VERSION ""

NS_ :

BS_:

BU_: APIM_CISM APIM ESPM DSP FCIMB RACM_RCIM HUD_ADV WCM TRM_ITRM ACM GWM _delete IPC GENERIC TSTR

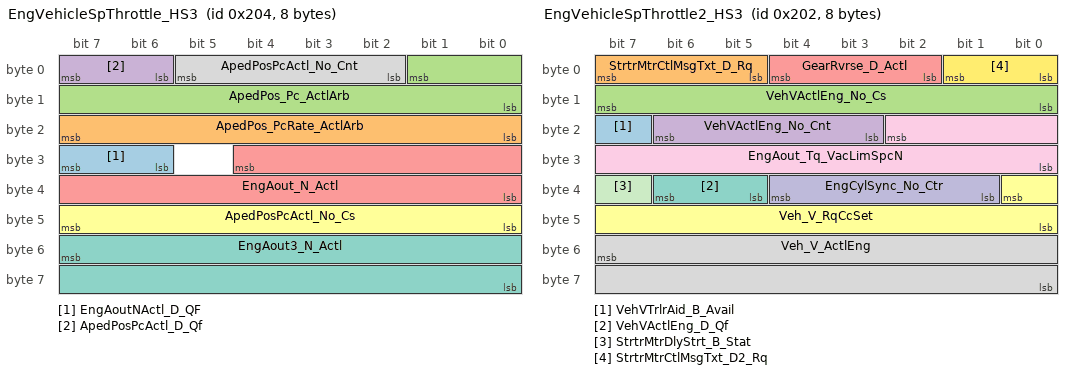
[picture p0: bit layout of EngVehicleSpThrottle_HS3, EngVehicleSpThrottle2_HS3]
BO_ 516 EngVehicleSpThrottle_HS3: 8 GWM
 SG_ EngAoutNActl_D_QF : 31|2@0+ (1,0) [0|3] "SED"  GENERIC
 SG_ ApedPos_PcRate_ActlArb : 23|8@0+ (0.04,-5) [-5|5.12] "%/ms"  APIM_CISM,ACM
 SG_ ApedPos_Pc_ActlArb : 1|10@0+ (0.1,0) [0|102.3] "%"  APIM,APIM_CISM,ACM
 SG_ ApedPosPcActl_D_Qf : 7|2@0+ (1,0) [0|3] "SED"  ACM
 SG_ EngAout_N_Actl : 28|13@0+ (2,0) [0|16382] "rpm"  APIM,APIM_CISM,DSP,ACM,IPC
 SG_ ApedPosPcActl_No_Cs : 47|8@0+ (1,0) [0|255] "unitless"  GENERIC
 SG_ EngAout3_N_Actl : 55|16@0+ (0.25,0) [0|16383.5] "RPM"  GENERIC
 SG_ ApedPosPcActl_No_Cnt : 5|4@0+ (1,0) [0|15] "unitless"  GENERIC

BO_ 514 EngVehicleSpThrottle2_HS3: 8 GWM
 SG_ VehVTrlrAid_B_Avail : 23|1@0+ (1,0) [0|1] "SED"  GENERIC
 SG_ StrtrMtrCtlMsgTxt_D_Rq : 7|3@0+ (1,0) [0|7] "SED"  IPC
 SG_ VehVActlEng_No_Cs : 15|8@0+ (1,0) [0|255] "unitless"  GENERIC
 SG_ VehVActlEng_No_Cnt : 22|4@0+ (1,0) [0|15] "unitless"  GENERIC
 SG_ GearRvrse_D_Actl : 4|3@0+ (1,0) [0|7] "SED"  APIM,HUD_ADV,APIM_CISM,IPC
 SG_ Veh_V_RqCcSet : 32|9@0+ (0.5,0) [0|255.5] "kph"  IPC
 SG_ VehVActlEng_D_Qf : 38|2@0+ (1,0) [0|3] "SED"  APIM,APIM_CISM,WCM,DSP,ACM,IPC
 SG_ Veh_V_ActlEng : 55|16@0+ (0.01,0) [0|655.35] "kph"  APIM,APIM_CISM,WCM,DSP,TRM_ITRM,ACM,IPC
 SG_ EngAout_Tq_VacLimSpcN : 18|11@0+ (1,-500) [-500|1547] "Nm"  GENERIC
 SG_ EngCylSync_No_Ctr : 36|4@0+ (1,0) [0|15] "unitless"  GENERIC
 SG_ StrtrMtrDlyStrt_B_Stat : 39|1@0+ (1,0) [0|1] "SED"  GENERIC
 SG_ StrtrMtrCtlMsgTxt_D2_Rq : 1|2@0+ (1,0) [0|3] "SED"  IPC

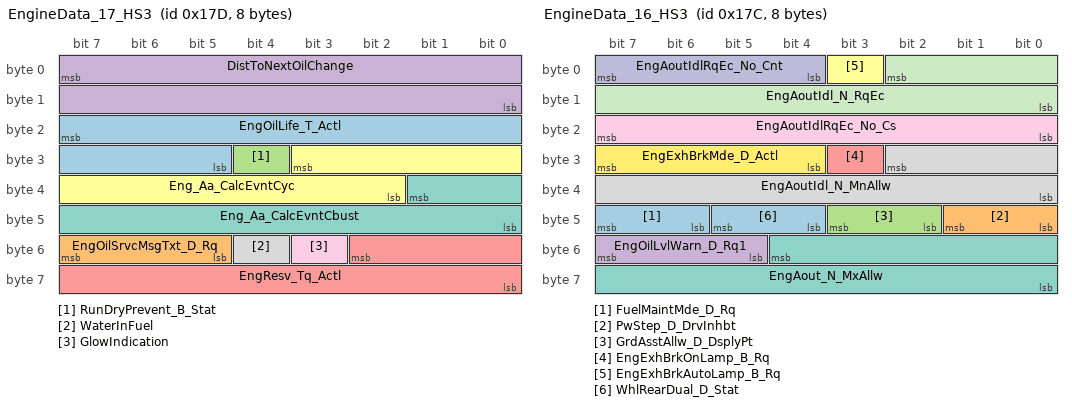
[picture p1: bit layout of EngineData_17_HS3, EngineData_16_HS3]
BO_ 381 EngineData_17_HS3: 8 GWM
 SG_ EngOilLife_T_Actl : 23|11@0+ (1,0) [0|2047] "day"  IPC
 SG_ EngOilSrvcMsgTxt_D_Rq : 55|3@0+ (1,0) [0|7] "SED"  APIM_CISM,IPC
 SG_ RunDryPrevent_B_Stat : 28|1@0+ (1,0) [0|1] "SED"  APIM_CISM,IPC
 SG_ DistToNextOilChange : 7|16@0+ (1,0) [0|65535] "unitless"  IPC
 SG_ EngResv_Tq_Actl : 50|11@0+ (1,-500) [-500|1547] "Nm"  IPC
 SG_ Eng_Aa_CalcEvntCyc : 27|10@0+ (0.05,-25.6) [-25.6|25.55] "rpm/ms"  IPC
 SG_ Eng_Aa_CalcEvntCbust : 33|10@0+ (0.05,-25.6) [-25.6|25.55] "rpm/ms"  IPC
 SG_ WaterInFuel : 52|1@0+ (1,0) [0|1] "SED"  IPC
 SG_ GlowIndication : 51|1@0+ (1,0) [0|1] "SED"  IPC

BO_ 380 EngineData_16_HS3: 8 GWM
 SG_ FuelMaintMde_D_Rq : 47|2@0+ (1,0) [0|3] "SED"  GENERIC
 SG_ PwStep_D_DrvInhbt : 41|2@0+ (1,0) [0|3] "SED" Vector__XXX
 SG_ GrdAsstAllw_D_DsplyPt : 43|2@0+ (1,0) [0|3] "SED"  IPC
 SG_ EngOilLvlWarn_D_Rq1 : 55|3@0+ (1,0) [0|7] "SED"  IPC
 SG_ EngExhBrkOnLamp_B_Rq : 27|1@0+ (1,0) [0|1] "SED"  IPC
 SG_ EngExhBrkAutoLamp_B_Rq : 3|1@0+ (1,0) [0|1] "SED"  IPC
 SG_ EngAout_N_MxAllw : 52|13@0+ (2,0) [0|16382] "rpm"  IPC
 SG_ EngAoutIdl_N_MnAllw : 26|11@0+ (2,0) [0|4094] "rpm"  IPC
 SG_ EngAoutIdlRqEc_No_Cs : 23|8@0+ (1,0) [0|255] "Unitless"  GENERIC
 SG_ EngAoutIdlRqEc_No_Cnt : 7|4@0+ (1,0) [0|15] "Unitless"  GENERIC
 SG_ EngAoutIdl_N_RqEc : 2|11@0+ (2,0) [0|4094] "rpm"  IPC
 SG_ EngExhBrkMde_D_Actl : 31|4@0+ (1,0) [0|15] "SED"  IPC
 SG_ WhlRearDual_D_Stat : 45|2@0+ (1,0) [0|3] "SED"  GENERIC

BO_ 377 EngineData_7_HS3: 8 GWM
 SG_ TrnManShif_D_IndDrv : 7|3@0+ (1,0) [0|7] "unitless"  HUD_ADV,IPC
 SG_ HvacAirFullOut_B_Rq : 23|1@0+ (1,0) [0|1] "SED"  GENERIC
 SG_ EngFuelCutFull_B_Inhbt : 22|1@0+ (1,0) [0|1] "SED"  IPC
 SG_ EngDecelFuelCut_B_Allw : 21|1@0+ (1,0) [0|1] "SED"  IPC
 SG_ EngAout_Tq_Actl : 2|11@0+ (1,-500) [-500|1547] "Nm"  APIM,APIM_CISM,ACM
 SG_ TrnManShifGear_D_IndDrv : 54|3@0+ (1,0) [0|7] "SED"  HUD_ADV,IPC
 SG_ FuelFlw_Vl_Dsply : 49|10@0+ (25,0) [0|25575] "Micro_Liter"  APIM,APIM_CISM,IPC
 SG_ FuelFillInlet_B_Dsply : 32|1@0+ (1,0) [0|1] "SED"  IPC
 SG_ EngSrvcRqd_B_Rq : 19|1@0+ (1,0) [0|1] "SED"  IPC
 SG_ OdoCount : 47|8@0+ (0.2,0) [0|50.8] "Meters"  APIM,APIM_CISM,IPC
 SG_ EngOilLife_Pc_Actl : 39|7@0+ (1,0) [0|100] "percent"  APIM,APIM_CISM,IPC
 SG_ EngTqSlwDly_T_Est : 18|11@0+ (1,0) [0|2047] "ms"  IPC
 SG_ TrnKickDown_B_RqDrv : 20|1@0+ (1,0) [0|1] "SED"  IPC
 SG_ FuelFilterLamp_B_Dsply : 50|1@0+ (1,0) [0|1] "SED"  IPC
 SG_ AirCondRec_B_Rq : 55|1@0+ (1,0) [0|1] "SED"  IPC
 SG_ AirCondClutch_B_Stats : 51|1@0+ (1,0) [0|1] "SED"  WCM,IPC
 SG_ EngAoutTqActl_D_Qf : 4|2@0+ (1,0) [0|3] "SED" Vector__XXX

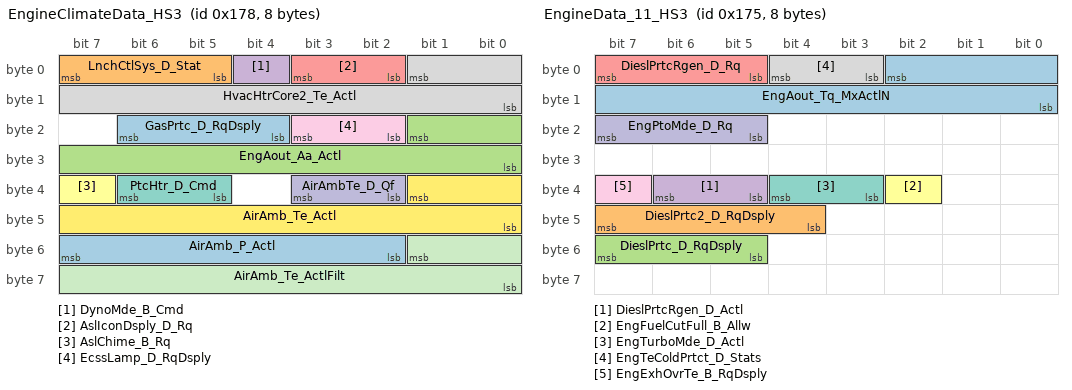
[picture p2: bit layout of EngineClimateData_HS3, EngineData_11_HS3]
BO_ 376 EngineClimateData_HS3: 8 GWM
 SG_ GasPrtc_D_RqDsply : 22|3@0+ (1,0) [0|7] "SED"  IPC
 SG_ LnchCtlSys_D_Stat : 7|3@0+ (1,0) [0|7] "SED"  IPC
 SG_ EngAout_Aa_Actl : 17|10@0+ (0.05,-25.6) [-25.6|25.55] "rpm/ms"  GENERIC
 SG_ DynoMde_B_Cmd : 4|1@0+ (1,0) [0|1] "SED"  GENERIC
 SG_ AslIconDsply_D_Rq : 3|2@0+ (1,0) [0|3] "SED"  APIM,APIM_CISM,IPC
 SG_ AslChime_B_Rq : 39|1@0+ (1,0) [0|1] "SED"  IPC
 SG_ PtcHtr_D_Cmd : 38|2@0+ (1,0) [0|3] "SED"  GENERIC
 SG_ HvacHtrCore2_Te_Actl : 1|10@0+ (0.25,-50) [-50|205.5] "degC"  IPC
 SG_ EcssLamp_D_RqDsply : 19|2@0+ (1,0) [0|3] "SED"  IPC
 SG_ AirAmbTe_D_Qf : 35|2@0+ (1,0) [0|3] "SED"  IPC
 SG_ AirAmb_Te_ActlFilt : 49|10@0+ (0.25,-128) [-128|127.75] "degC"  IPC
 SG_ AirAmb_Te_Actl : 33|10@0+ (0.25,-128) [-128|127.75] "degC"  IPC
 SG_ AirAmb_P_Actl : 55|6@0+ (10,500) [500|1110] "mbar"  APIM,APIM_CISM,IPC

BO_ 373 EngineData_11_HS3: 8 GWM
 SG_ EngAout_Tq_MxActlN : 2|11@0+ (1,-500) [-500|1547] "Nm" Vector__XXX
 SG_ DieslPrtc2_D_RqDsply : 47|4@0+ (1,0) [0|15] "SED"  APIM_CISM,IPC
 SG_ DieslPrtc_D_RqDsply : 55|3@0+ (1,0) [0|7] "SED"  APIM_CISM,IPC
 SG_ DieslPrtcRgen_D_Actl : 38|2@0+ (1,0) [0|3] "SED"  IPC
 SG_ DieslPrtcRgen_D_Rq : 7|3@0+ (1,0) [0|7] "SED"  APIM_CISM,IPC
 SG_ EngFuelCutFull_B_Allw : 34|1@0+ (1,0) [0|1] "SED"  GENERIC
 SG_ EngTurboMde_D_Actl : 36|2@0+ (1,0) [0|3] "SED"  IPC
 SG_ EngTeColdPrtct_D_Stats : 4|2@0+ (1,0) [0|3] "SED"  IPC
 SG_ EngExhOvrTe_B_RqDsply : 39|1@0+ (1,0) [0|1] "SED"  IPC
 SG_ EngPtoMde_D_Rq : 23|3@0+ (1,0) [0|7] "SED"  IPC

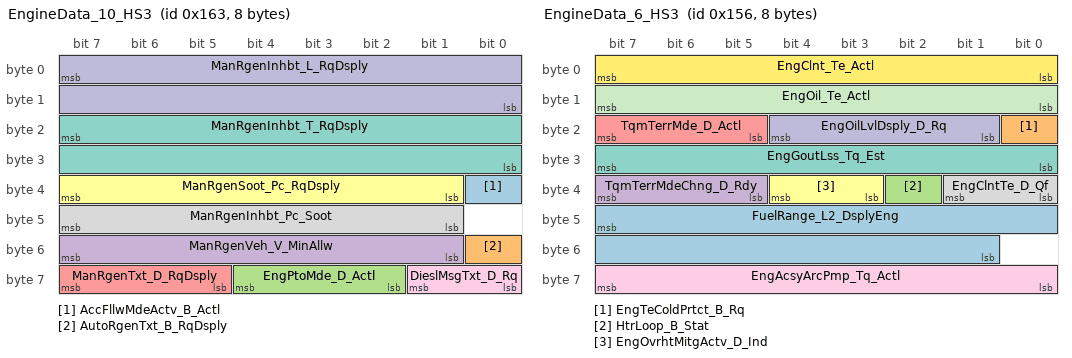
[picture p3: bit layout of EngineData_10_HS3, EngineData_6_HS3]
BO_ 355 EngineData_10_HS3: 8 GWM
 SG_ AccFllwMdeActv_B_Actl : 32|1@0+ (1,0) [0|1] "SED"  GENERIC
 SG_ AutoRgenTxt_B_RqDsply : 48|1@0+ (1,0) [0|1] "SED"  IPC
 SG_ EngPtoMde_D_Actl : 60|3@0+ (1,0) [0|7] "SED"  IPC
 SG_ ManRgenVeh_V_MinAllw : 55|7@0+ (1,0) [0|126] "kilometer/hour"  APIM_CISM,IPC
 SG_ ManRgenTxt_D_RqDsply : 63|3@0+ (1,0) [0|7] "SED"  APIM_CISM,IPC
 SG_ ManRgenSoot_Pc_RqDsply : 39|7@0+ (1,0) [0|126] "%"  APIM_CISM,IPC
 SG_ ManRgenInhbt_T_RqDsply : 23|16@0+ (1,0) [0|65534] "minute"  APIM_CISM,IPC
 SG_ ManRgenInhbt_Pc_Soot : 47|7@0+ (1,0) [0|126] "%"  APIM_CISM,IPC
 SG_ DieslMsgTxt_D_Rq : 57|2@0+ (1,0) [0|3] "SED"  IPC
 SG_ ManRgenInhbt_L_RqDsply : 7|16@0+ (1,0) [0|65534] "kilometer"  APIM_CISM,IPC

BO_ 342 EngineData_6_HS3: 8 GWM
 SG_ FuelRange_L2_DsplyEng : 47|15@0+ (0.1,0) [0|3276.7] "kilometer"  IPC
 SG_ EngTeColdPrtct_B_Rq : 16|1@0+ (1,0) [0|1] "SED"  IPC
 SG_ HtrLoop_B_Stat : 34|1@0+ (1,0) [0|1] "SED"  IPC
 SG_ TqmTerrMdeChng_D_Rdy : 39|3@0+ (1,0) [0|7] "SED"  IPC
 SG_ TqmTerrMde_D_Actl : 23|3@0+ (1,0) [0|7] "SED"  IPC
 SG_ EngOvrhtMitgActv_D_Ind : 36|2@0+ (1,0) [0|3] "SED"  IPC
 SG_ EngGoutLss_Tq_Est : 31|8@0+ (1,0) [0|255] "Nm"  IPC
 SG_ EngClntTe_D_Qf : 33|2@0+ (1,0) [0|3] "SED"  IPC
 SG_ EngAcsyArcPmp_Tq_Actl : 63|8@0+ (0.5,0) [0|126.5] "Nm"  IPC
 SG_ EngOilLvlDsply_D_Rq : 20|4@0+ (1,0) [0|15] "SED"  IPC
 SG_ EngOil_Te_Actl : 15|8@0+ (1,-60) [-60|193] "degC"  APIM,APIM_CISM,IPC
 SG_ EngClnt_Te_Actl : 7|8@0+ (1,-60) [-60|195] "degC"  APIM,APIM_CISM,IPC

BO_ 707 SSPClnt_SSPSrv_WORD_Tx: 8 ACM
 SG_ SSPClnt_SSPSrv_WORD_Tx : 7|64@0+ (1,0) [0|1.84467440737096E+019] "unitless"  APIM

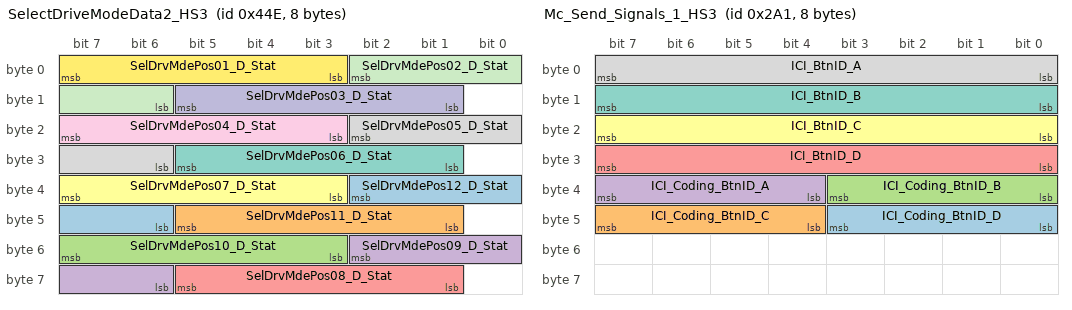
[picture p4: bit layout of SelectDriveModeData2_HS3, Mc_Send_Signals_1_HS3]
BO_ 1102 SelectDriveModeData2_HS3: 8 GWM
 SG_ SelDrvMdePos12_D_Stat : 34|5@0+ (1,0) [0|31] "SED"  APIM,APIM_CISM,IPC
 SG_ SelDrvMdePos11_D_Stat : 45|5@0+ (1,0) [0|31] "SED"  APIM,APIM_CISM,IPC
 SG_ SelDrvMdePos10_D_Stat : 55|5@0+ (1,0) [0|31] "SED"  APIM,APIM_CISM,IPC
 SG_ SelDrvMdePos09_D_Stat : 50|5@0+ (1,0) [0|31] "SED"  APIM,APIM_CISM,IPC
 SG_ SelDrvMdePos08_D_Stat : 61|5@0+ (1,0) [0|31] "SED"  APIM,APIM_CISM,IPC
 SG_ SelDrvMdePos07_D_Stat : 39|5@0+ (1,0) [0|31] "SED"  APIM,APIM_CISM,IPC
 SG_ SelDrvMdePos06_D_Stat : 29|5@0+ (1,0) [0|31] "SED"  APIM,APIM_CISM,IPC
 SG_ SelDrvMdePos05_D_Stat : 18|5@0+ (1,0) [0|31] "SED"  APIM,APIM_CISM,IPC
 SG_ SelDrvMdePos04_D_Stat : 23|5@0+ (1,0) [0|31] "SED"  APIM,APIM_CISM,IPC
 SG_ SelDrvMdePos03_D_Stat : 13|5@0+ (1,0) [0|31] "SED"  APIM,APIM_CISM,IPC
 SG_ SelDrvMdePos02_D_Stat : 2|5@0+ (1,0) [0|31] "SED"  APIM,APIM_CISM,IPC
 SG_ SelDrvMdePos01_D_Stat : 7|5@0+ (1,0) [0|31] "SED"  APIM,APIM_CISM,IPC

BO_ 551 APIM_Request_Signals_1: 8 APIM
 SG_ PrkBrkPerfMnuOn_D_Stat : 1|2@0+ (1,0) [0|3] "SED"  GWM
 SG_ PrkBrkPerfButtn_D_Stat : 3|2@0+ (1,0) [0|3] "SED"  GWM
 SG_ EcoIdl_D_Rq : 7|2@0+ (1,0) [0|3] "SED"  GWM
 SG_ Rba_D_Rq : 31|2@0+ (1,0) [0|3] "SED"  GWM
 SG_ OneTEditActv_B_RqMnu : 40|1@0+ (1,0) [0|1] "SED"  GWM
 SG_ GoTElementEdit_No_RqMnu : 12|4@0+ (1,0) [0|15] "unitless"  GWM
 SG_ ChrgToPcEdit_Pc_RqMnu : 23|7@0+ (1,0) [0|125] "percent"  GWM
 SG_ PrcondEdit_D_RqMnu : 15|3@0+ (1,0) [0|7] "SED"  GWM
 SG_ BattTracLoThres_D_Rq : 43|3@0+ (1,0) [0|7] "SED"  GWM
 SG_ EmPrflNo_D_Rq : 61|3@0+ (1,0) [0|7] "SED"  GWM
 SG_ EmPrflButtnAssoc_D_Rq : 33|2@0+ (1,0) [0|3] "SED"  GWM
 SG_ EmPrflKeyAssoc_D_Rq : 46|3@0+ (1,0) [0|7] "SED"  GWM
 SG_ Em_D_Stat : 63|2@0+ (1,0) [0|3] "SED"  GWM
 SG_ PmCabnLvl_D_Stat : 36|3@0+ (1,0) [0|7] "SED"  RACM_RCIM,GWM
 SG_ PmCabn_D_Stat : 38|2@0+ (1,0) [0|3] "SED"  RACM_RCIM,GWM
 SG_ Cntr_Plg_Mode_Cmd : 39|1@0+ (1,0) [0|1] "SED"  GWM
 SG_ Btt_L_Actl2 : 55|7@0+ (0.1,0) [0|12.5] "meter"  GWM
 SG_ ChrgCrdLckEnbl_B_Stat : 47|1@0+ (1,0) [0|1] "SED"  GWM
 SG_ PwRnngBoardT_D_Rq : 25|2@0+ (1,0) [0|3] "SED"  GWM
 SG_ PwRnngBoardMde_D_Rq : 29|2@0+ (1,0) [0|3] "SED"  GWM
 SG_ PwRnngBoardSwtch_D_Rq : 27|2@0+ (1,0) [0|3] "SED"  GWM
 SG_ ChrgOvrdExitScrn_D_Rq : 58|2@0+ (1,0) [0|3] "SED"  GWM
 SG_ TjaLaneBiasEnbl_D_RqMnu : 5|2@0+ (1,0) [0|3] "SED"  GWM

BO_ 673 Mc_Send_Signals_1_HS3: 8 GWM
 SG_ ICI_Coding_BtnID_D : 43|4@0+ (1,0) [0|15] "SED"  APIM,APIM_CISM,HUD_ADV,IPC
 SG_ ICI_Coding_BtnID_C : 47|4@0+ (1,0) [0|15] "SED"  APIM,APIM_CISM,HUD_ADV,IPC
 SG_ ICI_Coding_BtnID_B : 35|4@0+ (1,0) [0|15] "SED"  APIM,APIM_CISM,HUD_ADV,IPC
 SG_ ICI_Coding_BtnID_A : 39|4@0+ (1,0) [0|15] "SED"  APIM,APIM_CISM,HUD_ADV,IPC
 SG_ ICI_BtnID_D : 31|8@0+ (1,0) [0|255] "unitless"  APIM,APIM_CISM,HUD_ADV,IPC
 SG_ ICI_BtnID_C : 23|8@0+ (1,0) [0|255] "unitless"  APIM,APIM_CISM,HUD_ADV,IPC
 SG_ ICI_BtnID_B : 15|8@0+ (1,0) [0|255] "unitless"  APIM,APIM_CISM,HUD_ADV,IPC
 SG_ ICI_BtnID_A : 7|8@0+ (1,0) [0|255] "unitless"  APIM,APIM_CISM,HUD_ADV,IPC

BO_ 963 BCM_Lamp_Stat_HS3: 8 GWM
 SG_ Illuminated_Entry_Stat : 63|2@0+ (1,0) [0|3] "SED" Vector__XXX
 SG_ Dr_Courtesy_Light_Stat : 49|2@0+ (1,0) [0|3] "SED" Vector__XXX
 SG_ Courtesy_Delay_Status : 51|2@0+ (1,0) [0|3] "SED" Vector__XXX
 SG_ ImpactEvntFdbck_D_Stat : 53|2@0+ (1,0) [0|3] "SED" Vector__XXX
 SG_ WrlssAcsyChrgInhbt_B_Rq : 40|1@0+ (1,0) [0|1] "SED"  WCM
 SG_ PudLampPsngr_D_Rq : 57|2@0+ (1,0) [0|3] "SED" Vector__XXX
 SG_ HeadLampLoOut_B_Stat : 32|1@0+ (1,0) [0|1] "SED"  IPC
 SG_ CrnrLghtRight_Pc_Rq : 47|7@0+ (1,0) [0|100] "percent" Vector__XXX
 SG_ CrnrLghtLeft_Pc_Rq : 39|7@0+ (1,0) [0|100] "percent" Vector__XXX
 SG_ HeadLghtHiFdbck_D_Stat : 55|2@0+ (1,0) [0|3] "SED" Vector__XXX
 SG_ PrkLightChime_B_Rq : 25|1@0+ (1,0) [0|1] "SED"  IPC
 SG_ TrnNotInPrkChime_B_Rq : 24|1@0+ (1,0) [0|1] "SED"  IPC
 SG_ KeyInIgnWarn_B_Cmd : 27|1@0+ (1,0) [0|1] "SED"  IPC
 SG_ HomeSafeLtChime_B_Rq : 28|1@0+ (1,0) [0|1] "SED"  IPC
 SG_ StopLghtOn_B_Stat : 8|1@0+ (1,0) [0|1] "SED"  TRM_ITRM
 SG_ RvrseLghtOn_B_Stat : 9|1@0+ (1,0) [0|1] "SED"  APIM,APIM_CISM,TRM_ITRM
 SG_ PrkLght_D_Stat : 13|2@0+ (1,0) [0|3] "SED"  TRM_ITRM
 SG_ HeadLghtSwtch_D_Stat : 15|2@0+ (1,0) [0|3] "SED"  IPC
 SG_ HeadLampLoFrOn_B_Stat : 2|1@0+ (1,0) [0|1] "SED" Vector__XXX
 SG_ HeadLampLoFlOn_B_Stat : 3|1@0+ (1,0) [0|1] "SED" Vector__XXX
 SG_ HeadLampLoActv_B_Stat : 4|1@0+ (1,0) [0|1] "SED"  APIM,APIM_CISM
 SG_ Headlamp_On_Wrning_Cmd : 29|1@0+ (1,0) [0|1] "SED"  IPC
 SG_ HeadLghtHiOn_B_Stat : 1|1@0+ (1,0) [0|1] "SED"  APIM,APIM_CISM,IPC
 SG_ Park_Brake_Chime_Rqst : 26|1@0+ (1,0) [0|1] "SED"  IPC
 SG_ BrkWarnInd_B_Rq : 20|1@0+ (1,0) [0|1] "SED"  IPC
 SG_ Brk_Fluid_Lvl_Low : 31|2@0+ (1,0) [0|3] "SED"  IPC
 SG_ ReducedGuard_D_Stat : 19|2@0+ (1,0) [0|3] "SED"  IPC
 SG_ PudLampDrv_D_Rq : 59|2@0+ (1,0) [0|3] "SED" Vector__XXX
 SG_ Courtesy_BSave_Stat : 7|2@0+ (1,0) [0|3] "SED"  TRM_ITRM,ACM
 SG_ DayRnngLampOn_B_Stat : 5|1@0+ (1,0) [0|1] "SED"  IPC
 SG_ PerimeterAlarmChimeRq : 0|1@0+ (1,0) [0|1] "SED"  IPC
 SG_ Perimeter_Alarm_Status : 17|2@0+ (1,0) [0|3] "SED"  TRM_ITRM
 SG_ WndwGlbl_D_Cmd : 23|3@0+ (1,0) [0|7] "SED" Vector__XXX
 SG_ DrTgateLck_D_Stat : 61|2@0+ (1,0) [0|3] "SED"  IPC
 SG_ PudLamp_D_Rq : 11|2@0+ (1,0) [0|3] "SED"  APIM,APIM_CISM,HUD_ADV

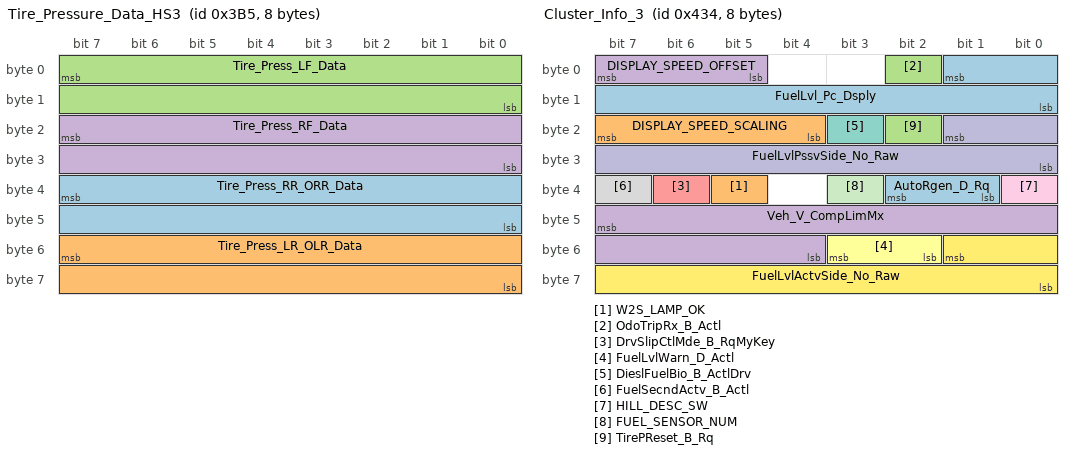
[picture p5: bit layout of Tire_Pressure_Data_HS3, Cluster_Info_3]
BO_ 949 Tire_Pressure_Data_HS3: 8 GWM
 SG_ Tire_Press_RR_ORR_Data : 39|16@0+ (1,0) [0|65533] "kilopascal"  APIM,APIM_CISM,IPC
 SG_ Tire_Press_LR_OLR_Data : 55|16@0+ (1,0) [0|65533] "kilopascal"  APIM,APIM_CISM,IPC
 SG_ Tire_Press_LF_Data : 7|16@0+ (1,0) [0|65533] "kilopascal"  APIM,APIM_CISM,IPC
 SG_ Tire_Press_RF_Data : 23|16@0+ (1,0) [0|65533] "kilopascal"  APIM,APIM_CISM,IPC

BO_ 2015 TesterFunctionalReq_H3: 8 TSTR
 SG_ TesterFunctionalReq : 7|64@0+ (1,0) [0|1.84467E+019] "unitless"  APIM,APIM_CISM,ESPM,RACM_RCIM,TRM_ITRM,DSP,FCIMB,HUD_ADV,WCM,ACM,IPC,GWM

BO_ 1076 Cluster_Info_3: 8 IPC
 SG_ AutoRgen_D_Rq : 34|2@0+ (1,0) [0|3] "SED"  GWM
 SG_ W2S_LAMP_OK : 37|1@0+ (1,0) [0|1] "SED"  GWM
 SG_ OdoTripRx_B_Actl : 2|1@0+ (1,0) [0|1] "SED"  GWM
 SG_ Veh_V_CompLimMx : 47|12@0+ (0.1,0) [0|409.5] "km/h"  GWM
 SG_ DrvSlipCtlMde_B_RqMyKey : 38|1@0+ (1,0) [0|1] "SED"  GWM
 SG_ FuelLvlWarn_D_Actl : 51|2@0+ (1,0) [0|3] "SED"  APIM,APIM_CISM,HUD_ADV,GWM
 SG_ DieslFuelBio_B_ActlDrv : 19|1@0+ (1,0) [0|1] "SED"  GWM
 SG_ FuelSecndActv_B_Actl : 39|1@0+ (1,0) [0|1] "SED"  GWM
 SG_ HILL_DESC_SW : 32|1@0+ (1,0) [0|1] "SED"  GWM
 SG_ FuelLvlPssvSide_No_Raw : 17|10@0+ (1,0) [0|1023] "unitless"  GWM
 SG_ FUEL_SENSOR_NUM : 35|1@0+ (1,0) [0|1] "SED"  GWM
 SG_ FuelLvlActvSide_No_Raw : 49|10@0+ (1,0) [0|1023] "unitless"  GWM
 SG_ FuelLvl_Pc_Dsply : 1|10@0+ (0.108696,-5.217408) [-5.217408|105.9786] "Percent"  APIM,APIM_CISM,GWM
 SG_ DISPLAY_SPEED_SCALING : 23|4@0+ (0.5,100) [100|107.5] "%"  GWM
 SG_ TirePReset_B_Rq : 18|1@0+ (1,0) [0|1] "SED"  GWM
 SG_ DISPLAY_SPEED_OFFSET : 7|3@0+ (0.5,0) [0|3.5] "kph"  GWM

BO_ 974 DCACA_Data4_HS3: 8 GWM
 SG_ PwBedPnlEnblScnd_B_Rq : 48|1@0+ (1,0) [0|1] "SED" Vector__XXX
 SG_ DcacSysScnd_B_Falt : 40|1@0+ (1,0) [0|1] "SED" Vector__XXX
 SG_ DcacOnScnd_B_Rq : 32|1@0+ (1,0) [0|1] "SED" Vector__XXX
 SG_ DcacGfciTestScnd_B_Rq : 24|1@0+ (1,0) [0|1] "SED" Vector__XXX
 SG_ DcacGfciTest_B_Rq : 0|1@0+ (1,0) [0|1] "SED" Vector__XXX
 SG_ EngExhMdeHrStrt_D_Stat : 53|5@0+ (1,0) [0|31] "SED"  APIM,APIM_CISM
 SG_ EngExhMdeHrEnd_D_Stat : 63|5@0+ (1,0) [0|31] "SED"  APIM,APIM_CISM
 SG_ EngExhMdeHrEnbl_D_Stat : 58|2@0+ (1,0) [0|3] "SED"  APIM,APIM_CISM
 SG_ DcacOut_Pw_DsplyMx : 23|10@0+ (10,0) [0|10220] "watts"  APIM,APIM_CISM
 SG_ DcacOut1_Pw_Dsply : 39|7@0+ (100,0) [0|12600] "watts"  APIM,APIM_CISM
 SG_ DcacOut2_Pw_Dsply : 47|7@0+ (100,0) [0|12600] "watts"  APIM,APIM_CISM
 SG_ DcacHw_D_Confg : 11|4@0+ (1,0) [0|15] "SED"  APIM,APIM_CISM
 SG_ DcacFaltMsgTxt_D_Rq : 15|4@0+ (1,0) [0|15] "SED"  APIM,APIM_CISM
 SG_ DcacLoFuelMsgTxt_D_Rq : 29|5@0+ (1,0) [0|31] "SED"  APIM,APIM_CISM
 SG_ DcacEngOnMsgTxt_D_Rq : 55|2@0+ (1,0) [0|3] "SED"  APIM,APIM_CISM
 SG_ DcacElPw_D_Stat : 2|2@0+ (1,0) [0|3] "SED"  APIM,APIM_CISM
 SG_ PwBedPnlEnbl_B_Rq : 3|1@0+ (1,0) [0|1] "SED"  GENERIC
 SG_ DcacOn_B_Rq : 4|1@0+ (1,0) [0|1] "SED"  GENERIC
 SG_ DcacSys_B_Falt : 5|1@0+ (1,0) [0|1] "SED"  GENERIC
 SG_ DcacLedCtl_D_Rq : 7|2@0+ (1,0) [0|3] "SED"  GENERIC

BO_ 810 ECG_Data_HS3: 8 GWM
 SG_ OneTEditActv_B_RqCld : 32|1@0+ (1,0) [0|1] "SED"  APIM,APIM_CISM
 SG_ ExtLghtDsply_B_StatArb : 7|1@0+ (1,0) [0|1] "SED"  APIM,APIM_CISM

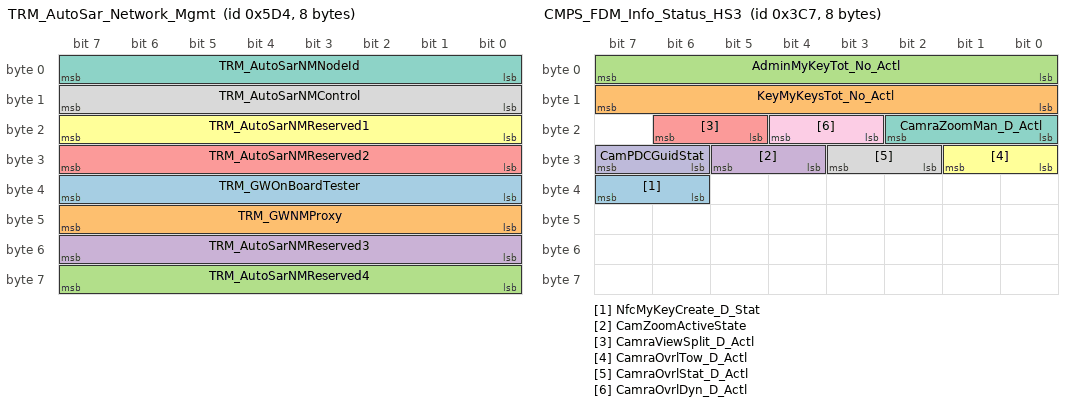
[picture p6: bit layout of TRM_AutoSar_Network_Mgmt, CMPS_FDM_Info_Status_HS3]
BO_ 1492 TRM_AutoSar_Network_Mgmt: 8 TRM_ITRM
 SG_ TRM_GWOnBoardTester : 39|8@0+ (1,0) [0|255] "unitless"  GENERIC
 SG_ TRM_GWNMProxy : 47|8@0+ (1,0) [0|255] "unitless"  GENERIC
 SG_ TRM_AutoSarNMReserved4 : 63|8@0+ (1,0) [0|255] "unitless"  GENERIC
 SG_ TRM_AutoSarNMReserved3 : 55|8@0+ (1,0) [0|255] "unitless"  GENERIC
 SG_ TRM_AutoSarNMReserved2 : 31|8@0+ (1,0) [0|255] "unitless"  GENERIC
 SG_ TRM_AutoSarNMReserved1 : 23|8@0+ (1,0) [0|255] "unitless"  GENERIC
 SG_ TRM_AutoSarNMNodeId : 7|8@0+ (1,0) [0|255] "unitless"  GENERIC
 SG_ TRM_AutoSarNMControl : 15|8@0+ (1,0) [0|255] "unitless"  GENERIC

BO_ 709 DSPAMP_RDISP_WORD_Tx: 8 DSP
 SG_ DSPAMP_RDISP_WORD_Tx : 7|64@0+ (1,0) [0|1.84467440737096E+019] "unitless"  APIM,APIM_CISM

BO_ 552 DSPAMP_Send_Signals: 8 DSP
 SG_ ActvNseMute_D_Stat : 58|2@0+ (1,0) [0|3] "SED"  APIM,APIM_CISM
 SG_ DSP_Treble_St : 55|4@0+ (1,-7) [-7|8] "unitless"  APIM,APIM_CISM
 SG_ DSP_VoiceFBVolume_Up : 35|1@0+ (1,0) [0|1] "SED"  APIM,APIM_CISM,IPC,HUD_ADV
 SG_ DSP_VoiceFBVolume_St : 63|5@0+ (1,0) [0|30] "unitless"  APIM,APIM_CISM,IPC,HUD_ADV,WCM
 SG_ DSP_TAVolume_Up : 34|1@0+ (1,0) [0|1] "SED"  APIM,APIM_CISM,IPC,HUD_ADV
 SG_ DSP_TAVolume_St : 44|5@0+ (1,0) [0|30] "unitless"  APIM,APIM_CISM,IPC,HUD_ADV,WCM
 SG_ DSP_Shaker_St : 1|1@0+ (1,0) [0|1] "SED"  APIM,APIM_CISM
 SG_ DSP_Reg_St : 27|2@0+ (1,0) [0|3] "SED"  APIM,APIM_CISM
 SG_ DSP_PhoneVolume_Up : 25|1@0+ (1,0) [0|1] "SED"  APIM,APIM_CISM,IPC,HUD_ADV
 SG_ DSP_PhoneVolume_St : 33|5@0+ (1,0) [0|30] "unitless"  APIM,APIM_CISM,IPC,HUD_ADV,WCM
 SG_ DSP_NavCmdVolume_Up : 7|1@0+ (1,0) [0|1] "SED"  APIM,APIM_CISM,IPC,HUD_ADV
 SG_ DSP_NavCmdVolume_St : 24|5@0+ (1,0) [0|30] "SED"  APIM,APIM_CISM,IPC,HUD_ADV,WCM
 SG_ DSP_Midrange_St : 51|4@0+ (1,-7) [-7|8] "unitless"  APIM,APIM_CISM
 SG_ DSP_Fader_St : 20|4@0+ (1,-7) [-7|8] "unitless"  APIM,APIM_CISM
 SG_ DSP_DSPProgram_St : 15|3@0+ (1,0) [0|7] "SED"  APIM,APIM_CISM
 SG_ DSP_DSP_St : 16|5@0+ (1,0) [0|31] "SED"  APIM,APIM_CISM
 SG_ DSP_Bass_St : 12|4@0+ (1,-7) [-7|8] "unitless"  APIM,APIM_CISM
 SG_ DSP_Balance_St : 8|4@0+ (1,-7) [-7|8] "unitless"  APIM,APIM_CISM
 SG_ DSP_AVC_St : 6|3@0+ (1,0) [0|7] "SED"  APIM,APIM_CISM
 SG_ Audio_Demo_Status : 0|1@0+ (1,0) [0|1] "SED"  APIM,APIM_CISM

BO_ 967 CMPS_FDM_Info_Status_HS3: 8 GWM
 SG_ NfcMyKeyCreate_D_Stat : 39|2@0+ (1,0) [0|3] "SED"  APIM
 SG_ KeyMyKeysTot_No_Actl : 15|8@0+ (1,0) [0|255] "unitless"  APIM
 SG_ AdminMyKeyTot_No_Actl : 7|8@0+ (1,0) [0|255] "unitless"  APIM
 SG_ CamZoomActiveState : 29|2@0+ (1,0) [0|3] "SED"  APIM,APIM_CISM
 SG_ CamraViewSplit_D_Actl : 22|2@0+ (1,0) [0|3] "SED"  APIM,APIM_CISM
 SG_ CamraOvrlTow_D_Actl : 25|2@0+ (1,0) [0|3] "SED"  APIM,APIM_CISM
 SG_ CamraZoomMan_D_Actl : 18|3@0+ (1,0) [0|7] "SED"  APIM,APIM_CISM
 SG_ CamraOvrlStat_D_Actl : 27|2@0+ (1,0) [0|3] "SED"  APIM,APIM_CISM
 SG_ CamraOvrlDyn_D_Actl : 20|2@0+ (1,0) [0|3] "SED"  APIM,APIM_CISM
 SG_ CamPDCGuidStat : 31|2@0+ (1,0) [0|3] "SED"  APIM,APIM_CISM

BO_ 1105 Image_Processing_Data_HS3: 8 GWM
 SG_ ClrExitAsstActv_B_Rq : 24|1@0+ (1,0) [0|1] "SED"  APIM,APIM_CISM
 SG_ ClrExitAsstMsgTxt2_D_Rq : 55|4@0+ (1,0) [0|15] "SED"  APIM,APIM_CISM
 SG_ TrlrRvrseEnbl_D2_Stat : 18|3@0+ (1,0) [0|7] "SED"  APIM,APIM_CISM,TRM_ITRM,IPC
 SG_ TrlrAidSwtchLamp_B_Rq : 32|1@0+ (1,0) [0|1] "SED"  TRM_ITRM
 SG_ TrlrAidEnbl_D_RqAdas : 5|3@0+ (1,0) [0|7] "SED"  GENERIC
 SG_ TrlrHitchMsgTxt_D_Rq : 47|6@0+ (1,0) [0|63] "SED"  APIM,APIM_CISM
 SG_ TrlrHitchIcon_D_Rq : 36|4@0+ (1,0) [0|15] "SED"  APIM,APIM_CISM
 SG_ CamraFrntOffRd_B_Stat : 25|1@0+ (1,0) [0|1] "SED"  APIM,APIM_CISM
 SG_ TrlrHitchChime_D_Rq : 39|3@0+ (1,0) [0|7] "SED"  IPC
 SG_ TrlrRvrseMsgTxt_D2_Rq : 31|6@0+ (1,0) [0|63] "SED"  APIM,APIM_CISM,TRM_ITRM,IPC
 SG_ RbaMsg_D_Rq : 22|2@0+ (1,0) [0|3] "SED"  IPC
 SG_ BrkDecel_B_RqRba : 8|1@0+ (1,0) [0|1] "SED" Vector__XXX
 SG_ BrkEnbl_B_RqRba : 23|1@0+ (1,0) [0|1] "SED" Vector__XXX
 SG_ Rba_D_Stat : 14|2@0+ (1,0) [0|3] "SED"  APIM,APIM_CISM,IPC
 SG_ RbaAlrt_D_Dsply : 12|2@0+ (1,0) [0|3] "SED"  APIM,APIM_CISM,IPC
 SG_ RbaMnu_D_Rq : 10|2@0+ (1,0) [0|3] "SED"  APIM,APIM_CISM
 SG_ CamraFrntStat_D_Stat : 7|2@0+ (1,0) [0|3] "SED"  APIM,APIM_CISM,FCIMB,ACM,IPC
 SG_ TrlrHitchLamp_D_Rq2 : 15|1@0+ (1,0) [0|1] "SED" Vector__XXX

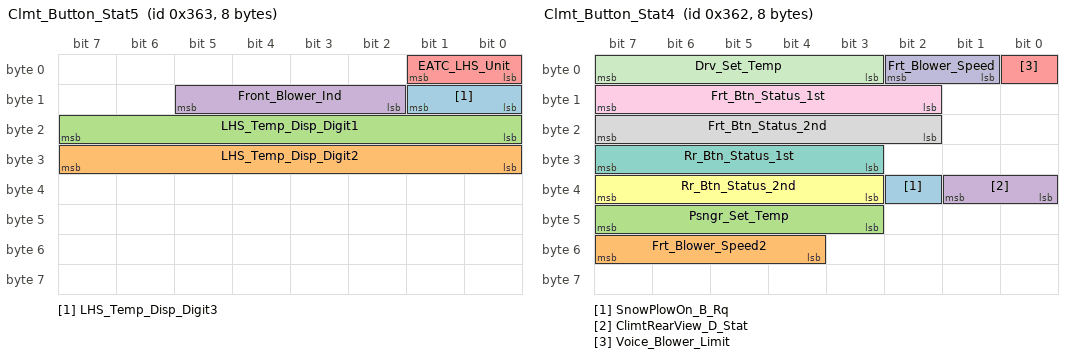
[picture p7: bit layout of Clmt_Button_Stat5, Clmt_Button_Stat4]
BO_ 867 Clmt_Button_Stat5: 8 IPC
 SG_ LHS_Temp_Disp_Digit3 : 9|2@0+ (1,0) [0|3] "SED"  HUD_ADV,GWM
 SG_ LHS_Temp_Disp_Digit2 : 31|8@0+ (1,0) [0|255] "ASCII"  HUD_ADV,GWM
 SG_ LHS_Temp_Disp_Digit1 : 23|8@0+ (1,0) [0|255] "ASCII"  HUD_ADV,GWM
 SG_ Front_Blower_Ind : 13|4@0+ (1,0) [0|15] "SED"  GWM
 SG_ EATC_LHS_Unit : 1|2@0+ (1,0) [0|3] "SED"  HUD_ADV,GWM

BO_ 866 Clmt_Button_Stat4: 8 APIM
 SG_ SnowPlowOn_B_Rq : 34|1@0+ (1,0) [0|1] "SED"  GWM
 SG_ Frt_Blower_Speed2 : 55|4@0+ (1,0) [0|15] "SED"  RACM_RCIM,GWM
 SG_ Psngr_Set_Temp : 47|5@0+ (1,0) [0|31] "SED"  RACM_RCIM,GWM
 SG_ ClimtRearView_D_Stat : 33|2@0+ (1,0) [0|3] "SED"  GWM,RACM_RCIM
 SG_ Voice_Blower_Limit : 0|1@0+ (1,0) [0|1] "SED"  GWM
 SG_ Rr_Btn_Status_2nd : 39|5@0+ (1,0) [0|31] "SED"  RACM_RCIM,GWM
 SG_ Rr_Btn_Status_1st : 31|5@0+ (1,0) [0|31] "SED"  RACM_RCIM,GWM
 SG_ Frt_Btn_Status_2nd : 23|6@0+ (1,0) [0|63] "SED"  ACM,RACM_RCIM,GWM
 SG_ Frt_Btn_Status_1st : 15|6@0+ (1,0) [0|63] "SED"  ACM,RACM_RCIM,GWM
 SG_ Frt_Blower_Speed : 2|2@0+ (1,0) [0|3] "SED"  RACM_RCIM,GWM
 SG_ Drv_Set_Temp : 7|5@0+ (1,0) [0|31] "SED"  RACM_RCIM,GWM

BO_ 861 Clmt_Button_Stat3_HS3: 8 GWM
 SG_ Rr_Temp_Detents : 63|6@0+ (1,0) [0|63] "SED"  APIM,APIM_CISM,RACM_RCIM
 SG_ Rr_Power_Btn_Stt : 57|2@0+ (1,0) [0|3] "SED"  APIM,APIM_CISM,RACM_RCIM
 SG_ Rr_RH_Cond_Seat_Stat : 18|3@0+ (1,0) [0|7] "SED"  APIM,APIM_CISM,RACM_RCIM
 SG_ Rr_Pnl_Flr_Btn_Stt : 33|2@0+ (1,0) [0|3] "SED"  APIM,APIM_CISM,RACM_RCIM
 SG_ Rr_LH_Cond_Seat_Stat : 21|3@0+ (1,0) [0|7] "SED"  APIM,APIM_CISM,RACM_RCIM
 SG_ CC_Rr_Stat_User_Adj : 7|4@0+ (1,0) [0|15] "SED"  APIM,APIM_CISM,RACM_RCIM
 SG_ Rr_Set_Temp_Units : 41|2@0+ (1,0) [0|3] "SED"  APIM,APIM_CISM,RACM_RCIM
 SG_ Rr_RHS_Set_Temp_Dig3 : 43|2@0+ (1,0) [0|3] "SED"  APIM,APIM_CISM,RACM_RCIM
 SG_ Rr_RHS_Set_Temp_Dig2 : 51|4@0+ (1,0) [0|15] "SED"  APIM,APIM_CISM,RACM_RCIM
 SG_ Rr_RHS_Set_Temp_Dig1 : 55|4@0+ (1,0) [0|15] "SED"  APIM,APIM_CISM,RACM_RCIM
 SG_ Rr_RH_Htd_Seat_Btn_Stt : 45|2@0+ (1,0) [0|3] "SED"  APIM,APIM_CISM,RACM_RCIM
 SG_ Rr_RH_Cld_Seat_Btn_Stt : 47|2@0+ (1,0) [0|3] "SED"  APIM,APIM_CISM,RACM_RCIM
 SG_ Rr_Panel_Btn_Stt : 35|2@0+ (1,0) [0|3] "SED"  APIM,APIM_CISM,RACM_RCIM
 SG_ Rr_On_Indicator : 2|1@0+ (1,0) [0|1] "SED"  APIM,APIM_CISM,RACM_RCIM
 SG_ Rr_LHS_Set_Temp_Dig3 : 37|2@0+ (1,0) [0|3] "SED"  APIM,APIM_CISM,RACM_RCIM
 SG_ Rr_LHS_Set_Temp_Dig2 : 25|4@0+ (1,0) [0|15] "SED"  APIM,APIM_CISM,RACM_RCIM
 SG_ Rr_LHS_Set_Temp_Dig1 : 29|4@0+ (1,0) [0|15] "SED"  APIM,APIM_CISM,RACM_RCIM
 SG_ Rr_LH_Htd_Seat_Btn_Stt : 31|2@0+ (1,0) [0|3] "SED"  APIM,APIM_CISM,RACM_RCIM
 SG_ Rr_LH_Cld_Seat_Btn_Stt : 23|2@0+ (1,0) [0|3] "SED"  APIM,APIM_CISM,RACM_RCIM
 SG_ Rr_Floor_Btn_Stt : 9|2@0+ (1,0) [0|3] "SED"  APIM,APIM_CISM,RACM_RCIM
 SG_ Rr_Control_Btn_Stt : 11|2@0+ (1,0) [0|3] "SED"  APIM,APIM_CISM,RACM_RCIM
 SG_ Rr_Blower_Indicate : 15|4@0+ (1,0) [0|15] "SED"  APIM,APIM_CISM,RACM_RCIM
 SG_ Rr_AUTO_Btn_Stt : 1|2@0+ (1,0) [0|3] "SED"  APIM,APIM_CISM,RACM_RCIM

BO_ 865 Clmt_Button_Stat2_HS3: 8 GWM
 SG_ Dsp_RotAddrBtnEv_St : 63|4@0+ (1,0) [0|15] "SED"  APIM,APIM_CISM
 SG_ SelDrvMdeButtn_B_Stat : 55|1@0+ (1,0) [0|1] "SED" Vector__XXX
 SG_ SteEffortButtn_B_Stat : 54|1@0+ (1,0) [0|1] "SED"  IPC
 SG_ SelDrvMdeSwtch_D_Stat2 : 51|2@0+ (1,0) [0|3] "SED" Vector__XXX
 SG_ EngExhMdeQuiet_B_RqDrv : 52|1@0+ (1,0) [0|1] "SED"  IPC
 SG_ LnchCtlSys_B_RqDrv : 53|1@0+ (1,0) [0|1] "SED"  IPC
 SG_ CC_Fr_Stat_User_Adj : 6|3@0+ (1,0) [0|7] "SED"  HUD_ADV,GENERIC
 SG_ RHS_Auto_Seat_Btn_Stt : 57|2@0+ (1,0) [0|3] "SED"  APIM,APIM_CISM,FCIMB
 SG_ Front_Blower_Indicate : 13|4@0+ (1,0) [0|15] "SED"  APIM,APIM_CISM,HUD_ADV,IPC
 SG_ CC_Diagnostics_Active : 7|1@0+ (1,0) [0|1] "SED"  IPC
 SG_ RHS_Temp_Display_Digit3 : 3|2@0+ (1,0) [0|3] "SED"  APIM,APIM_CISM,IPC
 SG_ RHS_Temp_Display_Digit2 : 47|8@0+ (1,0) [0|255] "ASCII"  APIM,APIM_CISM,IPC
 SG_ RHS_Temp_Display_Digit1 : 39|8@0+ (1,0) [0|255] "ASCII"  APIM,APIM_CISM,IPC
 SG_ LHS_Temp_Display_Digit3 : 9|2@0+ (1,0) [0|3] "SED"  APIM,APIM_CISM,IPC
 SG_ LHS_Temp_Display_Digit2 : 31|8@0+ (1,0) [0|255] "ASCII"  APIM,APIM_CISM,IPC
 SG_ LHS_Temp_Display_Digit1 : 23|8@0+ (1,0) [0|255] "ASCII"  APIM,APIM_CISM,IPC
 SG_ EATC_RHS_Units : 15|2@0+ (1,0) [0|3] "SED"  APIM,APIM_CISM,IPC
 SG_ EATC_LHS_Units : 1|2@0+ (1,0) [0|3] "SED"  APIM,APIM_CISM,IPC
 SG_ LHS_Auto_Seat_Btn_Stt : 59|2@0+ (1,0) [0|3] "SED"  APIM,APIM_CISM,FCIMB

BO_ 1046 BrakeSysFeatures_2_HS3: 8 GWM
 SG_ PrkBrkDynmc_D_Allw : 39|2@0+ (1,0) [0|3] "SED"  IPC
 SG_ BrkPrkBrkDynmc_B_Actl : 24|1@0+ (1,0) [0|1] "SED"  IPC
 SG_ TRLR_SWAY_EVNT_IN_PROG : 25|1@0+ (1,0) [0|1] "SED"  APIM,APIM_CISM,IPC
 SG_ TRLR_SWAY_CONFIG_STAT : 26|1@0+ (1,0) [0|1] "SED"  APIM,APIM_CISM,IPC
 SG_ ReserveTracCtlPtActv : 28|1@0+ (1,0) [0|1] "SED" Vector__XXX
 SG_ HsaMde_D_Mem : 33|2@0+ (1,0) [0|3] "SED"  APIM,APIM_CISM,IPC
 SG_ BrkBstrVac_B_Rq : 27|1@0+ (1,0) [0|1] "Discrete" Vector__XXX
 SG_ BpedDiffLckTq_No_Cs : 23|8@0+ (1,0) [0|255] "unitless"  GENERIC
 SG_ DrvSlipCtlMde_D_Ind : 44|2@0+ (1,0) [0|3] "SED"  IPC
 SG_ DrvSlipCtlLamp_D_Rq : 42|2@0+ (1,0) [0|3] "SED"  APIM_CISM,IPC
 SG_ TCMode : 15|1@0+ (1,0) [0|1] "SED"  APIM,APIM_CISM,IPC
 SG_ HILL_DESC_MC : 47|3@0+ (1,0) [0|7] "SED"  APIM,APIM_CISM,IPC
 SG_ DrvAntiLckLamp_D_Rq : 55|2@0+ (1,0) [0|3] "SED"  APIM_CISM,IPC
 SG_ ChimeBrk_B_Rq : 14|1@0+ (1,0) [0|1] "SED"  IPC
 SG_ BrkLamp_B_Rq : 13|1@0+ (1,0) [0|1] "SED"  IPC
 SG_ Abs_B_Falt : 5|1@0+ (1,0) [0|1] "SED"  TRM_ITRM,IPC
 SG_ StabCtlBrk_B_Avail : 4|1@0+ (1,0) [0|1] "SED"  IPC
 SG_ DrvHdcWarnInfo_D_Rq : 35|2@0+ (1,0) [0|3] "SED"  IPC
 SG_ DrvHdcMsg_D_Rq : 10|3@0+ (1,0) [0|7] "SED"  IPC
 SG_ DrvHdcLampInfo_D_Rq : 12|2@0+ (1,0) [0|3] "SED"  APIM,APIM_CISM,IPC
 SG_ RearDiffElckrOpen_B_Rq : 40|1@0+ (1,0) [0|1] "SED"  GENERIC
 SG_ BpedMove_No_Cnt : 3|4@0+ (1,0) [0|15] "unitless"  GENERIC
 SG_ BpedMove_D_Actl : 7|2@0+ (1,0) [0|3] "SED" Vector__XXX
 SG_ RearDiffLck_Tq2_RqMx : 51|12@0+ (4,0) [0|16376] "Nm"  GENERIC
 SG_ HdcMde_D_Actl : 31|3@0+ (1,0) [0|7] "SED" Vector__XXX

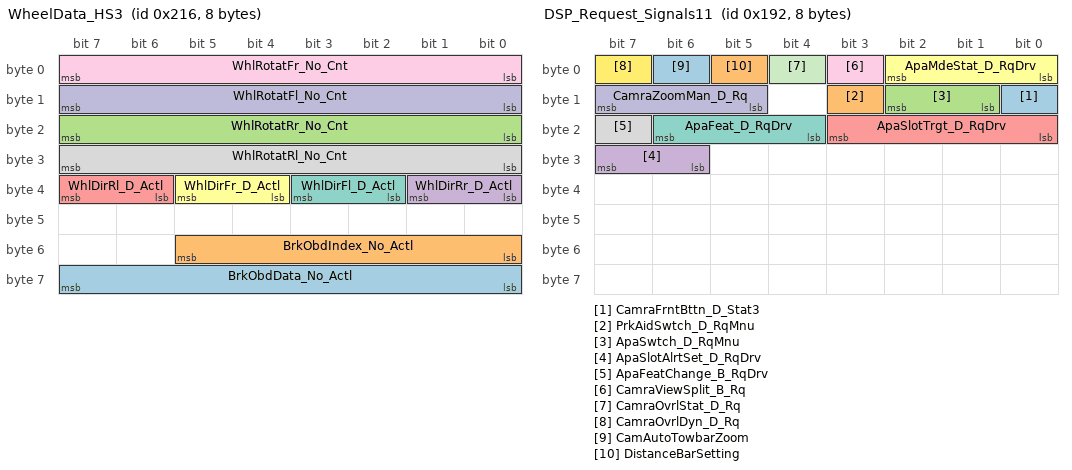
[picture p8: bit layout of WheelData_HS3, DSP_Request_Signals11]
BO_ 534 WheelData_HS3: 8 GWM
 SG_ BrkObdData_No_Actl : 63|8@0+ (1,0) [0|255] "unitless"  GENERIC
 SG_ BrkObdIndex_No_Actl : 53|6@0+ (1,0) [0|63] "unitless"  GENERIC
 SG_ WhlRotatRr_No_Cnt : 23|8@0+ (1,0) [0|255] "unitless"  APIM,APIM_CISM
 SG_ WhlDirRr_D_Actl : 33|2@0+ (1,0) [0|3] "SED"  APIM,APIM_CISM
 SG_ WhlDirRl_D_Actl : 39|2@0+ (1,0) [0|3] "SED"  APIM,APIM_CISM
 SG_ WhlDirFr_D_Actl : 37|2@0+ (1,0) [0|3] "SED"  APIM,APIM_CISM
 SG_ WhlDirFl_D_Actl : 35|2@0+ (1,0) [0|3] "SED"  APIM,APIM_CISM
 SG_ WhlRotatRl_No_Cnt : 31|8@0+ (1,0) [0|255] "unitless"  APIM,APIM_CISM
 SG_ WhlRotatFr_No_Cnt : 7|8@0+ (1,0) [0|255] "unitless"  APIM,APIM_CISM
 SG_ WhlRotatFl_No_Cnt : 15|8@0+ (1,0) [0|255] "unitless"  APIM,APIM_CISM

BO_ 402 DSP_Request_Signals11: 8 APIM
 SG_ CamraFrntBttn_D_Stat3 : 8|1@0+ (1,0) [0|1] "SED"  GWM
 SG_ PrkAidSwtch_D_RqMnu : 11|1@0+ (1,0) [0|1] "SED"  GWM
 SG_ ApaSwtch_D_RqMnu : 10|2@0+ (1,0) [0|3] "SED"  GWM
 SG_ ApaSlotAlrtSet_D_RqDrv : 31|2@0+ (1,0) [0|3] "SED"  GWM
 SG_ ApaSlotTrgt_D_RqDrv : 19|4@0+ (1,0) [0|15] "SED"  GWM
 SG_ ApaMdeStat_D_RqDrv : 2|3@0+ (1,0) [0|7] "SED"  GWM
 SG_ ApaFeat_D_RqDrv : 22|3@0+ (1,0) [0|7] "SED"  GWM
 SG_ ApaFeatChange_B_RqDrv : 23|1@0+ (1,0) [0|1] "SED"  GWM
 SG_ CamraViewSplit_B_Rq : 3|1@0+ (1,0) [0|1] "SED"  GWM
 SG_ CamraZoomMan_D_Rq : 15|3@0+ (1,0) [0|7] "SED"  GWM
 SG_ CamraOvrlStat_D_Rq : 4|1@0+ (1,0) [0|1] "SED"  IPC,GWM
 SG_ CamraOvrlDyn_D_Rq : 7|1@0+ (1,0) [0|1] "SED"  IPC,GWM
 SG_ CamAutoTowbarZoom : 6|1@0+ (1,0) [0|1] "SED"  IPC,GWM
 SG_ DistanceBarSetting : 5|1@0+ (1,0) [0|1] "SED"  GWM

BO_ 946 BodyInfo_3_HS3: 8 GWM
 SG_ ValetMode_D_Mem : 16|1@0+ (1,0) [0|1] "SED"  GENERIC
 SG_ DimmingLvlEvnt_No_Actl : 18|2@0+ (1,0) [0|3] "unitless"  IPC
 SG_ DrStatDrvErrCnt_B_Stat : 19|1@0+ (1,0) [0|1] "SED" Vector__XXX
 SG_ Backlit_LED_Status : 23|4@0+ (1,0) [0|15] "SED"  APIM,APIM_CISM,TRM_ITRM
 SG_ TurnLghtRightOn_B_Stat : 35|1@0+ (1,0) [0|1] "SED"  APIM_CISM,HUD_ADV,ACM,IPC
 SG_ TurnLghtLeftOn_B_Stat : 54|1@0+ (1,0) [0|1] "SED"  APIM_CISM,HUD_ADV,DSP,ACM,IPC
 SG_ FogLghtRearOn_B_Stat : 1|1@0+ (1,0) [0|1] "SED"  APIM_CISM,TRM_ITRM,IPC
 SG_ TurnLghtRight_D_Rq : 63|2@0+ (1,0) [0|3] "SED"  APIM_CISM,TRM_ITRM,DSP
 SG_ IgnKeyType_D_Actl : 39|4@0+ (1,0) [0|15] "SED"  APIM,APIM_CISM,DSP,ACM,IPC
 SG_ Parklamp_Status : 3|2@0+ (1,0) [0|3] "SED"  APIM,APIM_CISM,TRM_ITRM,RACM_RCIM,ACM,IPC
 SG_ Litval : 47|8@0+ (1,0) [0|253] "SED"  APIM,APIM_CISM,ACM,IPC
 SG_ Key_In_Ignition_Stat : 11|1@0+ (1,0) [0|1] "SED"  APIM,APIM_CISM,DSP,ACM,IPC
 SG_ Ignition_Status : 7|4@0+ (1,0) [0|15] "SED"  APIM,APIM_CISM,ESPM,HUD_ADV,DSP,TRM_ITRM,RACM_RCIM,ACM,WCM,IPC
 SG_ Dimming_Lvl : 31|8@0+ (1,0) [0|253] "SED"  APIM,APIM_CISM,HUD_ADV,TRM_ITRM,RACM_RCIM,ACM,IPC
 SG_ Day_Night_Status : 15|2@0+ (1,0) [0|3] "SED"  APIM,APIM_CISM,HUD_ADV,TRM_ITRM,RACM_RCIM,ACM,IPC
 SG_ Remote_Start_Status : 13|2@0+ (1,0) [0|3] "SED"  APIM,APIM_CISM,IPC
 SG_ DrStatTgate_B_Actl : 0|1@0+ (1,0) [0|1] "SED"  APIM,APIM_CISM,TRM_ITRM,ACM,IPC
 SG_ DrStatRr_B_Actl : 49|1@0+ (1,0) [0|1] "SED"  APIM,APIM_CISM,TRM_ITRM,HUD_ADV,ACM,IPC
 SG_ DrStatRl_B_Actl : 48|1@0+ (1,0) [0|1] "SED"  APIM,APIM_CISM,TRM_ITRM,HUD_ADV,ACM,IPC
 SG_ DrStatPsngr_B_Actl : 60|1@0+ (1,0) [0|1] "SED"  APIM,APIM_CISM,TRM_ITRM,HUD_ADV,ACM,IPC
 SG_ FogLghtFrontOn_B_Stat : 56|1@0+ (1,0) [0|1] "SED"  APIM,APIM_CISM,IPC
 SG_ DrStatInnrTgate_B_Actl : 58|1@0+ (1,0) [0|1] "SED"  APIM,APIM_CISM,TRM_ITRM,HUD_ADV,IPC,ACM
 SG_ DrStatHood_B_Actl : 59|1@0+ (1,0) [0|1] "SED"  APIM,APIM_CISM,IPC,ACM
 SG_ DrStatDrv_B_Actl : 61|1@0+ (1,0) [0|1] "SED"  APIM,APIM_CISM,TRM_ITRM,HUD_ADV,ACM,IPC
 SG_ PrkBrkActv_B_Actl : 55|1@0+ (1,0) [0|1] "SED"  APIM,APIM_CISM,IPC
 SG_ LifeCycMde_D_Actl : 53|4@0+ (1,0) [0|15] "SED"  APIM,APIM_CISM,WCM,TRM_ITRM,HUD_ADV,DSP,ACM,IPC
 SG_ Delay_Accy : 57|1@0+ (1,0) [0|1] "SED"  APIM,APIM_CISM,HUD_ADV,DSP,ACM,WCM,IPC
 SG_ TurnLghtLeft_D_Rq : 9|2@0+ (1,0) [0|3] "SED"  APIM_CISM,TRM_ITRM
 SG_ CrashEvnt_D_Stat : 34|2@0+ (1,0) [0|3] "SED" Vector__XXX
 SG_ FuelPmpInhbt_B_Stat : 32|1@0+ (1,0) [0|1] "SED" Vector__XXX
 SG_ BodySrvcRqd_B_Rq : 10|1@0+ (1,0) [0|1] "SED"  IPC

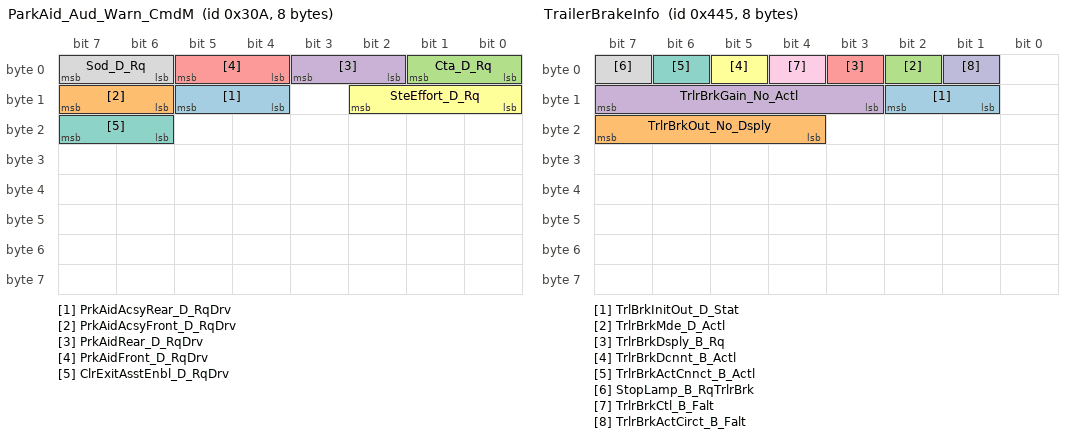
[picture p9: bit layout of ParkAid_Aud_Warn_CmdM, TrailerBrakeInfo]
BO_ 778 ParkAid_Aud_Warn_CmdM: 8 IPC
 SG_ PrkAidAcsyRear_D_RqDrv : 13|2@0+ (1,0) [0|3] "SED"  GWM
 SG_ PrkAidAcsyFront_D_RqDrv : 15|2@0+ (1,0) [0|3] "SED"  GWM
 SG_ Cta_D_Rq : 1|2@0+ (1,0) [0|3] "SED"  GWM
 SG_ PrkAidRear_D_RqDrv : 3|2@0+ (1,0) [0|3] "SED"  GWM
 SG_ PrkAidFront_D_RqDrv : 5|2@0+ (1,0) [0|3] "SED"  GWM
 SG_ SteEffort_D_Rq : 10|3@0+ (1,0) [0|7] "SED"  GWM
 SG_ ClrExitAsstEnbl_D_RqDrv : 23|2@0+ (1,0) [0|3] "SED"  GWM
 SG_ Sod_D_Rq : 7|2@0+ (1,0) [0|3] "SED"  GWM

BO_ 1093 TrailerBrakeInfo: 8 TRM_ITRM
 SG_ TrlBrkInitOut_D_Stat : 10|2@0+ (1,0) [0|3] "SED"  IPC,GWM
 SG_ TrlrBrkOut_No_Dsply : 23|4@0+ (1,0) [0|15] "unitless"  IPC,GWM
 SG_ TrlrBrkMde_D_Actl : 2|1@0+ (1,0) [0|1] "SED"  IPC,GWM
 SG_ TrlrBrkGain_No_Actl : 15|5@0+ (0.5,0) [0|15.5] "unitless"  APIM,APIM_CISM,IPC,GWM
 SG_ TrlrBrkDsply_B_Rq : 3|1@0+ (1,0) [0|1] "SED"  IPC,GWM
 SG_ TrlrBrkDcnnt_B_Actl : 5|1@0+ (1,0) [0|1] "SED"  IPC,GWM
 SG_ TrlrBrkActCnnct_B_Actl : 6|1@0+ (1,0) [0|1] "SED"  APIM,APIM_CISM,IPC,GWM
 SG_ StopLamp_B_RqTrlrBrk : 7|1@0+ (1,0) [0|1] "SED"  GWM
 SG_ TrlrBrkCtl_B_Falt : 4|1@0+ (1,0) [0|1] "SED"  IPC,GWM
 SG_ TrlrBrkActCirct_B_Falt : 1|1@0+ (1,0) [0|1] "SED"  IPC,GWM

BO_ 1879 TesterPhysicalReqTBM: 8 TSTR
 SG_ TesterPhysicalReqTBM : 7|64@0+ (1,0) [0|1.84467E+019] "unitless"  TRM_ITRM

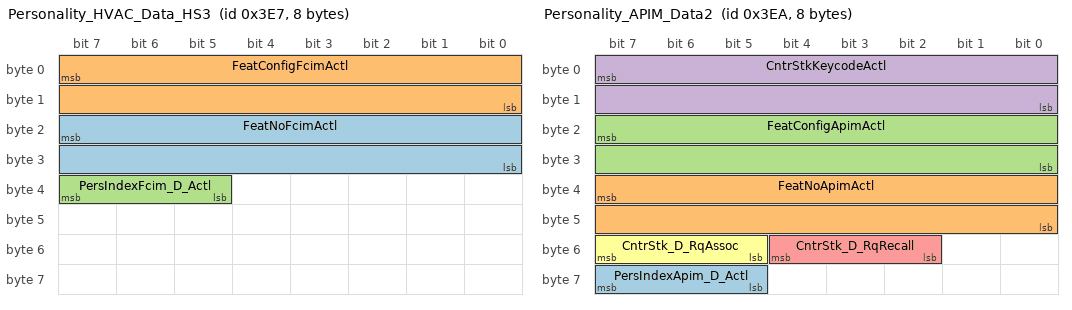
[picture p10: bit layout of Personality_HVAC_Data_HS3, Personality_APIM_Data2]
BO_ 999 Personality_HVAC_Data_HS3: 8 GWM
 SG_ FeatNoFcimActl : 23|16@0+ (1,0) [0|65535] "Number"  APIM,APIM_CISM,IPC
 SG_ FeatConfigFcimActl : 7|16@0+ (1,0) [0|65535] "Undefined"  APIM,APIM_CISM,IPC
 SG_ PersIndexFcim_D_Actl : 39|3@0+ (1,0) [0|7] "SED"  APIM,APIM_CISM,IPC

BO_ 1002 Personality_APIM_Data2: 8 APIM
 SG_ PersIndexApim_D_Actl : 63|3@0+ (1,0) [0|7] "SED"  IPC,GWM
 SG_ FeatNoApimActl : 39|16@0+ (1,0) [0|65535] "Number"  GWM,IPC
 SG_ FeatConfigApimActl : 23|16@0+ (1,0) [0|65535] "Number"  GWM,IPC
 SG_ CntrStkKeycodeActl : 7|16@0+ (1,0) [0|65535] "Undefined"  GWM
 SG_ CntrStk_D_RqRecall : 52|3@0+ (1,0) [0|7] "SED"  GWM
 SG_ CntrStk_D_RqAssoc : 55|3@0+ (1,0) [0|7] "SED"  GWM

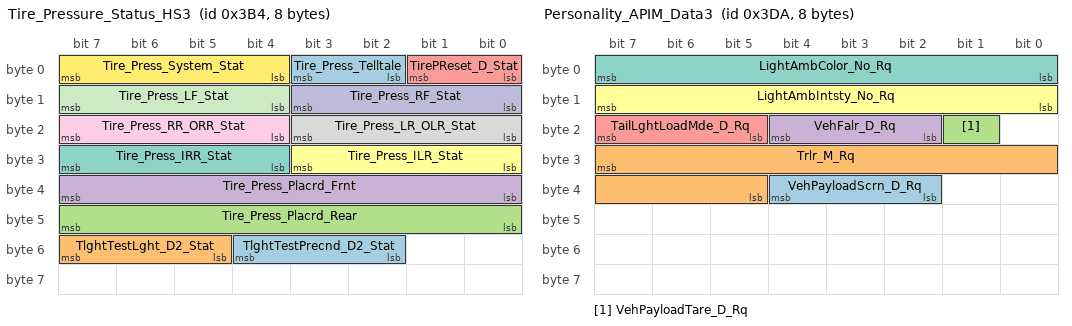
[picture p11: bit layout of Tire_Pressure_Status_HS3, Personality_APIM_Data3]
BO_ 948 Tire_Pressure_Status_HS3: 8 GWM
 SG_ TlghtTestPrecnd_D2_Stat : 52|3@0+ (1,0) [0|7] "SED"  APIM,APIM_CISM
 SG_ TlghtTestLght_D2_Stat : 55|3@0+ (1,0) [0|7] "SED"  APIM,APIM_CISM
 SG_ Tire_Press_Placrd_Rear : 47|8@0+ (1,0) [0|255] "pounds/inch^2"  APIM,APIM_CISM,IPC
 SG_ Tire_Press_Placrd_Frnt : 39|8@0+ (1,0) [0|255] "pounds/inch^2"  APIM,APIM_CISM,IPC
 SG_ TirePReset_D_Stat : 1|2@0+ (1,0) [0|3] "Discrete"  APIM,APIM_CISM,IPC
 SG_ Tire_Press_ILR_Stat : 27|4@0+ (1,0) [0|15] "SED"  APIM,APIM_CISM,IPC
 SG_ Tire_Press_IRR_Stat : 31|4@0+ (1,0) [0|15] "SED"  APIM,APIM_CISM,IPC
 SG_ Tire_Press_LR_OLR_Stat : 19|4@0+ (1,0) [0|15] "SED"  APIM,APIM_CISM,IPC
 SG_ Tire_Press_RR_ORR_Stat : 23|4@0+ (1,0) [0|15] "SED"  APIM,APIM_CISM,IPC
 SG_ Tire_Press_RF_Stat : 11|4@0+ (1,0) [0|15] "SED"  APIM,APIM_CISM,IPC
 SG_ Tire_Press_LF_Stat : 15|4@0+ (1,0) [0|15] "SED"  APIM,APIM_CISM,IPC
 SG_ Tire_Press_System_Stat : 7|4@0+ (1,0) [0|15] "SED"  APIM,APIM_CISM,IPC
 SG_ Tire_Press_Telltale : 3|2@0+ (1,0) [0|3] "SED"  APIM,APIM_CISM,IPC

BO_ 986 Personality_APIM_Data3: 8 APIM
 SG_ VehPayloadScrn_D_Rq : 36|3@0+ (1,0) [0|7] "SED"  GWM
 SG_ Trlr_M_Rq : 31|11@0+ (10,0) [0|20450] "kilogram"  GWM
 SG_ VehPayloadTare_D_Rq : 17|1@0+ (1,0) [0|1] "SED"  GWM
 SG_ VehFalr_D_Rq : 20|3@0+ (1,0) [0|7] "SED"  GWM
 SG_ TailLghtLoadMde_D_Rq : 23|3@0+ (1,0) [0|7] "SED"  GWM
 SG_ LightAmbIntsty_No_Rq : 15|8@0+ (1,0) [0|255] "unitless"  GWM
 SG_ LightAmbColor_No_Rq : 7|8@0+ (1,0) [0|255] "Discrete"  GWM

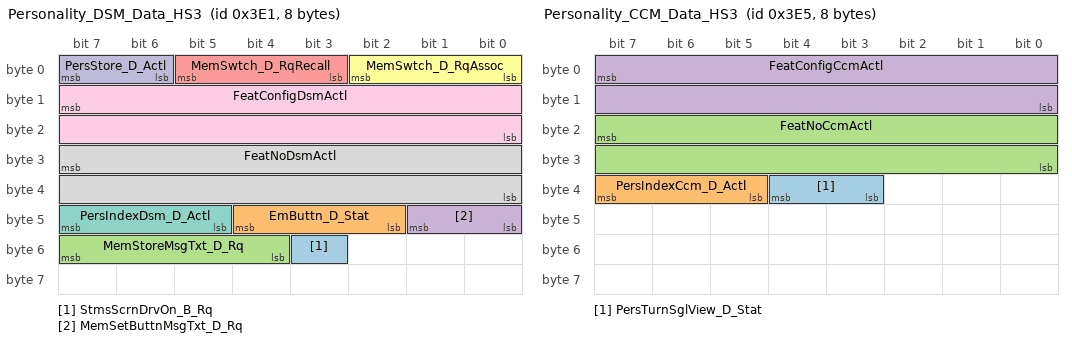
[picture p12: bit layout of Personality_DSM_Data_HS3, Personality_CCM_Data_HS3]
BO_ 993 Personality_DSM_Data_HS3: 8 GWM
 SG_ StmsScrnDrvOn_B_Rq : 51|1@0+ (1,0) [0|1] "SED"  APIM,APIM_CISM
 SG_ EmButtn_D_Stat : 44|3@0+ (1,0) [0|7] "SED"  APIM,APIM_CISM
 SG_ MemStoreMsgTxt_D_Rq : 55|4@0+ (1,0) [0|15] "SED"  IPC
 SG_ MemSetButtnMsgTxt_D_Rq : 41|2@0+ (1,0) [0|3] "SED"  IPC
 SG_ MemSwtch_D_RqRecall : 5|3@0+ (1,0) [0|7] "SED" Vector__XXX
 SG_ MemSwtch_D_RqAssoc : 2|3@0+ (1,0) [0|7] "SED" Vector__XXX
 SG_ PersIndexDsm_D_Actl : 47|3@0+ (1,0) [0|7] "SED"  APIM,APIM_CISM,IPC
 SG_ FeatNoDsmActl : 31|16@0+ (1,0) [0|65535] "Number"  APIM,APIM_CISM,IPC
 SG_ FeatConfigDsmActl : 15|16@0+ (1,0) [0|65535] "Undefined"  APIM,APIM_CISM,IPC
 SG_ PersStore_D_Actl : 7|2@0+ (1,0) [0|3] "SED"  APIM,APIM_CISM

BO_ 710 BEZEL_RDISP_WORD_Tx_HS3: 8 GWM
 SG_ BEZEL_RDISP_WORD_Tx : 7|64@0+ (1,0) [0|1.84467440737096E+019] "unitless"  APIM,APIM_CISM

BO_ 1814 TesterPhysicalReqGWM_H3: 8 TSTR
 SG_ TesterPhysicalReqGWM_H3 : 7|64@0+ (1,0) [0|1.84467E+019] "unitless"  GWM

BO_ 997 Personality_CCM_Data_HS3: 8 GWM
 SG_ PersTurnSglView_D_Stat : 36|2@0+ (1,0) [0|3] "SED"  APIM,APIM_CISM
 SG_ PersIndexCcm_D_Actl : 39|3@0+ (1,0) [0|7] "SED"  APIM,APIM_CISM,HUD_ADV,IPC
 SG_ FeatNoCcmActl : 23|16@0+ (1,0) [0|65535] "Number"  APIM,APIM_CISM,HUD_ADV,IPC
 SG_ FeatConfigCcmActl : 7|16@0+ (1,0) [0|65535] "Undefined"  APIM,APIM_CISM,HUD_ADV,IPC

BO_ 487 ACU_Request_Signals: 8 ACM
 SG_ Aioc_SetExtSrcOutpMd_Rq : 31|4@0+ (1,0) [0|15] "SED"  GENERIC

BO_ 464 ACU_Request_Signals_2: 8 ACM
 SG_ SdarsSampleRate_D_Rq : 31|2@0+ (1,0) [0|3] "SED"  APIM
 SG_ SDARS_DirectChannel_Rq : 9|10@0+ (1,0) [0|1023] "unitless"  APIM

BO_ 864 Clmt_Button_Stat1_HS3: 8 GWM
 SG_ MdeMnu_Buttn_Stat : 58|1@0+ (1,0) [0|1] "SED"  APIM,APIM_CISM
 SG_ Front_AUTO_Blwr_Lvl : 60|2@0+ (1,0) [0|3] "SED"  APIM,APIM_CISM
 SG_ RearMnu_Buttn_Stat : 48|1@0+ (1,0) [0|1] "SED"  APIM,APIM_CISM
 SG_ FrontMnu_Buttn_Stat : 49|1@0+ (1,0) [0|1] "SED"  APIM,APIM_CISM
 SG_ DrvrFcsdMde_Btn_Stt : 57|2@0+ (1,0) [0|3] "SED"  APIM,APIM_CISM
 SG_ RHS_Cond_Seat_Status : 63|3@0+ (1,0) [0|7] "SED"  APIM,APIM_CISM,IPC
 SG_ LHS_Cond_Seat_Status : 10|3@0+ (1,0) [0|7] "SED"  APIM,APIM_CISM,HUD_ADV,IPC
 SG_ Htd_Strg_Whl_Status : 27|2@0+ (1,0) [0|3] "SED"  APIM,APIM_CISM,HUD_ADV,IPC
 SG_ Htd_Strg_Whl_Btn_Stt : 29|2@0+ (1,0) [0|3] "SED"  APIM,APIM_CISM,IPC
 SG_ Defrost_Btn_Stt : 3|2@0+ (1,0) [0|3] "SED"  APIM,APIM_CISM,IPC
 SG_ CC_Fr_Btn_User_Adj : 15|5@0+ (1,0) [0|31] "SED"  APIM,APIM_CISM,HUD_ADV
 SG_ RHS_Htd_Seat_Btn_Stt : 53|2@0+ (1,0) [0|3] "SED"  IPC
 SG_ RHS_Cld_Seat_Btn_Stt : 55|2@0+ (1,0) [0|3] "SED"  APIM,APIM_CISM,IPC
 SG_ Outside_Btn_Stt : 47|2@0+ (1,0) [0|3] "SED"  IPC
 SG_ LHS_Htd_Seat_Btn_Stt : 39|2@0+ (1,0) [0|3] "SED"  APIM,APIM_CISM,IPC
 SG_ LHS_Cld_Seat_Btn_Stt : 25|2@0+ (1,0) [0|3] "SED"  APIM,APIM_CISM,IPC
 SG_ Htd_Frt_Wsh_Btn_Stt : 31|2@0+ (1,0) [0|3] "SED"  APIM,APIM_CISM,HUD_ADV,IPC
 SG_ Auto_Recirc_Btn_Stt : 5|2@0+ (1,0) [0|3] "SED"  IPC
 SG_ Recirc_Btn_Stt : 41|2@0+ (1,0) [0|3] "SED"  APIM,APIM_CISM,HUD_ADV,IPC
 SG_ Rear_Defrost_Btn_Stt : 43|2@0+ (1,0) [0|3] "SED"  APIM,APIM_CISM,HUD_ADV,IPC
 SG_ My_Temp_Btn_Stt : 33|2@0+ (1,0) [0|3] "SED"  APIM,APIM_CISM,HUD_ADV,IPC
 SG_ Max_Defrost_Btn_Stt : 35|2@0+ (1,0) [0|3] "SED"  APIM,APIM_CISM,HUD_ADV,IPC
 SG_ Max_AC_Btn_Stt : 37|2@0+ (1,0) [0|3] "SED"  APIM,APIM_CISM,HUD_ADV,IPC
 SG_ Front_AUTO_Label : 19|2@0+ (1,0) [0|3] "SED"  APIM,APIM_CISM,HUD_ADV,IPC
 SG_ Windscreen_Btn_Stt : 51|2@0+ (1,0) [0|3] "SED"  APIM,APIM_CISM,IPC
 SG_ Panel_Btn_Stt : 45|2@0+ (1,0) [0|3] "SED"  APIM,APIM_CISM,HUD_ADV,IPC
 SG_ Front_Power_Btn_Stt : 17|2@0+ (1,0) [0|3] "SED"  APIM,APIM_CISM,HUD_ADV,IPC
 SG_ Front_AUTO_Btn_Stt : 21|2@0+ (1,0) [0|3] "SED"  APIM,APIM_CISM,HUD_ADV,IPC
 SG_ Floor_Btn_Stt : 23|2@0+ (1,0) [0|3] "SED"  APIM,APIM_CISM,HUD_ADV,IPC
 SG_ Dual_Button_Stt : 1|2@0+ (1,0) [0|3] "SED"  APIM,APIM_CISM,HUD_ADV,IPC
 SG_ AC_Btn_Stt : 7|2@0+ (1,0) [0|3] "SED"  APIM,APIM_CISM,HUD_ADV,IPC

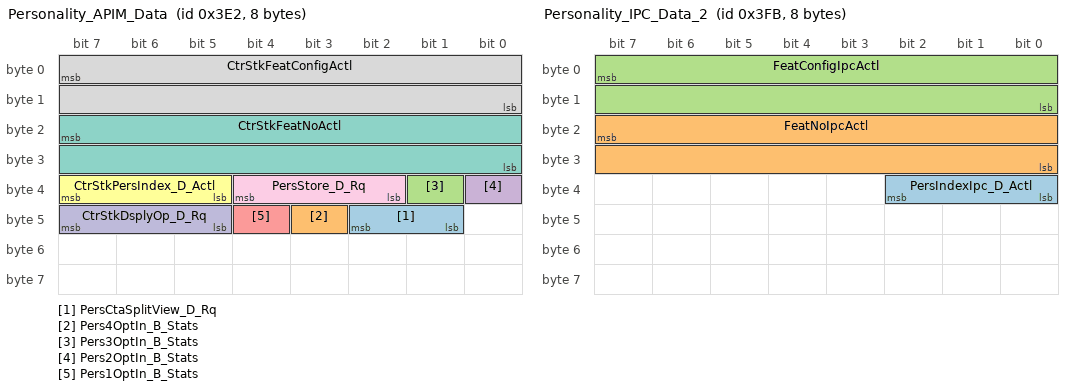
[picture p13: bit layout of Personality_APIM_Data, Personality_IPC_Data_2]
BO_ 994 Personality_APIM_Data: 8 APIM
 SG_ PersCtaSplitView_D_Rq : 42|2@0+ (1,0) [0|3] "SED"  GWM
 SG_ Pers4OptIn_B_Stats : 43|1@0+ (1,0) [0|1] "SED"  GWM
 SG_ Pers3OptIn_B_Stats : 33|1@0+ (1,0) [0|1] "SED"  GWM
 SG_ Pers2OptIn_B_Stats : 32|1@0+ (1,0) [0|1] "SED"  GWM
 SG_ Pers1OptIn_B_Stats : 44|1@0+ (1,0) [0|1] "SED"  GWM
 SG_ CtrStkPersIndex_D_Actl : 39|3@0+ (1,0) [0|7] "SED"  DSP,IPC,ACM,GWM
 SG_ CtrStkFeatNoActl : 23|16@0+ (1,0) [0|65535] "Undefined"  IPC,GWM
 SG_ CtrStkFeatConfigActl : 7|16@0+ (1,0) [0|65535] "Undefined"  IPC,GWM
 SG_ PersStore_D_Rq : 36|3@0+ (1,0) [0|7] "SED"  GWM
 SG_ CtrStkDsplyOp_D_Rq : 47|3@0+ (1,0) [0|7] "SED"  DSP,IPC,ACM,GWM

BO_ 1822 TesterPhysicalResGWM_HS3: 8 GWM
 SG_ TesterPhysicalResGWM_H3 : 7|64@0+ (1,0) [0|1.84467E+019] "unitless"  TSTR

BO_ 394 ACCDATA_3_HS3: 8 GWM
 SG_ AccStopStat_D_Dsply : 41|2@0+ (1,0) [0|3] "SED"  HUD_ADV,IPC
 SG_ AccTrgDist2_D_Dsply : 27|4@0+ (1,0) [0|15] "SED"  HUD_ADV,IPC
 SG_ AccStopRes_B_Dsply : 54|1@0+ (1,0) [0|1] "SED"  HUD_ADV,IPC
 SG_ TjaWarn_D_Rq : 50|3@0+ (1,0) [0|7] "SED"  HUD_ADV,IPC
 SG_ Tja_D_Stat : 44|3@0+ (1,0) [0|7] "SED"  HUD_ADV,IPC
 SG_ IaccLamp_D_Rq : 46|2@0+ (1,0) [0|3] "SED"  APIM,APIM_CISM,HUD_ADV,IPC
 SG_ AccMsgTxt_D2_Rq : 31|4@0+ (1,0) [0|15] "SED"  HUD_ADV,IPC
 SG_ TjaMsgTxt_D_Dsply : 53|3@0+ (1,0) [0|7] "SED"  HUD_ADV,IPC
 SG_ HaDsply_No_Cnt : 4|4@0+ (1,0) [0|15] "unitless"  IPC
 SG_ FcwDeny_B_Dsply : 10|1@0+ (1,0) [0|1] "SED"  IPC
 SG_ FcwMemStat_B_Actl : 13|1@0+ (1,0) [0|1] "SED"  IPC
 SG_ AccTGap_B_Dsply : 35|1@0+ (1,0) [0|1] "SED"  HUD_ADV,IPC
 SG_ CadsAlignIncplt_B_Actl : 11|1@0+ (1,0) [0|1] "SED"  IPC
 SG_ AccFllwMde_B_Dsply : 17|1@0+ (1,0) [0|1] "SED"  HUD_ADV,IPC
 SG_ CadsRadrBlck_B_Actl : 22|1@0+ (1,0) [0|1] "SED"  IPC
 SG_ CmbbPostEvnt_B_Dsply : 15|1@0+ (1,0) [0|1] "SED"  IPC
 SG_ AccStopMde_B_Dsply : 0|1@0+ (1,0) [0|1] "SED"  HUD_ADV,IPC
 SG_ FcwMemSens_D_Actl : 20|2@0+ (1,0) [0|3] "SED"  IPC
 SG_ FcwMsgTxt_D_Rq : 7|3@0+ (1,0) [0|7] "SED"  IPC
 SG_ AccTGap_D_Dsply : 34|3@0+ (1,0) [0|7] "SED"  HUD_ADV,IPC
 SG_ AccMemEnbl_B_RqDrv : 36|1@0+ (1,0) [0|1] "SED"  IPC
 SG_ HaDsply_No_Cs : 63|8@0+ (1,0) [0|255] "unitless"  IPC
 SG_ AccWarn_D_Dsply : 39|2@0+ (1,0) [0|3] "SED"  HUD_ADV,IPC
 SG_ FcwVisblWarn_B_Rq : 47|1@0+ (1,0) [0|1] "SED"  HUD_ADV,IPC
 SG_ FcwAudioWarn_B_Rq : 8|1@0+ (1,0) [0|1] "SED"  IPC

BO_ 1068 EnginePwrData_HS3: 8 GWM
 SG_ TrlrAidMsgTxt_D_Rq : 30|5@0+ (1,0) [0|31] "SED"  IPC

BO_ 1019 Personality_IPC_Data_2: 8 IPC
 SG_ PersIndexIpc_D_Actl : 34|3@0+ (1,0) [0|7] "SED"  APIM,APIM_CISM,GWM
 SG_ FeatNoIpcActl : 23|16@0+ (1,0) [0|65535] "Number"  APIM,APIM_CISM,GWM
 SG_ FeatConfigIpcActl : 7|16@0+ (1,0) [0|65535] "unitless"  APIM,APIM_CISM,GWM

BO_ 909 Body_Info_6_HS3: 8 GWM
 SG_ IgnPsswrdDsply_B_Rq : 57|1@0+ (1,0) [0|1] "SED"  APIM,APIM_CISM,IPC
 SG_ ElPwPoint_D_Rq : 59|2@0+ (1,0) [0|3] "SED"  GENERIC
 SG_ PoliceIdlMde_D_Stat : 55|4@0+ (1,0) [0|15] "SED"  IPC
 SG_ DrLatchMsgTxt_D_Rq : 43|3@0+ (1,0) [0|7] "SED"  IPC
 SG_ WiprFront_D_Stat2 : 63|4@0+ (1,0) [0|15] "SED"  APIM,APIM_CISM
 SG_ HazrdLght_B_Stat : 56|1@0+ (1,0) [0|1] "SED"  APIM,APIM_CISM
 SG_ TurnLghtSwtch_D_Stat2 : 49|2@0+ (1,0) [0|3] "SED"  IPC
 SG_ HeadLghtHiPrmsn_D_Stat : 51|2@0+ (1,0) [0|3] "SED"  GENERIC
 SG_ SecurityMsgTxt_D_Rq : 47|2@0+ (1,0) [0|3] "SED" Vector__XXX
 SG_ SteWhlLckMsgTxt_D_Rq : 25|2@0+ (1,0) [0|3] "SED"  IPC
 SG_ immoMsgTxt_D_Rq : 39|4@0+ (1,0) [0|15] "SED"  IPC
 SG_ PrsnlDevcChrgEnbl_B_Rq : 40|1@0+ (1,0) [0|1] "SED"  APIM,APIM_CISM,WCM
 SG_ PrmtrAlrmEvnt_D_Stat : 35|4@0+ (1,0) [0|15] "SED" Vector__XXX
 SG_ TracKeyMde_D_Stat : 45|2@0+ (1,0) [0|3] "SED"  IPC
 SG_ Keycode_Status : 15|20@0+ (1,0) [0|1048575] "unitless"  IPC
 SG_ PEBackupSlot_Stats : 27|2@0+ (1,0) [0|3] "SED"  IPC
 SG_ KeyMykeyTot_No_Cnt : 3|4@0+ (1,0) [0|15] "Counts"  ACM,IPC
 SG_ KeyAdmnTot_No_Cnt : 7|4@0+ (1,0) [0|15] "Counts"  IPC

BO_ 1824 TesterPhysicalReqIPC: 8 TSTR
 SG_ TesterPhysicalReqIPC : 7|64@0+ (1,0) [0|1.84467E+019] "unitless"  IPC

BO_TX_BU_ 551 : APIM_CISM,APIM;
BO_TX_BU_ 866 : APIM_CISM,APIM;
BO_TX_BU_ 402 : APIM_CISM,APIM;
BO_TX_BU_ 1002 : APIM_CISM,APIM;
BO_TX_BU_ 986 : APIM_CISM,APIM;
BO_TX_BU_ 487 : APIM_CISM,ACM;
BO_TX_BU_ 994 : APIM_CISM,APIM;
CM_ SG_ 516 ApedPos_Pc_ActlArb "ABSGenSigTimeoutTime=1000";
CM_ SG_ 516 ApedPosPcActl_No_Cs "Signal not transmitted on gas and diesel variants.";
CM_ SG_ 516 EngAout3_N_Actl "Signal not transmitted on gas and diesel variants.";
CM_ SG_ 516 ApedPosPcActl_No_Cnt "Signal not transmitted on gas and diesel variants.";
CM_ SG_ 514 GearRvrse_D_Actl "Do not implement GearRvrse_D_Actl  until eTracker 8804151 is approved, 11/24/09";
CM_ SG_ 514 EngAout_Tq_VacLimSpcN "Signal not transmitted on gas and diesel variances.";
CM_ SG_ 514 EngCylSync_No_Ctr "Signal not transmitted on gas and diesel variances.";
CM_ SG_ 377 EngFuelCutFull_B_Inhbt "Signal not transmitted on diesel variants.";
CM_ SG_ 377 FuelFlw_Vl_Dsply "Signal not transmitted on diesel variants.";
CM_ SG_ 377 FuelFillInlet_B_Dsply "Signal not transmitted on diesel variants.";
CM_ SG_ 377 OdoCount "Signal not transmitted on diesel variants.";
CM_ SG_ 377 EngOilLife_Pc_Actl "Signal not transmitted on diesel variants.";
CM_ SG_ 377 TrnKickDown_B_RqDrv "Signal not transmitted on diesel variants.";
CM_ SG_ 377 AirCondRec_B_Rq "Signal not transmitted on diesel variants.";
CM_ SG_ 377 AirCondClutch_B_Stats "Signal not transmitted on diesel variants.";
CM_ SG_ 376 EngAout_Aa_Actl "Signal not transmitted on HEV variants.";
CM_ SG_ 373 EngAout_Tq_MxActlN "Signal not transmitted on diesel variances.";
CM_ SG_ 373 EngFuelCutFull_B_Allw "Signal not transmitted on diesel variances.";
CM_ SG_ 342 EngOvrhtMitgActv_D_Ind "Signal not transmitted on diesel.";
CM_ SG_ 342 EngGoutLss_Tq_Est "Signal not transmitted on gas and diesel variants.";
CM_ SG_ 707 SSPClnt_SSPSrv_WORD_Tx "Tx by HS3 APIM";
CM_ BO_ 673 "Do not use this Frame for other Cluster Interaction";
CM_ SG_ 673 ICI_Coding_BtnID_D "Object InputControlInterface ICI ButtonCoding_D
(Parameter2)";
CM_ SG_ 673 ICI_Coding_BtnID_C "Object InputControlInterface ICI ButtonCoding_C
(Parameter2)";
CM_ SG_ 673 ICI_Coding_BtnID_B "Object InputControlInterface ICI ButtonCoding_B
(Parameter2)";
CM_ SG_ 673 ICI_Coding_BtnID_A "Object InputControlInterface ICI ButtonCoding_A
(Parameter2)";
CM_ SG_ 673 ICI_BtnID_D "Object InputControlInterface ICI ButtonID_D
(Parameter1)
for detailed Information refer to ICI Reference document";
CM_ SG_ 673 ICI_BtnID_C "Object InputControlInterface ICI ButtonID_C
(Parameter1)
for detailed Information refer to ICI Reference document";
CM_ SG_ 673 ICI_BtnID_B "Object InputControlInterface ICI ButtonID_B
(Parameter1)
for detailed Information refer to ICI Reference document";
CM_ SG_ 673 ICI_BtnID_A "Object InputControlInterface ICI ButtonID_A
(Parameter1)
for detailed Information refer to ICI Reference document";
CM_ BO_ 949 "For 2010MY and beyond, use for SCT (non-CGEA) and CGEA modules";
CM_ BO_ 2015 "OBDII Request ($7DF) messages are for FNOS 1.0.1 only.
Diagnostic Functional Addressing ($7DF) and Dual Rate Periodic messages are for FNOS I3 only.";
CM_ SG_ 709 DSPAMP_RDISP_WORD_Tx "Object:BezelDiagnostics.DSP_Bezel_Diag_Data";
CM_ SG_ 552 DSP_Treble_St "Object Audio.Treble.St

Level -7..0..7";
CM_ SG_ 552 DSP_VoiceFBVolume_Up "Object AudioControl.DSP_VR_Vol_updated";
CM_ SG_ 552 DSP_VoiceFBVolume_St "Object.VolumeControl.DSP_VR_Vol_Level.St 
0x0 No Volume
0x1 Vol_Step1
0x2 Vol_Step2
0x3 Vol_Step3
Cont.
0x1E Vol_Step30";
CM_ SG_ 552 DSP_TAVolume_Up "Object Audio.DSP_TA_Vol_Updated
Indicate user value recalls if the value is set to lower/upper border ";
CM_ SG_ 552 DSP_TAVolume_St "Object.VolumeControl.DSP_TA_Vol_Level.St

0x0 No Volume
0x1 Vol_Step1
0x2 Vol_Step2
0x3 Vol_Step3
Cont.
0x1E Vol_Step30";
CM_ SG_ 552 DSP_Shaker_St "Method DSP_Shaker.St";
CM_ SG_ 552 DSP_Reg_St "Object Tuner.REG";
CM_ SG_ 552 DSP_PhoneVolume_Up "Object.VolumeControl.DSP_Phone_Vol_Updated
";
CM_ SG_ 552 DSP_PhoneVolume_St "Object.VolumeControl.DSP_Phone_Vol_Level.St

0x0 No Volume
0x1 Vol_Step1
0x2 Vol_Step2
0x3 Vol_Step3
Cont.
0x1E Vol_Step30";
CM_ SG_ 552 DSP_NavCmdVolume_Up "Object Audio.NavCmdVolume_UP. DSP_Prompt_Vol_Updated
";
CM_ SG_ 552 DSP_NavCmdVolume_St "Object Audio.NavCmdVolume. DSP_Prompt_Vol_Level.St

0x0 No Volume
0x1 Vol_Step1
0x2 Vol_Step2
0x3 Vol_Step3
Cont.
0x1E Vol_Step30";
CM_ SG_ 552 DSP_Midrange_St "MidRange.St

Level -7..0..7";
CM_ SG_ 552 DSP_Fader_St "Object Audio.Fader

Fade.St

Level -7..0..7";
CM_ SG_ 552 DSP_DSPProgram_St "Object Audio.DSPProgram
";
CM_ SG_ 552 DSP_DSP_St "Object Audio.DSP

";
CM_ SG_ 552 DSP_Bass_St "Object Audio.Bass.St

Level -7..0..7";
CM_ SG_ 552 DSP_Balance_St "Object Audio.Balance.St

Level -7..0..7";
CM_ SG_ 552 DSP_AVC_St "Object Audio.AVC
Off, Level 1 .. Level 7

Object.AudioSettings.DSP_Speed_Comp_Vol.St 
";
CM_ SG_ 552 Audio_Demo_Status "Object.AudioSettings.Audio_Demo_Status";
CM_ BO_ 967 "2008' programs, Tx by IC;  updated on 5/6/05";
CM_ SG_ 867 LHS_Temp_Disp_Digit3 "Added for MY 08";
CM_ SG_ 867 LHS_Temp_Disp_Digit2 "Added for MY 08";
CM_ SG_ 867 LHS_Temp_Disp_Digit1 "Added for MY 08";
CM_ SG_ 867 EATC_LHS_Unit "Added for MY 08";
CM_ BO_ 866 "APIM Tx";
CM_ SG_ 865 RHS_Temp_Display_Digit3 "Added for MY 08";
CM_ SG_ 865 RHS_Temp_Display_Digit2 "Added for MY 08";
CM_ SG_ 865 RHS_Temp_Display_Digit1 "Added for MY 08";
CM_ SG_ 865 LHS_Temp_Display_Digit3 "Added for MY 08";
CM_ SG_ 865 LHS_Temp_Display_Digit2 "Added for MY 08";
CM_ SG_ 865 LHS_Temp_Display_Digit1 "Added for MY 08";
CM_ SG_ 865 EATC_RHS_Units "Added for MY 08";
CM_ SG_ 865 EATC_LHS_Units "Added for MY 08";
CM_ SG_ 1046 TCMode "Signal data set to 0x0 for ABS only vehicle option content";
CM_ SG_ 1046 DrvAntiLckLamp_D_Rq "update value table v8.34, not align w/GSDB, need etracker.  ABS & IPC implemented as updated.";
CM_ SG_ 1046 BpedMove_D_Actl "CCMGenSigTimeoutTime=1000";
CM_ SG_ 534 BrkObdData_No_Actl "Signal not transmitted on gas, diesel and HEV.  Only supported on PHEV.";
CM_ SG_ 534 BrkObdIndex_No_Actl "Signal not transmitted on gas, diesel and HEV.  Only supported on PHEV.";
CM_ SG_ 534 WhlRotatRr_No_Cnt "DCR 1833 to update Tx from GWM to EP100ms. Wheel Count signals are used by complex algorithm to determine Tire Pressure by Location & can't change from 20msec. (jweinfur)";
CM_ SG_ 534 WhlRotatRl_No_Cnt "DCR 1833 to update Tx from GWM to EP100ms. Wheel Count signals are used by complex algorithm to determine Tire Pressure by Location & can't change from 20msec. (jweinfur)";
CM_ SG_ 534 WhlRotatFr_No_Cnt "DCR 1833 to update Tx from GWM to EP100ms. Wheel Count signals are used by complex algorithm to determine Tire Pressure by Location & can't change from 20msec. (jweinfur)";
CM_ SG_ 534 WhlRotatFl_No_Cnt "DCR 1833 to update Tx from GWM to EP100ms. Wheel Count signals are used by complex algorithm to determine Tire Pressure by Location & can't change from 20msec. (jweinfur)";
CM_ BO_ 402 "FCDIM,APIM Tx";
CM_ SG_ 946 Dimming_Lvl "Refer to Vehicle Interior Illum Dimming Ctrl Sys Eng Spec, Table 2

";
CM_ SG_ 946 PrkBrkActv_B_Actl "Signal not transmitted on vehicles with electric park brake. ";
CM_ SG_ 1093 StopLamp_B_RqTrlrBrk "Signal not transmitted on all variants.";
CM_ BO_ 948 "$3B4 used by CGEA SPDJB";
CM_ BO_ 986 "APIM Tx";
CM_ BO_ 710 "TP message(Transport Protocol), Rx's HS3 APIM & MFD, transmitted immediately";
CM_ SG_ 487 Aioc_SetExtSrcOutpMd_Rq "Object Audio Management Audio Switch.SetBVCOutputMode";
CM_ SG_ 394 HaDsply_No_Cnt "Signal not transmitted on gas variants.";
CM_ SG_ 394 HaDsply_No_Cs "Signal not transmitted on gas variants.";
BA_DEF_ BO_  "FrameRouting" STRING ;
BA_DEF_ BO_  "NetworkInitialization" ENUM  "No","Yes";
BA_DEF_ BO_  "GenMsgStartDelayTime" INT 0 10000;
BA_DEF_ BO_  "GenMsgNrOfRepetition" INT 0 100;
BA_DEF_ BO_  "GenMsgDelayTime" INT 0 1000;
BA_DEF_ BO_  "GenMsgCycleTime" INT 0 100000;
BA_DEF_ BO_  "GenMsgSendType" ENUM  "FixedPeriodic","Event","EnabledPeriodic","NotUsed","NotUsed","EventPeriodic","NotUsed","NotUsed","NoMsgSendType";
BA_DEF_ SG_  "U_V710_MY2023_Tx" ENUM  "No","Yes";
BA_DEF_ SG_  "U_P708_MY2023_Tx" ENUM  "No","Yes";
BA_DEF_ SG_  "U_V713AV_MY2022_Tx" ENUM  "No","Yes";
BA_DEF_ SG_  "U_V713N_MY2022_Tx" ENUM  "No","Yes";
BA_DEF_ SG_  "ECGUsedTxSignal" ENUM  "No","Yes";
BA_DEF_ SG_  "U_V710_MY2023_Rx" ENUM  "No","Yes";
BA_DEF_ SG_  "U_P708_MY2023_Rx" ENUM  "No","Yes";
BA_DEF_ SG_  "U_V713AV_MY2022_Rx" ENUM  "No","Yes";
BA_DEF_ SG_  "U_V713N_MY2022_Rx" ENUM  "No","Yes";
BA_DEF_ SG_  "ECGUsedRxSignal" ENUM  "No","Yes";
BA_DEF_ SG_  "UsedOnPgmDBC" ENUM  "No","Yes";
BA_DEF_ SG_  "ContentDependant" ENUM  "No","Yes";
BA_DEF_ SG_  "GenSigStartValue" HEX 0 268435455;
BA_DEF_ SG_  "MetaData" ENUM  "No","Yes";
BA_DEF_ SG_  "WakeupSignal" ENUM  "No","Yes";
BA_DEF_ SG_  "GenSigInactiveValue" INT 0 100000;
BA_DEF_ SG_  "GenSigSendType" ENUM  "Cyclic","OnWrite","vector_leerstring","OnChange","vector_leerstring","IfActive","vector_leerstring","NoSigSendType";
BA_DEF_ BO_  "TpTxIndex" INT 0 536870911;
BA_DEF_ BO_  "OvtpPushApplication" ENUM  "FALSE","TRUE";
BA_DEF_ BO_  "SCP_FreshnessValueLength" INT 0 512;
BA_DEF_ BO_  "SCP_DataId" INT 0 17663;
BA_DEF_ BO_  "SCP_FreshnessValueTxLength" INT 0 512;
BA_DEF_ BO_  "SCP_AuthInfoTxLength" INT 0 512;
BA_DEF_ BO_  "SC_Message" ENUM  "No","Yes";
BA_DEF_ BO_  "GenMsgRoutingTimeoutTime" INT 0 5000;
BA_DEF_ BO_  "MessageGateway" ENUM  "No","Yes";
BA_DEF_ BO_  "NmAsrMessage" ENUM  "No","Yes";
BA_DEF_ BO_  "DiagState" ENUM  "No","Yes";
BA_DEF_ BO_  "DiagRequest" ENUM  "No","Yes";
BA_DEF_ BO_  "DiagResponse" ENUM  "No","Yes";
BA_DEF_ BO_  "GenMsgILSupport" ENUM  "No","Yes";
BA_DEF_DEF_  "FrameRouting" "";
BA_DEF_DEF_  "NetworkInitialization" "Yes";
BA_DEF_DEF_  "GenMsgStartDelayTime" 0;
BA_DEF_DEF_  "GenMsgNrOfRepetition" 1;
BA_DEF_DEF_  "GenMsgDelayTime" 20;
BA_DEF_DEF_  "GenMsgCycleTime" 0;
BA_DEF_DEF_  "GenMsgSendType" "NoMsgSendType";
BA_DEF_DEF_  "U_V710_MY2023_Tx" "No";
BA_DEF_DEF_  "U_P708_MY2023_Tx" "No";
BA_DEF_DEF_  "U_V713AV_MY2022_Tx" "No";
BA_DEF_DEF_  "U_V713N_MY2022_Tx" "No";
BA_DEF_DEF_  "ECGUsedTxSignal" "No";
BA_DEF_DEF_  "U_V710_MY2023_Rx" "No";
BA_DEF_DEF_  "U_P708_MY2023_Rx" "No";
BA_DEF_DEF_  "U_V713AV_MY2022_Rx" "No";
BA_DEF_DEF_  "U_V713N_MY2022_Rx" "No";
BA_DEF_DEF_  "ECGUsedRxSignal" "No";
BA_DEF_DEF_  "UsedOnPgmDBC" "Yes";
BA_DEF_DEF_  "ContentDependant" "No";
BA_DEF_DEF_  "GenSigStartValue" 0;
BA_DEF_DEF_  "MetaData" "No";
BA_DEF_DEF_  "WakeupSignal" "No";
BA_DEF_DEF_  "GenSigInactiveValue" 0;
BA_DEF_DEF_  "GenSigSendType" "NoSigSendType";
BA_DEF_DEF_  "TpTxIndex" 0;
BA_DEF_DEF_  "OvtpPushApplication" "FALSE";
BA_DEF_DEF_  "SCP_FreshnessValueLength" 64;
BA_DEF_DEF_  "SCP_DataId" 0;
BA_DEF_DEF_  "SCP_FreshnessValueTxLength" 11;
BA_DEF_DEF_  "SCP_AuthInfoTxLength" 53;
BA_DEF_DEF_  "SC_Message" "No";
BA_DEF_DEF_  "GenMsgRoutingTimeoutTime" 0;
BA_DEF_DEF_  "MessageGateway" "No";
BA_DEF_DEF_  "NmAsrMessage" "No";
BA_DEF_DEF_  "DiagState" "No";
BA_DEF_DEF_  "DiagRequest" "No";
BA_DEF_DEF_  "DiagResponse" "No";
BA_DEF_DEF_  "GenMsgILSupport" "Yes";
BA_ "FrameRouting" BO_ 516 "FD1_CAN,0x204;";
BA_ "GenMsgDelayTime" BO_ 516 0;
BA_ "FrameRouting" BO_ 514 "FD1_CAN,0x202;";
BA_ "GenMsgDelayTime" BO_ 514 10;
BA_ "FrameRouting" BO_ 381 "FD1_CAN,0x17D;";
BA_ "FrameRouting" BO_ 380 "FD1_CAN,0x17C;";
BA_ "FrameRouting" BO_ 377 "FD1_CAN,0x179;";
BA_ "FrameRouting" BO_ 376 "FD1_CAN,0x178;";
BA_ "FrameRouting" BO_ 373 "FD1_CAN,0x175;";
BA_ "GenMsgDelayTime" BO_ 373 10;
BA_ "FrameRouting" BO_ 355 "FD1_CAN,0x163;";
BA_ "FrameRouting" BO_ 342 "FD1_CAN,0x156;";
BA_ "TpTxIndex" BO_ 707 23;
BA_ "FrameRouting" BO_ 1102 "FD1_CAN,0x44E;";
BA_ "GenMsgCycleTime" BO_ 551 1000;
BA_ "GenMsgSendType" BO_ 551 5;
BA_ "FrameRouting" BO_ 673 "FD3_CAN,0x2A1;HS2_CAN,0x2A1";
BA_ "FrameRouting" BO_ 963 "FD1_CAN,0x3C3;";
BA_ "FrameRouting" BO_ 949 "FD1_CAN,0x3B5;";
BA_ "NetworkInitialization" BO_ 2015 0;
BA_ "GenMsgDelayTime" BO_ 2015 0;
BA_ "GenMsgSendType" BO_ 2015 1;
BA_ "DiagState" BO_ 2015 1;
BA_ "GenMsgILSupport" BO_ 2015 0;
BA_ "GenMsgCycleTime" BO_ 1076 100;
BA_ "GenMsgSendType" BO_ 1076 5;
BA_ "FrameRouting" BO_ 974 "FD1_CAN,0x36E;";
BA_ "GenMsgCycleTime" BO_ 810 1000;
BA_ "GenMsgSendType" BO_ 810 5;
BA_ "NetworkInitialization" BO_ 1492 0;
BA_ "GenMsgCycleTime" BO_ 1492 1000;
BA_ "GenMsgSendType" BO_ 1492 0;
BA_ "NmAsrMessage" BO_ 1492 1;
BA_ "GenMsgILSupport" BO_ 1492 0;
BA_ "TpTxIndex" BO_ 709 25;
BA_ "GenMsgCycleTime" BO_ 552 1000;
BA_ "GenMsgSendType" BO_ 552 5;
BA_ "FrameRouting" BO_ 967 "FD1_CAN,0x3C7;";
BA_ "FrameRouting" BO_ 1105 "FD1_CAN,0x451;FD3_CAN,0x451";
BA_ "NetworkInitialization" BO_ 867 0;
BA_ "GenMsgSendType" BO_ 867 1;
BA_ "GenMsgCycleTime" BO_ 866 1000;
BA_ "GenMsgSendType" BO_ 866 5;
BA_ "FrameRouting" BO_ 861 "MS1_CAN,0x357;";
BA_ "FrameRouting" BO_ 865 "MS1_CAN,0x356;";
BA_ "FrameRouting" BO_ 1046 "FD1_CAN,0x416;";
BA_ "FrameRouting" BO_ 534 "FD1_CAN,0x216;";
BA_ "GenMsgCycleTime" BO_ 402 1000;
BA_ "GenMsgSendType" BO_ 402 5;
BA_ "FrameRouting" BO_ 946 "FD1_CAN,0x3B3;";
BA_ "GenMsgCycleTime" BO_ 778 200;
BA_ "GenMsgSendType" BO_ 778 5;
BA_ "GenMsgCycleTime" BO_ 1093 100;
BA_ "GenMsgSendType" BO_ 1093 0;
BA_ "NetworkInitialization" BO_ 1879 0;
BA_ "GenMsgDelayTime" BO_ 1879 0;
BA_ "GenMsgSendType" BO_ 1879 1;
BA_ "DiagRequest" BO_ 1879 1;
BA_ "GenMsgILSupport" BO_ 1879 0;
BA_ "FrameRouting" BO_ 999 "MS1_CAN,0x3E7;";
BA_ "GenMsgCycleTime" BO_ 1002 1000;
BA_ "GenMsgSendType" BO_ 1002 5;
BA_ "FrameRouting" BO_ 948 "FD1_CAN,0x3B4;";
BA_ "GenMsgCycleTime" BO_ 986 1000;
BA_ "GenMsgSendType" BO_ 986 5;
BA_ "FrameRouting" BO_ 993 "MS1_CAN,0x3E1;";
BA_ "FrameRouting" BO_ 710 "MS1_CAN,0x2C6;";
BA_ "TpTxIndex" BO_ 710 26;
BA_ "NetworkInitialization" BO_ 1814 0;
BA_ "GenMsgDelayTime" BO_ 1814 0;
BA_ "GenMsgSendType" BO_ 1814 1;
BA_ "DiagRequest" BO_ 1814 1;
BA_ "GenMsgILSupport" BO_ 1814 0;
BA_ "FrameRouting" BO_ 997 "FD1_CAN,0x3E5;FD3_CAN,0x3E5";
BA_ "GenMsgSendType" BO_ 487 1;
BA_ "GenMsgSendType" BO_ 464 1;
BA_ "FrameRouting" BO_ 864 "MS1_CAN,0x355;";
BA_ "GenMsgCycleTime" BO_ 994 1000;
BA_ "GenMsgSendType" BO_ 994 5;
BA_ "NetworkInitialization" BO_ 1822 0;
BA_ "GenMsgDelayTime" BO_ 1822 0;
BA_ "GenMsgSendType" BO_ 1822 1;
BA_ "DiagResponse" BO_ 1822 1;
BA_ "GenMsgILSupport" BO_ 1822 0;
BA_ "FrameRouting" BO_ 394 "FD1_CAN,0x18A;FD3_CAN,0x18A";
BA_ "GenMsgDelayTime" BO_ 1068 10;
BA_ "GenMsgCycleTime" BO_ 1068 250;
BA_ "GenMsgSendType" BO_ 1068 5;
BA_ "GenMsgCycleTime" BO_ 1019 1000;
BA_ "GenMsgSendType" BO_ 1019 5;
BA_ "FrameRouting" BO_ 909 "FD1_CAN,0x38D;";
BA_ "NetworkInitialization" BO_ 1824 0;
BA_ "GenMsgDelayTime" BO_ 1824 0;
BA_ "GenMsgSendType" BO_ 1824 1;
BA_ "DiagRequest" BO_ 1824 1;
BA_ "GenMsgILSupport" BO_ 1824 0;
BA_ "GenSigStartValue" SG_ 516 EngAoutNActl_D_QF 1;
BA_ "MetaData" SG_ 516 EngAoutNActl_D_QF 1;
BA_ "U_V710_MY2023_Rx" SG_ 516 ApedPos_PcRate_ActlArb 1;
BA_ "U_P708_MY2023_Rx" SG_ 516 ApedPos_PcRate_ActlArb 1;
BA_ "U_V710_MY2023_Rx" SG_ 516 ApedPos_Pc_ActlArb 1;
BA_ "U_P708_MY2023_Rx" SG_ 516 ApedPos_Pc_ActlArb 1;
BA_ "U_V713AV_MY2022_Rx" SG_ 516 ApedPos_Pc_ActlArb 1;
BA_ "U_V713N_MY2022_Rx" SG_ 516 ApedPos_Pc_ActlArb 1;
BA_ "U_V710_MY2023_Rx" SG_ 516 ApedPosPcActl_D_Qf 1;
BA_ "U_P708_MY2023_Rx" SG_ 516 ApedPosPcActl_D_Qf 1;
BA_ "U_V713AV_MY2022_Rx" SG_ 516 ApedPosPcActl_D_Qf 1;
BA_ "U_V713N_MY2022_Rx" SG_ 516 ApedPosPcActl_D_Qf 1;
BA_ "GenSigStartValue" SG_ 516 ApedPosPcActl_D_Qf 1;
BA_ "MetaData" SG_ 516 ApedPosPcActl_D_Qf 1;
BA_ "U_V710_MY2023_Rx" SG_ 516 EngAout_N_Actl 1;
BA_ "U_P708_MY2023_Rx" SG_ 516 EngAout_N_Actl 1;
BA_ "U_V713AV_MY2022_Rx" SG_ 516 EngAout_N_Actl 1;
BA_ "U_V713N_MY2022_Rx" SG_ 516 EngAout_N_Actl 1;
BA_ "MetaData" SG_ 516 ApedPosPcActl_No_Cs 1;
BA_ "MetaData" SG_ 516 ApedPosPcActl_No_Cnt 1;
BA_ "U_V710_MY2023_Rx" SG_ 514 StrtrMtrCtlMsgTxt_D_Rq 1;
BA_ "U_P708_MY2023_Rx" SG_ 514 StrtrMtrCtlMsgTxt_D_Rq 1;
BA_ "U_V713AV_MY2022_Rx" SG_ 514 StrtrMtrCtlMsgTxt_D_Rq 1;
BA_ "U_V713N_MY2022_Rx" SG_ 514 StrtrMtrCtlMsgTxt_D_Rq 1;
BA_ "MetaData" SG_ 514 VehVActlEng_No_Cs 1;
BA_ "MetaData" SG_ 514 VehVActlEng_No_Cnt 1;
BA_ "U_V710_MY2023_Rx" SG_ 514 GearRvrse_D_Actl 1;
BA_ "U_P708_MY2023_Rx" SG_ 514 GearRvrse_D_Actl 1;
BA_ "U_V713AV_MY2022_Rx" SG_ 514 GearRvrse_D_Actl 1;
BA_ "U_V713N_MY2022_Rx" SG_ 514 GearRvrse_D_Actl 1;
BA_ "GenSigStartValue" SG_ 514 GearRvrse_D_Actl 7;
BA_ "U_P708_MY2023_Rx" SG_ 514 Veh_V_RqCcSet 1;
BA_ "U_V713AV_MY2022_Rx" SG_ 514 Veh_V_RqCcSet 1;
BA_ "U_V713N_MY2022_Rx" SG_ 514 Veh_V_RqCcSet 1;
BA_ "U_V710_MY2023_Rx" SG_ 514 VehVActlEng_D_Qf 1;
BA_ "U_P708_MY2023_Rx" SG_ 514 VehVActlEng_D_Qf 1;
BA_ "U_V713AV_MY2022_Rx" SG_ 514 VehVActlEng_D_Qf 1;
BA_ "U_V713N_MY2022_Rx" SG_ 514 VehVActlEng_D_Qf 1;
BA_ "MetaData" SG_ 514 VehVActlEng_D_Qf 1;
BA_ "U_V710_MY2023_Rx" SG_ 514 Veh_V_ActlEng 1;
BA_ "U_P708_MY2023_Rx" SG_ 514 Veh_V_ActlEng 1;
BA_ "U_V713AV_MY2022_Rx" SG_ 514 Veh_V_ActlEng 1;
BA_ "U_V713N_MY2022_Rx" SG_ 514 Veh_V_ActlEng 1;
BA_ "U_V710_MY2023_Rx" SG_ 514 StrtrMtrCtlMsgTxt_D2_Rq 1;
BA_ "U_P708_MY2023_Rx" SG_ 514 StrtrMtrCtlMsgTxt_D2_Rq 1;
BA_ "U_V713AV_MY2022_Rx" SG_ 514 StrtrMtrCtlMsgTxt_D2_Rq 1;
BA_ "U_V713N_MY2022_Rx" SG_ 514 StrtrMtrCtlMsgTxt_D2_Rq 1;
BA_ "U_V710_MY2023_Rx" SG_ 381 EngOilLife_T_Actl 1;
BA_ "U_P708_MY2023_Rx" SG_ 381 EngOilLife_T_Actl 1;
BA_ "U_V713AV_MY2022_Rx" SG_ 381 EngOilLife_T_Actl 1;
BA_ "U_V713N_MY2022_Rx" SG_ 381 EngOilLife_T_Actl 1;
BA_ "U_V710_MY2023_Rx" SG_ 381 EngOilSrvcMsgTxt_D_Rq 1;
BA_ "U_P708_MY2023_Rx" SG_ 381 EngOilSrvcMsgTxt_D_Rq 1;
BA_ "U_V713AV_MY2022_Rx" SG_ 381 EngOilSrvcMsgTxt_D_Rq 1;
BA_ "U_V713N_MY2022_Rx" SG_ 381 EngOilSrvcMsgTxt_D_Rq 1;
BA_ "U_V710_MY2023_Rx" SG_ 381 RunDryPrevent_B_Stat 1;
BA_ "U_P708_MY2023_Rx" SG_ 381 RunDryPrevent_B_Stat 1;
BA_ "U_V713AV_MY2022_Rx" SG_ 381 RunDryPrevent_B_Stat 1;
BA_ "U_V713N_MY2022_Rx" SG_ 381 RunDryPrevent_B_Stat 1;
BA_ "U_V710_MY2023_Rx" SG_ 381 DistToNextOilChange 1;
BA_ "U_P708_MY2023_Rx" SG_ 381 DistToNextOilChange 1;
BA_ "U_V713AV_MY2022_Rx" SG_ 381 DistToNextOilChange 1;
BA_ "U_V713N_MY2022_Rx" SG_ 381 DistToNextOilChange 1;
BA_ "U_V713AV_MY2022_Rx" SG_ 381 EngResv_Tq_Actl 1;
BA_ "U_V713N_MY2022_Rx" SG_ 381 EngResv_Tq_Actl 1;
BA_ "U_V713AV_MY2022_Rx" SG_ 381 Eng_Aa_CalcEvntCyc 1;
BA_ "U_V713N_MY2022_Rx" SG_ 381 Eng_Aa_CalcEvntCyc 1;
BA_ "U_V713AV_MY2022_Rx" SG_ 381 Eng_Aa_CalcEvntCbust 1;
BA_ "U_V713N_MY2022_Rx" SG_ 381 Eng_Aa_CalcEvntCbust 1;
BA_ "U_V710_MY2023_Rx" SG_ 381 WaterInFuel 1;
BA_ "U_P708_MY2023_Rx" SG_ 381 WaterInFuel 1;
BA_ "U_V713AV_MY2022_Rx" SG_ 381 WaterInFuel 1;
BA_ "U_V713N_MY2022_Rx" SG_ 381 WaterInFuel 1;
BA_ "U_V710_MY2023_Rx" SG_ 381 GlowIndication 1;
BA_ "U_P708_MY2023_Rx" SG_ 381 GlowIndication 1;
BA_ "U_V713AV_MY2022_Rx" SG_ 381 GlowIndication 1;
BA_ "U_V713N_MY2022_Rx" SG_ 381 GlowIndication 1;
BA_ "U_V710_MY2023_Rx" SG_ 380 GrdAsstAllw_D_DsplyPt 1;
BA_ "U_V713AV_MY2022_Rx" SG_ 380 GrdAsstAllw_D_DsplyPt 1;
BA_ "U_V713N_MY2022_Rx" SG_ 380 GrdAsstAllw_D_DsplyPt 1;
BA_ "GenSigStartValue" SG_ 380 GrdAsstAllw_D_DsplyPt 1;
BA_ "U_V710_MY2023_Rx" SG_ 380 EngOilLvlWarn_D_Rq1 1;
BA_ "U_P708_MY2023_Rx" SG_ 380 EngOilLvlWarn_D_Rq1 1;
BA_ "U_V713AV_MY2022_Rx" SG_ 380 EngOilLvlWarn_D_Rq1 1;
BA_ "U_V713N_MY2022_Rx" SG_ 380 EngOilLvlWarn_D_Rq1 1;
BA_ "WakeupSignal" SG_ 380 EngOilLvlWarn_D_Rq1 1;
BA_ "U_P708_MY2023_Rx" SG_ 380 EngExhBrkOnLamp_B_Rq 1;
BA_ "U_V713AV_MY2022_Rx" SG_ 380 EngExhBrkOnLamp_B_Rq 1;
BA_ "U_V713N_MY2022_Rx" SG_ 380 EngExhBrkOnLamp_B_Rq 1;
BA_ "U_P708_MY2023_Rx" SG_ 380 EngExhBrkAutoLamp_B_Rq 1;
BA_ "U_V713AV_MY2022_Rx" SG_ 380 EngExhBrkAutoLamp_B_Rq 1;
BA_ "U_V713N_MY2022_Rx" SG_ 380 EngExhBrkAutoLamp_B_Rq 1;
BA_ "U_V713AV_MY2022_Rx" SG_ 380 EngAout_N_MxAllw 1;
BA_ "U_V713N_MY2022_Rx" SG_ 380 EngAout_N_MxAllw 1;
BA_ "U_V713AV_MY2022_Rx" SG_ 380 EngAoutIdl_N_MnAllw 1;
BA_ "U_V713N_MY2022_Rx" SG_ 380 EngAoutIdl_N_MnAllw 1;
BA_ "MetaData" SG_ 380 EngAoutIdlRqEc_No_Cs 1;
BA_ "MetaData" SG_ 380 EngAoutIdlRqEc_No_Cnt 1;
BA_ "U_V713AV_MY2022_Rx" SG_ 380 EngAoutIdl_N_RqEc 1;
BA_ "U_V713N_MY2022_Rx" SG_ 380 EngAoutIdl_N_RqEc 1;
BA_ "U_V713AV_MY2022_Rx" SG_ 380 EngExhBrkMde_D_Actl 1;
BA_ "U_V713N_MY2022_Rx" SG_ 380 EngExhBrkMde_D_Actl 1;
BA_ "U_P708_MY2023_Rx" SG_ 377 TrnManShif_D_IndDrv 1;
BA_ "U_V710_MY2023_Rx" SG_ 377 TrnManShif_D_IndDrv 1;
BA_ "U_V713AV_MY2022_Rx" SG_ 377 TrnManShif_D_IndDrv 1;
BA_ "U_V713N_MY2022_Rx" SG_ 377 TrnManShif_D_IndDrv 1;
BA_ "U_V713AV_MY2022_Rx" SG_ 377 EngFuelCutFull_B_Inhbt 1;
BA_ "U_V713N_MY2022_Rx" SG_ 377 EngFuelCutFull_B_Inhbt 1;
BA_ "U_V713AV_MY2022_Rx" SG_ 377 EngDecelFuelCut_B_Allw 1;
BA_ "U_V713N_MY2022_Rx" SG_ 377 EngDecelFuelCut_B_Allw 1;
BA_ "U_V710_MY2023_Rx" SG_ 377 EngAout_Tq_Actl 1;
BA_ "U_P708_MY2023_Rx" SG_ 377 EngAout_Tq_Actl 1;
BA_ "U_V713AV_MY2022_Rx" SG_ 377 EngAout_Tq_Actl 1;
BA_ "U_V713N_MY2022_Rx" SG_ 377 EngAout_Tq_Actl 1;
BA_ "U_P708_MY2023_Rx" SG_ 377 TrnManShifGear_D_IndDrv 1;
BA_ "U_V710_MY2023_Rx" SG_ 377 TrnManShifGear_D_IndDrv 1;
BA_ "U_V713AV_MY2022_Rx" SG_ 377 TrnManShifGear_D_IndDrv 1;
BA_ "U_V713N_MY2022_Rx" SG_ 377 TrnManShifGear_D_IndDrv 1;
BA_ "U_V710_MY2023_Rx" SG_ 377 FuelFlw_Vl_Dsply 1;
BA_ "U_P708_MY2023_Rx" SG_ 377 FuelFlw_Vl_Dsply 1;
BA_ "U_V713AV_MY2022_Rx" SG_ 377 FuelFlw_Vl_Dsply 1;
BA_ "U_V713N_MY2022_Rx" SG_ 377 FuelFlw_Vl_Dsply 1;
BA_ "U_V710_MY2023_Rx" SG_ 377 FuelFillInlet_B_Dsply 1;
BA_ "U_P708_MY2023_Rx" SG_ 377 FuelFillInlet_B_Dsply 1;
BA_ "U_V713AV_MY2022_Rx" SG_ 377 FuelFillInlet_B_Dsply 1;
BA_ "U_V713N_MY2022_Rx" SG_ 377 FuelFillInlet_B_Dsply 1;
BA_ "U_V710_MY2023_Rx" SG_ 377 EngSrvcRqd_B_Rq 1;
BA_ "U_P708_MY2023_Rx" SG_ 377 EngSrvcRqd_B_Rq 1;
BA_ "U_V713AV_MY2022_Rx" SG_ 377 EngSrvcRqd_B_Rq 1;
BA_ "U_V713N_MY2022_Rx" SG_ 377 EngSrvcRqd_B_Rq 1;
BA_ "U_V710_MY2023_Rx" SG_ 377 OdoCount 1;
BA_ "U_P708_MY2023_Rx" SG_ 377 OdoCount 1;
BA_ "U_V713AV_MY2022_Rx" SG_ 377 OdoCount 1;
BA_ "U_V713N_MY2022_Rx" SG_ 377 OdoCount 1;
BA_ "U_V710_MY2023_Rx" SG_ 377 EngOilLife_Pc_Actl 1;
BA_ "U_P708_MY2023_Rx" SG_ 377 EngOilLife_Pc_Actl 1;
BA_ "U_V713AV_MY2022_Rx" SG_ 377 EngOilLife_Pc_Actl 1;
BA_ "U_V713N_MY2022_Rx" SG_ 377 EngOilLife_Pc_Actl 1;
BA_ "U_V713AV_MY2022_Rx" SG_ 377 EngTqSlwDly_T_Est 1;
BA_ "U_V713N_MY2022_Rx" SG_ 377 EngTqSlwDly_T_Est 1;
BA_ "U_V713AV_MY2022_Rx" SG_ 377 TrnKickDown_B_RqDrv 1;
BA_ "U_V713N_MY2022_Rx" SG_ 377 TrnKickDown_B_RqDrv 1;
BA_ "U_V710_MY2023_Rx" SG_ 377 FuelFilterLamp_B_Dsply 1;
BA_ "U_P708_MY2023_Rx" SG_ 377 FuelFilterLamp_B_Dsply 1;
BA_ "U_V713AV_MY2022_Rx" SG_ 377 FuelFilterLamp_B_Dsply 1;
BA_ "U_V713N_MY2022_Rx" SG_ 377 FuelFilterLamp_B_Dsply 1;
BA_ "U_V713AV_MY2022_Rx" SG_ 377 AirCondRec_B_Rq 1;
BA_ "U_V713N_MY2022_Rx" SG_ 377 AirCondRec_B_Rq 1;
BA_ "U_V710_MY2023_Rx" SG_ 377 AirCondClutch_B_Stats 1;
BA_ "U_P708_MY2023_Rx" SG_ 377 AirCondClutch_B_Stats 1;
BA_ "U_V713AV_MY2022_Rx" SG_ 377 AirCondClutch_B_Stats 1;
BA_ "U_V713N_MY2022_Rx" SG_ 377 AirCondClutch_B_Stats 1;
BA_ "MetaData" SG_ 377 EngAoutTqActl_D_Qf 1;
BA_ "U_V710_MY2023_Rx" SG_ 376 GasPrtc_D_RqDsply 1;
BA_ "U_P708_MY2023_Rx" SG_ 376 GasPrtc_D_RqDsply 1;
BA_ "U_V713AV_MY2022_Rx" SG_ 376 GasPrtc_D_RqDsply 1;
BA_ "U_V713N_MY2022_Rx" SG_ 376 GasPrtc_D_RqDsply 1;
BA_ "U_V713AV_MY2022_Rx" SG_ 376 LnchCtlSys_D_Stat 1;
BA_ "U_V713N_MY2022_Rx" SG_ 376 LnchCtlSys_D_Stat 1;
BA_ "U_V710_MY2023_Rx" SG_ 376 AslIconDsply_D_Rq 1;
BA_ "U_P708_MY2023_Rx" SG_ 376 AslIconDsply_D_Rq 1;
BA_ "U_V713AV_MY2022_Rx" SG_ 376 AslIconDsply_D_Rq 1;
BA_ "U_V713N_MY2022_Rx" SG_ 376 AslIconDsply_D_Rq 1;
BA_ "U_V710_MY2023_Rx" SG_ 376 AslChime_B_Rq 1;
BA_ "U_P708_MY2023_Rx" SG_ 376 AslChime_B_Rq 1;
BA_ "U_V713AV_MY2022_Rx" SG_ 376 AslChime_B_Rq 1;
BA_ "U_V713N_MY2022_Rx" SG_ 376 AslChime_B_Rq 1;
BA_ "U_V710_MY2023_Rx" SG_ 376 HvacHtrCore2_Te_Actl 1;
BA_ "U_P708_MY2023_Rx" SG_ 376 HvacHtrCore2_Te_Actl 1;
BA_ "U_V713AV_MY2022_Rx" SG_ 376 HvacHtrCore2_Te_Actl 1;
BA_ "U_V713N_MY2022_Rx" SG_ 376 HvacHtrCore2_Te_Actl 1;
BA_ "U_P708_MY2023_Rx" SG_ 376 EcssLamp_D_RqDsply 1;
BA_ "U_V713AV_MY2022_Rx" SG_ 376 EcssLamp_D_RqDsply 1;
BA_ "U_V713N_MY2022_Rx" SG_ 376 EcssLamp_D_RqDsply 1;
BA_ "U_V713AV_MY2022_Rx" SG_ 376 AirAmbTe_D_Qf 1;
BA_ "U_V713N_MY2022_Rx" SG_ 376 AirAmbTe_D_Qf 1;
BA_ "GenSigStartValue" SG_ 376 AirAmbTe_D_Qf 1;
BA_ "MetaData" SG_ 376 AirAmbTe_D_Qf 1;
BA_ "U_V713AV_MY2022_Rx" SG_ 376 AirAmb_Te_ActlFilt 1;
BA_ "U_V713N_MY2022_Rx" SG_ 376 AirAmb_Te_ActlFilt 1;
BA_ "U_V713AV_MY2022_Rx" SG_ 376 AirAmb_Te_Actl 1;
BA_ "U_V713N_MY2022_Rx" SG_ 376 AirAmb_Te_Actl 1;
BA_ "U_V713AV_MY2022_Rx" SG_ 376 AirAmb_P_Actl 1;
BA_ "U_V713N_MY2022_Rx" SG_ 376 AirAmb_P_Actl 1;
BA_ "U_V710_MY2023_Rx" SG_ 373 DieslPrtc2_D_RqDsply 1;
BA_ "U_P708_MY2023_Rx" SG_ 373 DieslPrtc2_D_RqDsply 1;
BA_ "U_V713AV_MY2022_Rx" SG_ 373 EngTurboMde_D_Actl 1;
BA_ "U_V713N_MY2022_Rx" SG_ 373 EngTurboMde_D_Actl 1;
BA_ "U_V710_MY2023_Rx" SG_ 373 EngTeColdPrtct_D_Stats 1;
BA_ "U_P708_MY2023_Rx" SG_ 373 EngTeColdPrtct_D_Stats 1;
BA_ "U_V713AV_MY2022_Rx" SG_ 373 EngTeColdPrtct_D_Stats 1;
BA_ "U_V713N_MY2022_Rx" SG_ 373 EngTeColdPrtct_D_Stats 1;
BA_ "U_V710_MY2023_Rx" SG_ 373 EngExhOvrTe_B_RqDsply 1;
BA_ "U_P708_MY2023_Rx" SG_ 373 EngExhOvrTe_B_RqDsply 1;
BA_ "U_V713AV_MY2022_Rx" SG_ 373 EngExhOvrTe_B_RqDsply 1;
BA_ "U_V713N_MY2022_Rx" SG_ 373 EngExhOvrTe_B_RqDsply 1;
BA_ "U_V713AV_MY2022_Rx" SG_ 373 EngPtoMde_D_Rq 1;
BA_ "U_V713N_MY2022_Rx" SG_ 373 EngPtoMde_D_Rq 1;
BA_ "U_V710_MY2023_Rx" SG_ 355 AutoRgenTxt_B_RqDsply 1;
BA_ "U_P708_MY2023_Rx" SG_ 355 AutoRgenTxt_B_RqDsply 1;
BA_ "U_P708_MY2023_Rx" SG_ 355 ManRgenVeh_V_MinAllw 1;
BA_ "U_V710_MY2023_Rx" SG_ 355 ManRgenTxt_D_RqDsply 1;
BA_ "U_P708_MY2023_Rx" SG_ 355 ManRgenTxt_D_RqDsply 1;
BA_ "U_V710_MY2023_Rx" SG_ 355 ManRgenSoot_Pc_RqDsply 1;
BA_ "U_P708_MY2023_Rx" SG_ 355 ManRgenSoot_Pc_RqDsply 1;
BA_ "U_P708_MY2023_Rx" SG_ 355 ManRgenInhbt_T_RqDsply 1;
BA_ "U_P708_MY2023_Rx" SG_ 355 ManRgenInhbt_Pc_Soot 1;
BA_ "U_V710_MY2023_Rx" SG_ 355 DieslMsgTxt_D_Rq 1;
BA_ "U_P708_MY2023_Rx" SG_ 355 DieslMsgTxt_D_Rq 1;
BA_ "U_P708_MY2023_Rx" SG_ 355 ManRgenInhbt_L_RqDsply 1;
BA_ "U_V710_MY2023_Rx" SG_ 342 FuelRange_L2_DsplyEng 1;
BA_ "U_P708_MY2023_Rx" SG_ 342 FuelRange_L2_DsplyEng 1;
BA_ "U_P708_MY2023_Rx" SG_ 342 EngTeColdPrtct_B_Rq 1;
BA_ "U_V713AV_MY2022_Rx" SG_ 342 HtrLoop_B_Stat 1;
BA_ "U_V713N_MY2022_Rx" SG_ 342 HtrLoop_B_Stat 1;
BA_ "U_V713AV_MY2022_Rx" SG_ 342 TqmTerrMdeChng_D_Rdy 1;
BA_ "U_V713N_MY2022_Rx" SG_ 342 TqmTerrMdeChng_D_Rdy 1;
BA_ "U_V713AV_MY2022_Rx" SG_ 342 TqmTerrMde_D_Actl 1;
BA_ "U_V713N_MY2022_Rx" SG_ 342 TqmTerrMde_D_Actl 1;
BA_ "U_V710_MY2023_Rx" SG_ 342 EngOvrhtMitgActv_D_Ind 1;
BA_ "U_P708_MY2023_Rx" SG_ 342 EngOvrhtMitgActv_D_Ind 1;
BA_ "U_V713AV_MY2022_Rx" SG_ 342 EngOvrhtMitgActv_D_Ind 1;
BA_ "U_V713N_MY2022_Rx" SG_ 342 EngOvrhtMitgActv_D_Ind 1;
BA_ "U_V713AV_MY2022_Rx" SG_ 342 EngGoutLss_Tq_Est 1;
BA_ "U_V713N_MY2022_Rx" SG_ 342 EngGoutLss_Tq_Est 1;
BA_ "U_V710_MY2023_Rx" SG_ 342 EngClntTe_D_Qf 1;
BA_ "U_P708_MY2023_Rx" SG_ 342 EngClntTe_D_Qf 1;
BA_ "U_V713AV_MY2022_Rx" SG_ 342 EngClntTe_D_Qf 1;
BA_ "U_V713N_MY2022_Rx" SG_ 342 EngClntTe_D_Qf 1;
BA_ "MetaData" SG_ 342 EngClntTe_D_Qf 1;
BA_ "U_V713AV_MY2022_Rx" SG_ 342 EngAcsyArcPmp_Tq_Actl 1;
BA_ "U_V713N_MY2022_Rx" SG_ 342 EngAcsyArcPmp_Tq_Actl 1;
BA_ "U_V713AV_MY2022_Rx" SG_ 342 EngOilLvlDsply_D_Rq 1;
BA_ "U_V713N_MY2022_Rx" SG_ 342 EngOilLvlDsply_D_Rq 1;
BA_ "U_P708_MY2023_Rx" SG_ 342 EngOil_Te_Actl 1;
BA_ "U_V713AV_MY2022_Rx" SG_ 342 EngOil_Te_Actl 1;
BA_ "U_V713N_MY2022_Rx" SG_ 342 EngOil_Te_Actl 1;
BA_ "U_V710_MY2023_Rx" SG_ 342 EngClnt_Te_Actl 1;
BA_ "U_P708_MY2023_Rx" SG_ 342 EngClnt_Te_Actl 1;
BA_ "U_V713AV_MY2022_Rx" SG_ 342 EngClnt_Te_Actl 1;
BA_ "U_V713N_MY2022_Rx" SG_ 342 EngClnt_Te_Actl 1;
BA_ "U_V710_MY2023_Tx" SG_ 707 SSPClnt_SSPSrv_WORD_Tx 1;
BA_ "U_P708_MY2023_Tx" SG_ 707 SSPClnt_SSPSrv_WORD_Tx 1;
BA_ "U_V713AV_MY2022_Tx" SG_ 707 SSPClnt_SSPSrv_WORD_Tx 1;
BA_ "U_V713N_MY2022_Tx" SG_ 707 SSPClnt_SSPSrv_WORD_Tx 1;
BA_ "U_P708_MY2023_Rx" SG_ 1102 SelDrvMdePos12_D_Stat 1;
BA_ "U_V713AV_MY2022_Rx" SG_ 1102 SelDrvMdePos12_D_Stat 1;
BA_ "U_V713N_MY2022_Rx" SG_ 1102 SelDrvMdePos12_D_Stat 1;
BA_ "GenSigStartValue" SG_ 1102 SelDrvMdePos12_D_Stat 31;
BA_ "U_P708_MY2023_Rx" SG_ 1102 SelDrvMdePos11_D_Stat 1;
BA_ "U_V713AV_MY2022_Rx" SG_ 1102 SelDrvMdePos11_D_Stat 1;
BA_ "U_V713N_MY2022_Rx" SG_ 1102 SelDrvMdePos11_D_Stat 1;
BA_ "GenSigStartValue" SG_ 1102 SelDrvMdePos11_D_Stat 31;
BA_ "U_P708_MY2023_Rx" SG_ 1102 SelDrvMdePos10_D_Stat 1;
BA_ "U_V713AV_MY2022_Rx" SG_ 1102 SelDrvMdePos10_D_Stat 1;
BA_ "U_V713N_MY2022_Rx" SG_ 1102 SelDrvMdePos10_D_Stat 1;
BA_ "GenSigStartValue" SG_ 1102 SelDrvMdePos10_D_Stat 31;
BA_ "U_P708_MY2023_Rx" SG_ 1102 SelDrvMdePos09_D_Stat 1;
BA_ "U_V713AV_MY2022_Rx" SG_ 1102 SelDrvMdePos09_D_Stat 1;
BA_ "U_V713N_MY2022_Rx" SG_ 1102 SelDrvMdePos09_D_Stat 1;
BA_ "GenSigStartValue" SG_ 1102 SelDrvMdePos09_D_Stat 31;
BA_ "U_P708_MY2023_Rx" SG_ 1102 SelDrvMdePos08_D_Stat 1;
BA_ "U_V713AV_MY2022_Rx" SG_ 1102 SelDrvMdePos08_D_Stat 1;
BA_ "U_V713N_MY2022_Rx" SG_ 1102 SelDrvMdePos08_D_Stat 1;
BA_ "GenSigStartValue" SG_ 1102 SelDrvMdePos08_D_Stat 31;
BA_ "U_P708_MY2023_Rx" SG_ 1102 SelDrvMdePos07_D_Stat 1;
BA_ "U_V713AV_MY2022_Rx" SG_ 1102 SelDrvMdePos07_D_Stat 1;
BA_ "U_V713N_MY2022_Rx" SG_ 1102 SelDrvMdePos07_D_Stat 1;
BA_ "GenSigStartValue" SG_ 1102 SelDrvMdePos07_D_Stat 31;
BA_ "U_P708_MY2023_Rx" SG_ 1102 SelDrvMdePos06_D_Stat 1;
BA_ "U_V713AV_MY2022_Rx" SG_ 1102 SelDrvMdePos06_D_Stat 1;
BA_ "U_V713N_MY2022_Rx" SG_ 1102 SelDrvMdePos06_D_Stat 1;
BA_ "GenSigStartValue" SG_ 1102 SelDrvMdePos06_D_Stat 31;
BA_ "U_P708_MY2023_Rx" SG_ 1102 SelDrvMdePos05_D_Stat 1;
BA_ "U_V713AV_MY2022_Rx" SG_ 1102 SelDrvMdePos05_D_Stat 1;
BA_ "U_V713N_MY2022_Rx" SG_ 1102 SelDrvMdePos05_D_Stat 1;
BA_ "GenSigStartValue" SG_ 1102 SelDrvMdePos05_D_Stat 31;
BA_ "U_P708_MY2023_Rx" SG_ 1102 SelDrvMdePos04_D_Stat 1;
BA_ "U_V713AV_MY2022_Rx" SG_ 1102 SelDrvMdePos04_D_Stat 1;
BA_ "U_V713N_MY2022_Rx" SG_ 1102 SelDrvMdePos04_D_Stat 1;
BA_ "GenSigStartValue" SG_ 1102 SelDrvMdePos04_D_Stat 31;
BA_ "U_P708_MY2023_Rx" SG_ 1102 SelDrvMdePos03_D_Stat 1;
BA_ "U_V713AV_MY2022_Rx" SG_ 1102 SelDrvMdePos03_D_Stat 1;
BA_ "U_V713N_MY2022_Rx" SG_ 1102 SelDrvMdePos03_D_Stat 1;
BA_ "GenSigStartValue" SG_ 1102 SelDrvMdePos03_D_Stat 31;
BA_ "U_P708_MY2023_Rx" SG_ 1102 SelDrvMdePos02_D_Stat 1;
BA_ "U_V713AV_MY2022_Rx" SG_ 1102 SelDrvMdePos02_D_Stat 1;
BA_ "U_V713N_MY2022_Rx" SG_ 1102 SelDrvMdePos02_D_Stat 1;
BA_ "GenSigStartValue" SG_ 1102 SelDrvMdePos02_D_Stat 31;
BA_ "U_P708_MY2023_Rx" SG_ 1102 SelDrvMdePos01_D_Stat 1;
BA_ "U_V713AV_MY2022_Rx" SG_ 1102 SelDrvMdePos01_D_Stat 1;
BA_ "U_V713N_MY2022_Rx" SG_ 1102 SelDrvMdePos01_D_Stat 1;
BA_ "GenSigStartValue" SG_ 1102 SelDrvMdePos01_D_Stat 31;
BA_ "GenSigSendType" SG_ 551 PrkBrkPerfMnuOn_D_Stat 3;
BA_ "GenSigSendType" SG_ 551 PrkBrkPerfButtn_D_Stat 3;
BA_ "GenSigSendType" SG_ 551 EcoIdl_D_Rq 3;
BA_ "GenSigSendType" SG_ 551 Rba_D_Rq 3;
BA_ "U_V710_MY2023_Rx" SG_ 551 OneTEditActv_B_RqMnu 1;
BA_ "U_P708_MY2023_Rx" SG_ 551 OneTEditActv_B_RqMnu 1;
BA_ "U_V713AV_MY2022_Rx" SG_ 551 OneTEditActv_B_RqMnu 1;
BA_ "U_V713N_MY2022_Rx" SG_ 551 OneTEditActv_B_RqMnu 1;
BA_ "ECGUsedRxSignal" SG_ 551 OneTEditActv_B_RqMnu 1;
BA_ "GenSigSendType" SG_ 551 OneTEditActv_B_RqMnu 3;
BA_ "U_V710_MY2023_Rx" SG_ 551 GoTElementEdit_No_RqMnu 1;
BA_ "U_P708_MY2023_Rx" SG_ 551 GoTElementEdit_No_RqMnu 1;
BA_ "U_V713AV_MY2022_Rx" SG_ 551 GoTElementEdit_No_RqMnu 1;
BA_ "U_V713N_MY2022_Rx" SG_ 551 GoTElementEdit_No_RqMnu 1;
BA_ "ECGUsedRxSignal" SG_ 551 GoTElementEdit_No_RqMnu 1;
BA_ "GenSigSendType" SG_ 551 GoTElementEdit_No_RqMnu 3;
BA_ "GenSigSendType" SG_ 551 ChrgToPcEdit_Pc_RqMnu 3;
BA_ "GenSigStartValue" SG_ 551 ChrgToPcEdit_Pc_RqMnu 126;
BA_ "GenSigSendType" SG_ 551 PrcondEdit_D_RqMnu 3;
BA_ "GenSigSendType" SG_ 551 BattTracLoThres_D_Rq 3;
BA_ "GenSigSendType" SG_ 551 EmPrflNo_D_Rq 3;
BA_ "GenSigSendType" SG_ 551 EmPrflButtnAssoc_D_Rq 3;
BA_ "GenSigSendType" SG_ 551 EmPrflKeyAssoc_D_Rq 3;
BA_ "GenSigSendType" SG_ 551 Em_D_Stat 3;
BA_ "WakeupSignal" SG_ 551 Em_D_Stat 1;
BA_ "GenSigSendType" SG_ 551 PmCabnLvl_D_Stat 3;
BA_ "GenSigSendType" SG_ 551 PmCabn_D_Stat 3;
BA_ "GenSigSendType" SG_ 551 Cntr_Plg_Mode_Cmd 3;
BA_ "WakeupSignal" SG_ 551 Cntr_Plg_Mode_Cmd 1;
BA_ "GenSigStartValue" SG_ 551 Btt_L_Actl2 126;
BA_ "GenSigSendType" SG_ 551 ChrgCrdLckEnbl_B_Stat 3;
BA_ "GenSigSendType" SG_ 551 PwRnngBoardT_D_Rq 3;
BA_ "GenSigSendType" SG_ 551 PwRnngBoardMde_D_Rq 3;
BA_ "GenSigSendType" SG_ 551 PwRnngBoardSwtch_D_Rq 3;
BA_ "GenSigSendType" SG_ 551 ChrgOvrdExitScrn_D_Rq 3;
BA_ "GenSigSendType" SG_ 551 TjaLaneBiasEnbl_D_RqMnu 3;
BA_ "U_V710_MY2023_Rx" SG_ 673 ICI_Coding_BtnID_D 1;
BA_ "U_P708_MY2023_Rx" SG_ 673 ICI_Coding_BtnID_D 1;
BA_ "U_V713AV_MY2022_Rx" SG_ 673 ICI_Coding_BtnID_D 1;
BA_ "U_V713N_MY2022_Rx" SG_ 673 ICI_Coding_BtnID_D 1;
BA_ "U_V710_MY2023_Rx" SG_ 673 ICI_Coding_BtnID_C 1;
BA_ "U_P708_MY2023_Rx" SG_ 673 ICI_Coding_BtnID_C 1;
BA_ "U_V713AV_MY2022_Rx" SG_ 673 ICI_Coding_BtnID_C 1;
BA_ "U_V713N_MY2022_Rx" SG_ 673 ICI_Coding_BtnID_C 1;
BA_ "U_V710_MY2023_Rx" SG_ 673 ICI_Coding_BtnID_B 1;
BA_ "U_P708_MY2023_Rx" SG_ 673 ICI_Coding_BtnID_B 1;
BA_ "U_V713AV_MY2022_Rx" SG_ 673 ICI_Coding_BtnID_B 1;
BA_ "U_V713N_MY2022_Rx" SG_ 673 ICI_Coding_BtnID_B 1;
BA_ "U_V710_MY2023_Rx" SG_ 673 ICI_Coding_BtnID_A 1;
BA_ "U_P708_MY2023_Rx" SG_ 673 ICI_Coding_BtnID_A 1;
BA_ "U_V713AV_MY2022_Rx" SG_ 673 ICI_Coding_BtnID_A 1;
BA_ "U_V713N_MY2022_Rx" SG_ 673 ICI_Coding_BtnID_A 1;
BA_ "U_V710_MY2023_Rx" SG_ 673 ICI_BtnID_D 1;
BA_ "U_P708_MY2023_Rx" SG_ 673 ICI_BtnID_D 1;
BA_ "U_V713AV_MY2022_Rx" SG_ 673 ICI_BtnID_D 1;
BA_ "U_V713N_MY2022_Rx" SG_ 673 ICI_BtnID_D 1;
BA_ "GenSigStartValue" SG_ 673 ICI_BtnID_D 255;
BA_ "U_V710_MY2023_Rx" SG_ 673 ICI_BtnID_C 1;
BA_ "U_P708_MY2023_Rx" SG_ 673 ICI_BtnID_C 1;
BA_ "U_V713AV_MY2022_Rx" SG_ 673 ICI_BtnID_C 1;
BA_ "U_V713N_MY2022_Rx" SG_ 673 ICI_BtnID_C 1;
BA_ "GenSigStartValue" SG_ 673 ICI_BtnID_C 255;
BA_ "U_V710_MY2023_Rx" SG_ 673 ICI_BtnID_B 1;
BA_ "U_P708_MY2023_Rx" SG_ 673 ICI_BtnID_B 1;
BA_ "U_V713AV_MY2022_Rx" SG_ 673 ICI_BtnID_B 1;
BA_ "U_V713N_MY2022_Rx" SG_ 673 ICI_BtnID_B 1;
BA_ "GenSigStartValue" SG_ 673 ICI_BtnID_B 255;
BA_ "U_V710_MY2023_Rx" SG_ 673 ICI_BtnID_A 1;
BA_ "U_P708_MY2023_Rx" SG_ 673 ICI_BtnID_A 1;
BA_ "U_V713AV_MY2022_Rx" SG_ 673 ICI_BtnID_A 1;
BA_ "U_V713N_MY2022_Rx" SG_ 673 ICI_BtnID_A 1;
BA_ "GenSigStartValue" SG_ 673 ICI_BtnID_A 255;
BA_ "WakeupSignal" SG_ 963 ImpactEvntFdbck_D_Stat 1;
BA_ "U_V710_MY2023_Rx" SG_ 963 WrlssAcsyChrgInhbt_B_Rq 1;
BA_ "U_P708_MY2023_Rx" SG_ 963 WrlssAcsyChrgInhbt_B_Rq 1;
BA_ "U_V713N_MY2022_Rx" SG_ 963 WrlssAcsyChrgInhbt_B_Rq 1;
BA_ "U_V710_MY2023_Rx" SG_ 963 HeadLampLoOut_B_Stat 1;
BA_ "U_V713AV_MY2022_Rx" SG_ 963 HeadLampLoOut_B_Stat 1;
BA_ "U_V713N_MY2022_Rx" SG_ 963 HeadLampLoOut_B_Stat 1;
BA_ "U_V710_MY2023_Rx" SG_ 963 PrkLightChime_B_Rq 1;
BA_ "U_P708_MY2023_Rx" SG_ 963 PrkLightChime_B_Rq 1;
BA_ "U_V713AV_MY2022_Rx" SG_ 963 PrkLightChime_B_Rq 1;
BA_ "U_V713N_MY2022_Rx" SG_ 963 PrkLightChime_B_Rq 1;
BA_ "U_V713AV_MY2022_Rx" SG_ 963 TrnNotInPrkChime_B_Rq 1;
BA_ "U_V713N_MY2022_Rx" SG_ 963 TrnNotInPrkChime_B_Rq 1;
BA_ "U_V710_MY2023_Rx" SG_ 963 KeyInIgnWarn_B_Cmd 1;
BA_ "U_P708_MY2023_Rx" SG_ 963 KeyInIgnWarn_B_Cmd 1;
BA_ "U_V713AV_MY2022_Rx" SG_ 963 KeyInIgnWarn_B_Cmd 1;
BA_ "U_V713N_MY2022_Rx" SG_ 963 KeyInIgnWarn_B_Cmd 1;
BA_ "WakeupSignal" SG_ 963 KeyInIgnWarn_B_Cmd 1;
BA_ "U_V710_MY2023_Rx" SG_ 963 HomeSafeLtChime_B_Rq 1;
BA_ "U_P708_MY2023_Rx" SG_ 963 HomeSafeLtChime_B_Rq 1;
BA_ "U_V713AV_MY2022_Rx" SG_ 963 HomeSafeLtChime_B_Rq 1;
BA_ "U_V713N_MY2022_Rx" SG_ 963 HomeSafeLtChime_B_Rq 1;
BA_ "WakeupSignal" SG_ 963 HomeSafeLtChime_B_Rq 1;
BA_ "U_V710_MY2023_Rx" SG_ 963 StopLghtOn_B_Stat 1;
BA_ "U_P708_MY2023_Rx" SG_ 963 StopLghtOn_B_Stat 1;
BA_ "WakeupSignal" SG_ 963 StopLghtOn_B_Stat 1;
BA_ "U_V710_MY2023_Rx" SG_ 963 RvrseLghtOn_B_Stat 1;
BA_ "U_V710_MY2023_Rx" SG_ 963 PrkLght_D_Stat 1;
BA_ "WakeupSignal" SG_ 963 PrkLght_D_Stat 1;
BA_ "U_V710_MY2023_Rx" SG_ 963 HeadLghtSwtch_D_Stat 1;
BA_ "U_P708_MY2023_Rx" SG_ 963 HeadLghtSwtch_D_Stat 1;
BA_ "U_V713AV_MY2022_Rx" SG_ 963 HeadLghtSwtch_D_Stat 1;
BA_ "U_V713N_MY2022_Rx" SG_ 963 HeadLghtSwtch_D_Stat 1;
BA_ "GenSigStartValue" SG_ 963 HeadLghtSwtch_D_Stat 2;
BA_ "WakeupSignal" SG_ 963 HeadLghtSwtch_D_Stat 1;
BA_ "GenSigStartValue" SG_ 963 HeadLampLoFrOn_B_Stat 1;
BA_ "GenSigStartValue" SG_ 963 HeadLampLoFlOn_B_Stat 1;
BA_ "GenSigStartValue" SG_ 963 HeadLampLoActv_B_Stat 1;
BA_ "U_V710_MY2023_Rx" SG_ 963 Headlamp_On_Wrning_Cmd 1;
BA_ "U_P708_MY2023_Rx" SG_ 963 Headlamp_On_Wrning_Cmd 1;
BA_ "U_V713AV_MY2022_Rx" SG_ 963 Headlamp_On_Wrning_Cmd 1;
BA_ "U_V713N_MY2022_Rx" SG_ 963 Headlamp_On_Wrning_Cmd 1;
BA_ "WakeupSignal" SG_ 963 Headlamp_On_Wrning_Cmd 1;
BA_ "U_V710_MY2023_Rx" SG_ 963 HeadLghtHiOn_B_Stat 1;
BA_ "U_P708_MY2023_Rx" SG_ 963 HeadLghtHiOn_B_Stat 1;
BA_ "U_V713AV_MY2022_Rx" SG_ 963 HeadLghtHiOn_B_Stat 1;
BA_ "U_V713N_MY2022_Rx" SG_ 963 HeadLghtHiOn_B_Stat 1;
BA_ "WakeupSignal" SG_ 963 HeadLghtHiOn_B_Stat 1;
BA_ "U_V710_MY2023_Rx" SG_ 963 Park_Brake_Chime_Rqst 1;
BA_ "U_P708_MY2023_Rx" SG_ 963 Park_Brake_Chime_Rqst 1;
BA_ "U_V713AV_MY2022_Rx" SG_ 963 Park_Brake_Chime_Rqst 1;
BA_ "U_V713N_MY2022_Rx" SG_ 963 Park_Brake_Chime_Rqst 1;
BA_ "U_V710_MY2023_Rx" SG_ 963 BrkWarnInd_B_Rq 1;
BA_ "U_P708_MY2023_Rx" SG_ 963 BrkWarnInd_B_Rq 1;
BA_ "U_V713AV_MY2022_Rx" SG_ 963 BrkWarnInd_B_Rq 1;
BA_ "U_V713N_MY2022_Rx" SG_ 963 BrkWarnInd_B_Rq 1;
BA_ "U_V710_MY2023_Rx" SG_ 963 Brk_Fluid_Lvl_Low 1;
BA_ "U_P708_MY2023_Rx" SG_ 963 Brk_Fluid_Lvl_Low 1;
BA_ "U_V713AV_MY2022_Rx" SG_ 963 Brk_Fluid_Lvl_Low 1;
BA_ "U_V713N_MY2022_Rx" SG_ 963 Brk_Fluid_Lvl_Low 1;
BA_ "U_V710_MY2023_Rx" SG_ 963 ReducedGuard_D_Stat 1;
BA_ "U_P708_MY2023_Rx" SG_ 963 ReducedGuard_D_Stat 1;
BA_ "U_V713AV_MY2022_Rx" SG_ 963 ReducedGuard_D_Stat 1;
BA_ "U_V713N_MY2022_Rx" SG_ 963 ReducedGuard_D_Stat 1;
BA_ "U_P708_MY2023_Rx" SG_ 963 Courtesy_BSave_Stat 1;
BA_ "U_V713AV_MY2022_Rx" SG_ 963 Courtesy_BSave_Stat 1;
BA_ "U_V713N_MY2022_Rx" SG_ 963 Courtesy_BSave_Stat 1;
BA_ "GenSigStartValue" SG_ 963 Courtesy_BSave_Stat 1;
BA_ "WakeupSignal" SG_ 963 Courtesy_BSave_Stat 1;
BA_ "U_V713AV_MY2022_Rx" SG_ 963 DayRnngLampOn_B_Stat 1;
BA_ "U_V713N_MY2022_Rx" SG_ 963 DayRnngLampOn_B_Stat 1;
BA_ "U_V710_MY2023_Rx" SG_ 963 PerimeterAlarmChimeRq 1;
BA_ "U_P708_MY2023_Rx" SG_ 963 PerimeterAlarmChimeRq 1;
BA_ "U_V713AV_MY2022_Rx" SG_ 963 PerimeterAlarmChimeRq 1;
BA_ "U_V713N_MY2022_Rx" SG_ 963 PerimeterAlarmChimeRq 1;
BA_ "WakeupSignal" SG_ 963 PerimeterAlarmChimeRq 1;
BA_ "U_V710_MY2023_Rx" SG_ 963 Perimeter_Alarm_Status 1;
BA_ "U_P708_MY2023_Rx" SG_ 963 Perimeter_Alarm_Status 1;
BA_ "WakeupSignal" SG_ 963 Perimeter_Alarm_Status 1;
BA_ "WakeupSignal" SG_ 963 WndwGlbl_D_Cmd 1;
BA_ "U_V713AV_MY2022_Rx" SG_ 963 DrTgateLck_D_Stat 1;
BA_ "U_V713N_MY2022_Rx" SG_ 963 DrTgateLck_D_Stat 1;
BA_ "U_P708_MY2023_Rx" SG_ 963 PudLamp_D_Rq 1;
BA_ "WakeupSignal" SG_ 963 PudLamp_D_Rq 1;
BA_ "U_V710_MY2023_Rx" SG_ 949 Tire_Press_RR_ORR_Data 1;
BA_ "U_P708_MY2023_Rx" SG_ 949 Tire_Press_RR_ORR_Data 1;
BA_ "U_V713AV_MY2022_Rx" SG_ 949 Tire_Press_RR_ORR_Data 1;
BA_ "U_V713N_MY2022_Rx" SG_ 949 Tire_Press_RR_ORR_Data 1;
BA_ "GenSigStartValue" SG_ 949 Tire_Press_RR_ORR_Data 65533;
BA_ "U_V710_MY2023_Rx" SG_ 949 Tire_Press_LR_OLR_Data 1;
BA_ "U_P708_MY2023_Rx" SG_ 949 Tire_Press_LR_OLR_Data 1;
BA_ "U_V713AV_MY2022_Rx" SG_ 949 Tire_Press_LR_OLR_Data 1;
BA_ "U_V713N_MY2022_Rx" SG_ 949 Tire_Press_LR_OLR_Data 1;
BA_ "GenSigStartValue" SG_ 949 Tire_Press_LR_OLR_Data 65533;
BA_ "U_V710_MY2023_Rx" SG_ 949 Tire_Press_LF_Data 1;
BA_ "U_P708_MY2023_Rx" SG_ 949 Tire_Press_LF_Data 1;
BA_ "U_V713AV_MY2022_Rx" SG_ 949 Tire_Press_LF_Data 1;
BA_ "U_V713N_MY2022_Rx" SG_ 949 Tire_Press_LF_Data 1;
BA_ "GenSigStartValue" SG_ 949 Tire_Press_LF_Data 65533;
BA_ "U_V710_MY2023_Rx" SG_ 949 Tire_Press_RF_Data 1;
BA_ "U_P708_MY2023_Rx" SG_ 949 Tire_Press_RF_Data 1;
BA_ "U_V713AV_MY2022_Rx" SG_ 949 Tire_Press_RF_Data 1;
BA_ "U_V713N_MY2022_Rx" SG_ 949 Tire_Press_RF_Data 1;
BA_ "GenSigStartValue" SG_ 949 Tire_Press_RF_Data 65533;
BA_ "ECGUsedRxSignal" SG_ 2015 TesterFunctionalReq 1;
BA_ "U_V710_MY2023_Rx" SG_ 2015 TesterFunctionalReq 1;
BA_ "U_P708_MY2023_Rx" SG_ 2015 TesterFunctionalReq 1;
BA_ "U_V713AV_MY2022_Rx" SG_ 2015 TesterFunctionalReq 1;
BA_ "U_V713N_MY2022_Rx" SG_ 2015 TesterFunctionalReq 1;
BA_ "GenSigSendType" SG_ 2015 TesterFunctionalReq 3;
BA_ "U_V710_MY2023_Tx" SG_ 1076 AutoRgen_D_Rq 1;
BA_ "U_P708_MY2023_Tx" SG_ 1076 AutoRgen_D_Rq 1;
BA_ "U_V713AV_MY2022_Tx" SG_ 1076 AutoRgen_D_Rq 1;
BA_ "U_V713N_MY2022_Tx" SG_ 1076 AutoRgen_D_Rq 1;
BA_ "GenSigSendType" SG_ 1076 AutoRgen_D_Rq 3;
BA_ "U_V710_MY2023_Tx" SG_ 1076 W2S_LAMP_OK 1;
BA_ "U_P708_MY2023_Tx" SG_ 1076 W2S_LAMP_OK 1;
BA_ "U_V713AV_MY2022_Tx" SG_ 1076 W2S_LAMP_OK 1;
BA_ "U_V713N_MY2022_Tx" SG_ 1076 W2S_LAMP_OK 1;
BA_ "GenSigSendType" SG_ 1076 W2S_LAMP_OK 3;
BA_ "GenSigStartValue" SG_ 1076 W2S_LAMP_OK 1;
BA_ "U_V710_MY2023_Tx" SG_ 1076 OdoTripRx_B_Actl 1;
BA_ "U_P708_MY2023_Tx" SG_ 1076 OdoTripRx_B_Actl 1;
BA_ "U_V713AV_MY2022_Tx" SG_ 1076 OdoTripRx_B_Actl 1;
BA_ "U_V713N_MY2022_Tx" SG_ 1076 OdoTripRx_B_Actl 1;
BA_ "GenSigSendType" SG_ 1076 OdoTripRx_B_Actl 3;
BA_ "U_V710_MY2023_Tx" SG_ 1076 Veh_V_CompLimMx 1;
BA_ "U_P708_MY2023_Tx" SG_ 1076 Veh_V_CompLimMx 1;
BA_ "U_V713AV_MY2022_Tx" SG_ 1076 Veh_V_CompLimMx 1;
BA_ "U_V713N_MY2022_Tx" SG_ 1076 Veh_V_CompLimMx 1;
BA_ "GenSigStartValue" SG_ 1076 Veh_V_CompLimMx 4093;
BA_ "U_V710_MY2023_Tx" SG_ 1076 DrvSlipCtlMde_B_RqMyKey 1;
BA_ "U_P708_MY2023_Tx" SG_ 1076 DrvSlipCtlMde_B_RqMyKey 1;
BA_ "U_V713AV_MY2022_Tx" SG_ 1076 DrvSlipCtlMde_B_RqMyKey 1;
BA_ "U_V713N_MY2022_Tx" SG_ 1076 DrvSlipCtlMde_B_RqMyKey 1;
BA_ "GenSigSendType" SG_ 1076 DrvSlipCtlMde_B_RqMyKey 3;
BA_ "U_V710_MY2023_Tx" SG_ 1076 FuelLvlWarn_D_Actl 1;
BA_ "U_P708_MY2023_Tx" SG_ 1076 FuelLvlWarn_D_Actl 1;
BA_ "U_V713AV_MY2022_Tx" SG_ 1076 FuelLvlWarn_D_Actl 1;
BA_ "U_V713N_MY2022_Tx" SG_ 1076 FuelLvlWarn_D_Actl 1;
BA_ "U_V710_MY2023_Rx" SG_ 1076 FuelLvlWarn_D_Actl 1;
BA_ "U_P708_MY2023_Rx" SG_ 1076 FuelLvlWarn_D_Actl 1;
BA_ "U_V713AV_MY2022_Rx" SG_ 1076 FuelLvlWarn_D_Actl 1;
BA_ "U_V713N_MY2022_Rx" SG_ 1076 FuelLvlWarn_D_Actl 1;
BA_ "ECGUsedRxSignal" SG_ 1076 FuelLvlWarn_D_Actl 1;
BA_ "GenSigSendType" SG_ 1076 FuelLvlWarn_D_Actl 3;
BA_ "GenSigSendType" SG_ 1076 DieslFuelBio_B_ActlDrv 3;
BA_ "U_V710_MY2023_Tx" SG_ 1076 FuelSecndActv_B_Actl 1;
BA_ "U_P708_MY2023_Tx" SG_ 1076 FuelSecndActv_B_Actl 1;
BA_ "U_V713AV_MY2022_Tx" SG_ 1076 FuelSecndActv_B_Actl 1;
BA_ "U_V713N_MY2022_Tx" SG_ 1076 FuelSecndActv_B_Actl 1;
BA_ "GenSigSendType" SG_ 1076 FuelSecndActv_B_Actl 3;
BA_ "U_P708_MY2023_Tx" SG_ 1076 HILL_DESC_SW 1;
BA_ "U_V713AV_MY2022_Tx" SG_ 1076 HILL_DESC_SW 1;
BA_ "U_V713N_MY2022_Tx" SG_ 1076 HILL_DESC_SW 1;
BA_ "GenSigSendType" SG_ 1076 HILL_DESC_SW 3;
BA_ "U_V710_MY2023_Tx" SG_ 1076 FuelLvlPssvSide_No_Raw 1;
BA_ "U_P708_MY2023_Tx" SG_ 1076 FuelLvlPssvSide_No_Raw 1;
BA_ "U_V713AV_MY2022_Tx" SG_ 1076 FuelLvlPssvSide_No_Raw 1;
BA_ "U_V713N_MY2022_Tx" SG_ 1076 FuelLvlPssvSide_No_Raw 1;
BA_ "U_V710_MY2023_Tx" SG_ 1076 FUEL_SENSOR_NUM 1;
BA_ "U_P708_MY2023_Tx" SG_ 1076 FUEL_SENSOR_NUM 1;
BA_ "U_V713AV_MY2022_Tx" SG_ 1076 FUEL_SENSOR_NUM 1;
BA_ "U_V713N_MY2022_Tx" SG_ 1076 FUEL_SENSOR_NUM 1;
BA_ "GenSigSendType" SG_ 1076 FUEL_SENSOR_NUM 3;
BA_ "U_V710_MY2023_Tx" SG_ 1076 FuelLvlActvSide_No_Raw 1;
BA_ "U_P708_MY2023_Tx" SG_ 1076 FuelLvlActvSide_No_Raw 1;
BA_ "U_V713AV_MY2022_Tx" SG_ 1076 FuelLvlActvSide_No_Raw 1;
BA_ "U_V713N_MY2022_Tx" SG_ 1076 FuelLvlActvSide_No_Raw 1;
BA_ "U_V710_MY2023_Tx" SG_ 1076 FuelLvl_Pc_Dsply 1;
BA_ "U_P708_MY2023_Tx" SG_ 1076 FuelLvl_Pc_Dsply 1;
BA_ "U_V713AV_MY2022_Tx" SG_ 1076 FuelLvl_Pc_Dsply 1;
BA_ "U_V713N_MY2022_Tx" SG_ 1076 FuelLvl_Pc_Dsply 1;
BA_ "U_V710_MY2023_Rx" SG_ 1076 FuelLvl_Pc_Dsply 1;
BA_ "U_P708_MY2023_Rx" SG_ 1076 FuelLvl_Pc_Dsply 1;
BA_ "U_V713AV_MY2022_Rx" SG_ 1076 FuelLvl_Pc_Dsply 1;
BA_ "U_V713N_MY2022_Rx" SG_ 1076 FuelLvl_Pc_Dsply 1;
BA_ "ECGUsedRxSignal" SG_ 1076 FuelLvl_Pc_Dsply 1;
BA_ "U_V710_MY2023_Tx" SG_ 1076 DISPLAY_SPEED_SCALING 1;
BA_ "U_P708_MY2023_Tx" SG_ 1076 DISPLAY_SPEED_SCALING 1;
BA_ "U_V713AV_MY2022_Tx" SG_ 1076 DISPLAY_SPEED_SCALING 1;
BA_ "U_V713N_MY2022_Tx" SG_ 1076 DISPLAY_SPEED_SCALING 1;
BA_ "U_V710_MY2023_Tx" SG_ 1076 TirePReset_B_Rq 1;
BA_ "U_P708_MY2023_Tx" SG_ 1076 TirePReset_B_Rq 1;
BA_ "U_V713AV_MY2022_Tx" SG_ 1076 TirePReset_B_Rq 1;
BA_ "U_V713N_MY2022_Tx" SG_ 1076 TirePReset_B_Rq 1;
BA_ "GenSigSendType" SG_ 1076 TirePReset_B_Rq 3;
BA_ "U_V710_MY2023_Tx" SG_ 1076 DISPLAY_SPEED_OFFSET 1;
BA_ "U_P708_MY2023_Tx" SG_ 1076 DISPLAY_SPEED_OFFSET 1;
BA_ "U_V713AV_MY2022_Tx" SG_ 1076 DISPLAY_SPEED_OFFSET 1;
BA_ "U_V713N_MY2022_Tx" SG_ 1076 DISPLAY_SPEED_OFFSET 1;
BA_ "GenSigStartValue" SG_ 974 DcacElPw_D_Stat 1;
BA_ "U_V710_MY2023_Tx" SG_ 810 OneTEditActv_B_RqCld 1;
BA_ "U_V713AV_MY2022_Tx" SG_ 810 OneTEditActv_B_RqCld 1;
BA_ "U_V713N_MY2022_Tx" SG_ 810 OneTEditActv_B_RqCld 1;
BA_ "ECGUsedTxSignal" SG_ 810 OneTEditActv_B_RqCld 1;
BA_ "GenSigSendType" SG_ 810 OneTEditActv_B_RqCld 3;
BA_ "U_V710_MY2023_Tx" SG_ 810 ExtLghtDsply_B_StatArb 1;
BA_ "U_P708_MY2023_Tx" SG_ 810 ExtLghtDsply_B_StatArb 1;
BA_ "U_V713AV_MY2022_Tx" SG_ 810 ExtLghtDsply_B_StatArb 1;
BA_ "U_V713N_MY2022_Tx" SG_ 810 ExtLghtDsply_B_StatArb 1;
BA_ "ECGUsedTxSignal" SG_ 810 ExtLghtDsply_B_StatArb 1;
BA_ "GenSigSendType" SG_ 810 ExtLghtDsply_B_StatArb 3;
BA_ "WakeupSignal" SG_ 810 ExtLghtDsply_B_StatArb 1;
BA_ "U_V710_MY2023_Tx" SG_ 1492 TRM_GWOnBoardTester 1;
BA_ "U_P708_MY2023_Tx" SG_ 1492 TRM_GWOnBoardTester 1;
BA_ "GenSigStartValue" SG_ 1492 TRM_GWOnBoardTester 255;
BA_ "U_V710_MY2023_Tx" SG_ 1492 TRM_GWNMProxy 1;
BA_ "U_P708_MY2023_Tx" SG_ 1492 TRM_GWNMProxy 1;
BA_ "GenSigStartValue" SG_ 1492 TRM_GWNMProxy 255;
BA_ "U_V710_MY2023_Tx" SG_ 1492 TRM_AutoSarNMReserved4 1;
BA_ "U_P708_MY2023_Tx" SG_ 1492 TRM_AutoSarNMReserved4 1;
BA_ "GenSigStartValue" SG_ 1492 TRM_AutoSarNMReserved4 255;
BA_ "U_V710_MY2023_Tx" SG_ 1492 TRM_AutoSarNMReserved3 1;
BA_ "U_P708_MY2023_Tx" SG_ 1492 TRM_AutoSarNMReserved3 1;
BA_ "GenSigStartValue" SG_ 1492 TRM_AutoSarNMReserved3 255;
BA_ "U_V710_MY2023_Tx" SG_ 1492 TRM_AutoSarNMReserved2 1;
BA_ "U_P708_MY2023_Tx" SG_ 1492 TRM_AutoSarNMReserved2 1;
BA_ "GenSigStartValue" SG_ 1492 TRM_AutoSarNMReserved2 255;
BA_ "U_V710_MY2023_Tx" SG_ 1492 TRM_AutoSarNMReserved1 1;
BA_ "U_P708_MY2023_Tx" SG_ 1492 TRM_AutoSarNMReserved1 1;
BA_ "GenSigStartValue" SG_ 1492 TRM_AutoSarNMReserved1 255;
BA_ "U_V710_MY2023_Tx" SG_ 1492 TRM_AutoSarNMNodeId 1;
BA_ "U_P708_MY2023_Tx" SG_ 1492 TRM_AutoSarNMNodeId 1;
BA_ "GenSigStartValue" SG_ 1492 TRM_AutoSarNMNodeId 212;
BA_ "U_V710_MY2023_Tx" SG_ 1492 TRM_AutoSarNMControl 1;
BA_ "U_P708_MY2023_Tx" SG_ 1492 TRM_AutoSarNMControl 1;
BA_ "GenSigSendType" SG_ 552 ActvNseMute_D_Stat 3;
BA_ "GenSigSendType" SG_ 552 DSP_Treble_St 3;
BA_ "U_P708_MY2023_Rx" SG_ 552 DSP_VoiceFBVolume_Up 1;
BA_ "GenSigSendType" SG_ 552 DSP_VoiceFBVolume_Up 1;
BA_ "U_P708_MY2023_Rx" SG_ 552 DSP_VoiceFBVolume_St 1;
BA_ "U_V713N_MY2022_Rx" SG_ 552 DSP_VoiceFBVolume_St 1;
BA_ "U_P708_MY2023_Rx" SG_ 552 DSP_TAVolume_Up 1;
BA_ "GenSigSendType" SG_ 552 DSP_TAVolume_Up 1;
BA_ "U_P708_MY2023_Rx" SG_ 552 DSP_TAVolume_St 1;
BA_ "U_V713N_MY2022_Rx" SG_ 552 DSP_TAVolume_St 1;
BA_ "GenSigSendType" SG_ 552 DSP_Shaker_St 3;
BA_ "GenSigSendType" SG_ 552 DSP_Reg_St 3;
BA_ "U_P708_MY2023_Rx" SG_ 552 DSP_PhoneVolume_Up 1;
BA_ "GenSigSendType" SG_ 552 DSP_PhoneVolume_Up 1;
BA_ "U_P708_MY2023_Rx" SG_ 552 DSP_PhoneVolume_St 1;
BA_ "U_V713N_MY2022_Rx" SG_ 552 DSP_PhoneVolume_St 1;
BA_ "U_P708_MY2023_Rx" SG_ 552 DSP_NavCmdVolume_Up 1;
BA_ "GenSigSendType" SG_ 552 DSP_NavCmdVolume_Up 1;
BA_ "U_P708_MY2023_Rx" SG_ 552 DSP_NavCmdVolume_St 1;
BA_ "U_V713N_MY2022_Rx" SG_ 552 DSP_NavCmdVolume_St 1;
BA_ "GenSigSendType" SG_ 552 DSP_Midrange_St 3;
BA_ "GenSigSendType" SG_ 552 DSP_Fader_St 3;
BA_ "GenSigSendType" SG_ 552 DSP_DSPProgram_St 3;
BA_ "GenSigSendType" SG_ 552 DSP_DSP_St 3;
BA_ "GenSigSendType" SG_ 552 DSP_Bass_St 3;
BA_ "GenSigSendType" SG_ 552 DSP_Balance_St 3;
BA_ "GenSigSendType" SG_ 552 DSP_AVC_St 3;
BA_ "GenSigSendType" SG_ 552 Audio_Demo_Status 3;
BA_ "GenSigStartValue" SG_ 967 CamraViewSplit_D_Actl 2;
BA_ "U_P708_MY2023_Rx" SG_ 1105 TrlrRvrseEnbl_D2_Stat 1;
BA_ "U_V713AV_MY2022_Rx" SG_ 1105 TrlrRvrseEnbl_D2_Stat 1;
BA_ "U_V713N_MY2022_Rx" SG_ 1105 TrlrRvrseEnbl_D2_Stat 1;
BA_ "U_P708_MY2023_Rx" SG_ 1105 TrlrAidSwtchLamp_B_Rq 1;
BA_ "U_V710_MY2023_Rx" SG_ 1105 TrlrHitchChime_D_Rq 1;
BA_ "U_P708_MY2023_Rx" SG_ 1105 TrlrHitchChime_D_Rq 1;
BA_ "U_V713AV_MY2022_Rx" SG_ 1105 TrlrHitchChime_D_Rq 1;
BA_ "U_V713N_MY2022_Rx" SG_ 1105 TrlrHitchChime_D_Rq 1;
BA_ "U_V710_MY2023_Rx" SG_ 1105 TrlrRvrseMsgTxt_D2_Rq 1;
BA_ "U_P708_MY2023_Rx" SG_ 1105 TrlrRvrseMsgTxt_D2_Rq 1;
BA_ "U_V713AV_MY2022_Rx" SG_ 1105 TrlrRvrseMsgTxt_D2_Rq 1;
BA_ "U_V713N_MY2022_Rx" SG_ 1105 TrlrRvrseMsgTxt_D2_Rq 1;
BA_ "U_V710_MY2023_Rx" SG_ 1105 RbaMsg_D_Rq 1;
BA_ "U_P708_MY2023_Rx" SG_ 1105 RbaMsg_D_Rq 1;
BA_ "U_V713AV_MY2022_Rx" SG_ 1105 RbaMsg_D_Rq 1;
BA_ "U_V713N_MY2022_Rx" SG_ 1105 RbaMsg_D_Rq 1;
BA_ "WakeupSignal" SG_ 1105 BrkDecel_B_RqRba 1;
BA_ "WakeupSignal" SG_ 1105 BrkEnbl_B_RqRba 1;
BA_ "U_P708_MY2023_Rx" SG_ 1105 Rba_D_Stat 1;
BA_ "U_V713AV_MY2022_Rx" SG_ 1105 Rba_D_Stat 1;
BA_ "U_V713N_MY2022_Rx" SG_ 1105 Rba_D_Stat 1;
BA_ "GenSigStartValue" SG_ 1105 Rba_D_Stat 1;
BA_ "U_V710_MY2023_Rx" SG_ 1105 RbaAlrt_D_Dsply 1;
BA_ "U_P708_MY2023_Rx" SG_ 1105 RbaAlrt_D_Dsply 1;
BA_ "U_V713AV_MY2022_Rx" SG_ 1105 RbaAlrt_D_Dsply 1;
BA_ "U_V713N_MY2022_Rx" SG_ 1105 RbaAlrt_D_Dsply 1;
BA_ "U_P708_MY2023_Rx" SG_ 1105 CamraFrntStat_D_Stat 1;
BA_ "U_V713AV_MY2022_Rx" SG_ 1105 CamraFrntStat_D_Stat 1;
BA_ "U_V713N_MY2022_Rx" SG_ 1105 CamraFrntStat_D_Stat 1;
BA_ "U_P708_MY2023_Rx" SG_ 867 LHS_Temp_Disp_Digit3 1;
BA_ "GenSigSendType" SG_ 867 LHS_Temp_Disp_Digit3 1;
BA_ "U_P708_MY2023_Rx" SG_ 867 LHS_Temp_Disp_Digit2 1;
BA_ "GenSigSendType" SG_ 867 LHS_Temp_Disp_Digit2 1;
BA_ "U_P708_MY2023_Rx" SG_ 867 LHS_Temp_Disp_Digit1 1;
BA_ "GenSigSendType" SG_ 867 LHS_Temp_Disp_Digit1 1;
BA_ "U_V713AV_MY2022_Tx" SG_ 867 Front_Blower_Ind 1;
BA_ "U_V713N_MY2022_Tx" SG_ 867 Front_Blower_Ind 1;
BA_ "GenSigSendType" SG_ 867 Front_Blower_Ind 1;
BA_ "GenSigStartValue" SG_ 867 Front_Blower_Ind 15;
BA_ "U_P708_MY2023_Rx" SG_ 867 EATC_LHS_Unit 1;
BA_ "GenSigSendType" SG_ 867 EATC_LHS_Unit 1;
BA_ "GenSigSendType" SG_ 866 SnowPlowOn_B_Rq 3;
BA_ "GenSigSendType" SG_ 866 Frt_Blower_Speed2 3;
BA_ "GenSigSendType" SG_ 866 Psngr_Set_Temp 3;
BA_ "GenSigSendType" SG_ 866 ClimtRearView_D_Stat 3;
BA_ "GenSigSendType" SG_ 866 Voice_Blower_Limit 3;
BA_ "GenSigSendType" SG_ 866 Rr_Btn_Status_2nd 3;
BA_ "GenSigSendType" SG_ 866 Rr_Btn_Status_1st 3;
BA_ "GenSigSendType" SG_ 866 Frt_Btn_Status_2nd 3;
BA_ "GenSigSendType" SG_ 866 Frt_Btn_Status_1st 3;
BA_ "GenSigSendType" SG_ 866 Frt_Blower_Speed 3;
BA_ "GenSigSendType" SG_ 866 Drv_Set_Temp 3;
BA_ "GenSigStartValue" SG_ 861 Rr_Power_Btn_Stt 2;
BA_ "GenSigStartValue" SG_ 861 Rr_Pnl_Flr_Btn_Stt 2;
BA_ "GenSigStartValue" SG_ 861 Rr_Set_Temp_Units 2;
BA_ "GenSigStartValue" SG_ 861 Rr_RHS_Set_Temp_Dig3 2;
BA_ "GenSigStartValue" SG_ 861 Rr_RHS_Set_Temp_Dig2 15;
BA_ "GenSigStartValue" SG_ 861 Rr_RHS_Set_Temp_Dig1 15;
BA_ "GenSigStartValue" SG_ 861 Rr_RH_Htd_Seat_Btn_Stt 2;
BA_ "GenSigStartValue" SG_ 861 Rr_RH_Cld_Seat_Btn_Stt 2;
BA_ "GenSigStartValue" SG_ 861 Rr_Panel_Btn_Stt 2;
BA_ "GenSigStartValue" SG_ 861 Rr_LHS_Set_Temp_Dig2 15;
BA_ "GenSigStartValue" SG_ 861 Rr_LHS_Set_Temp_Dig1 15;
BA_ "GenSigStartValue" SG_ 861 Rr_LH_Htd_Seat_Btn_Stt 2;
BA_ "GenSigStartValue" SG_ 861 Rr_LH_Cld_Seat_Btn_Stt 2;
BA_ "GenSigStartValue" SG_ 861 Rr_Floor_Btn_Stt 2;
BA_ "GenSigStartValue" SG_ 861 Rr_Control_Btn_Stt 2;
BA_ "GenSigStartValue" SG_ 861 Rr_Blower_Indicate 15;
BA_ "GenSigStartValue" SG_ 861 Rr_AUTO_Btn_Stt 2;
BA_ "GenSigStartValue" SG_ 865 Dsp_RotAddrBtnEv_St 7;
BA_ "U_V713AV_MY2022_Rx" SG_ 865 SteEffortButtn_B_Stat 1;
BA_ "U_V713N_MY2022_Rx" SG_ 865 SteEffortButtn_B_Stat 1;
BA_ "U_V713AV_MY2022_Rx" SG_ 865 EngExhMdeQuiet_B_RqDrv 1;
BA_ "U_V713N_MY2022_Rx" SG_ 865 EngExhMdeQuiet_B_RqDrv 1;
BA_ "U_V713AV_MY2022_Rx" SG_ 865 LnchCtlSys_B_RqDrv 1;
BA_ "U_V713N_MY2022_Rx" SG_ 865 LnchCtlSys_B_RqDrv 1;
BA_ "U_P708_MY2023_Rx" SG_ 865 CC_Fr_Stat_User_Adj 1;
BA_ "GenSigStartValue" SG_ 865 RHS_Auto_Seat_Btn_Stt 2;
BA_ "U_P708_MY2023_Rx" SG_ 865 Front_Blower_Indicate 1;
BA_ "U_V713AV_MY2022_Rx" SG_ 865 Front_Blower_Indicate 1;
BA_ "U_V713N_MY2022_Rx" SG_ 865 Front_Blower_Indicate 1;
BA_ "GenSigStartValue" SG_ 865 Front_Blower_Indicate 15;
BA_ "U_V713AV_MY2022_Rx" SG_ 865 CC_Diagnostics_Active 1;
BA_ "U_V713N_MY2022_Rx" SG_ 865 CC_Diagnostics_Active 1;
BA_ "U_V713AV_MY2022_Rx" SG_ 865 RHS_Temp_Display_Digit3 1;
BA_ "U_V713N_MY2022_Rx" SG_ 865 RHS_Temp_Display_Digit3 1;
BA_ "U_V713AV_MY2022_Rx" SG_ 865 RHS_Temp_Display_Digit2 1;
BA_ "U_V713N_MY2022_Rx" SG_ 865 RHS_Temp_Display_Digit2 1;
BA_ "U_V713AV_MY2022_Rx" SG_ 865 RHS_Temp_Display_Digit1 1;
BA_ "U_V713N_MY2022_Rx" SG_ 865 RHS_Temp_Display_Digit1 1;
BA_ "U_V713AV_MY2022_Rx" SG_ 865 LHS_Temp_Display_Digit3 1;
BA_ "U_V713N_MY2022_Rx" SG_ 865 LHS_Temp_Display_Digit3 1;
BA_ "U_V713AV_MY2022_Rx" SG_ 865 LHS_Temp_Display_Digit2 1;
BA_ "U_V713N_MY2022_Rx" SG_ 865 LHS_Temp_Display_Digit2 1;
BA_ "U_V713AV_MY2022_Rx" SG_ 865 LHS_Temp_Display_Digit1 1;
BA_ "U_V713N_MY2022_Rx" SG_ 865 LHS_Temp_Display_Digit1 1;
BA_ "U_V713AV_MY2022_Rx" SG_ 865 EATC_RHS_Units 1;
BA_ "U_V713N_MY2022_Rx" SG_ 865 EATC_RHS_Units 1;
BA_ "U_V713AV_MY2022_Rx" SG_ 865 EATC_LHS_Units 1;
BA_ "U_V713N_MY2022_Rx" SG_ 865 EATC_LHS_Units 1;
BA_ "GenSigStartValue" SG_ 865 LHS_Auto_Seat_Btn_Stt 2;
BA_ "U_V713AV_MY2022_Rx" SG_ 1046 PrkBrkDynmc_D_Allw 1;
BA_ "U_V713N_MY2022_Rx" SG_ 1046 PrkBrkDynmc_D_Allw 1;
BA_ "U_V713AV_MY2022_Rx" SG_ 1046 BrkPrkBrkDynmc_B_Actl 1;
BA_ "U_V713N_MY2022_Rx" SG_ 1046 BrkPrkBrkDynmc_B_Actl 1;
BA_ "U_P708_MY2023_Rx" SG_ 1046 TRLR_SWAY_EVNT_IN_PROG 1;
BA_ "U_V713AV_MY2022_Rx" SG_ 1046 TRLR_SWAY_EVNT_IN_PROG 1;
BA_ "U_V713N_MY2022_Rx" SG_ 1046 TRLR_SWAY_EVNT_IN_PROG 1;
BA_ "U_V710_MY2023_Rx" SG_ 1046 TRLR_SWAY_CONFIG_STAT 1;
BA_ "U_P708_MY2023_Rx" SG_ 1046 TRLR_SWAY_CONFIG_STAT 1;
BA_ "U_V713AV_MY2022_Rx" SG_ 1046 TRLR_SWAY_CONFIG_STAT 1;
BA_ "U_V713N_MY2022_Rx" SG_ 1046 TRLR_SWAY_CONFIG_STAT 1;
BA_ "U_V710_MY2023_Rx" SG_ 1046 HsaMde_D_Mem 1;
BA_ "U_P708_MY2023_Rx" SG_ 1046 HsaMde_D_Mem 1;
BA_ "U_V713AV_MY2022_Rx" SG_ 1046 HsaMde_D_Mem 1;
BA_ "U_V713N_MY2022_Rx" SG_ 1046 HsaMde_D_Mem 1;
BA_ "GenSigStartValue" SG_ 1046 HsaMde_D_Mem 1;
BA_ "MetaData" SG_ 1046 BpedDiffLckTq_No_Cs 1;
BA_ "U_V710_MY2023_Rx" SG_ 1046 DrvSlipCtlMde_D_Ind 1;
BA_ "U_P708_MY2023_Rx" SG_ 1046 DrvSlipCtlMde_D_Ind 1;
BA_ "U_V713AV_MY2022_Rx" SG_ 1046 DrvSlipCtlMde_D_Ind 1;
BA_ "U_V713N_MY2022_Rx" SG_ 1046 DrvSlipCtlMde_D_Ind 1;
BA_ "U_V710_MY2023_Rx" SG_ 1046 DrvSlipCtlLamp_D_Rq 1;
BA_ "U_P708_MY2023_Rx" SG_ 1046 DrvSlipCtlLamp_D_Rq 1;
BA_ "U_V713AV_MY2022_Rx" SG_ 1046 DrvSlipCtlLamp_D_Rq 1;
BA_ "U_V713N_MY2022_Rx" SG_ 1046 DrvSlipCtlLamp_D_Rq 1;
BA_ "U_V713AV_MY2022_Rx" SG_ 1046 TCMode 1;
BA_ "U_V713N_MY2022_Rx" SG_ 1046 TCMode 1;
BA_ "U_P708_MY2023_Rx" SG_ 1046 HILL_DESC_MC 1;
BA_ "U_V713AV_MY2022_Rx" SG_ 1046 HILL_DESC_MC 1;
BA_ "U_V713N_MY2022_Rx" SG_ 1046 HILL_DESC_MC 1;
BA_ "U_V710_MY2023_Rx" SG_ 1046 DrvAntiLckLamp_D_Rq 1;
BA_ "U_P708_MY2023_Rx" SG_ 1046 DrvAntiLckLamp_D_Rq 1;
BA_ "U_V713AV_MY2022_Rx" SG_ 1046 DrvAntiLckLamp_D_Rq 1;
BA_ "U_V713N_MY2022_Rx" SG_ 1046 DrvAntiLckLamp_D_Rq 1;
BA_ "U_V710_MY2023_Rx" SG_ 1046 ChimeBrk_B_Rq 1;
BA_ "U_P708_MY2023_Rx" SG_ 1046 ChimeBrk_B_Rq 1;
BA_ "U_V713AV_MY2022_Rx" SG_ 1046 ChimeBrk_B_Rq 1;
BA_ "U_V713N_MY2022_Rx" SG_ 1046 ChimeBrk_B_Rq 1;
BA_ "U_V710_MY2023_Rx" SG_ 1046 BrkLamp_B_Rq 1;
BA_ "U_P708_MY2023_Rx" SG_ 1046 BrkLamp_B_Rq 1;
BA_ "U_V713AV_MY2022_Rx" SG_ 1046 BrkLamp_B_Rq 1;
BA_ "U_V713N_MY2022_Rx" SG_ 1046 BrkLamp_B_Rq 1;
BA_ "U_P708_MY2023_Rx" SG_ 1046 Abs_B_Falt 1;
BA_ "U_V713AV_MY2022_Rx" SG_ 1046 Abs_B_Falt 1;
BA_ "U_V713N_MY2022_Rx" SG_ 1046 Abs_B_Falt 1;
BA_ "U_V713AV_MY2022_Rx" SG_ 1046 StabCtlBrk_B_Avail 1;
BA_ "U_V713N_MY2022_Rx" SG_ 1046 StabCtlBrk_B_Avail 1;
BA_ "GenSigStartValue" SG_ 1046 StabCtlBrk_B_Avail 1;
BA_ "U_V713AV_MY2022_Rx" SG_ 1046 DrvHdcWarnInfo_D_Rq 1;
BA_ "U_V713N_MY2022_Rx" SG_ 1046 DrvHdcWarnInfo_D_Rq 1;
BA_ "U_V713AV_MY2022_Rx" SG_ 1046 DrvHdcMsg_D_Rq 1;
BA_ "U_V713N_MY2022_Rx" SG_ 1046 DrvHdcMsg_D_Rq 1;
BA_ "U_P708_MY2023_Rx" SG_ 1046 DrvHdcLampInfo_D_Rq 1;
BA_ "U_V713AV_MY2022_Rx" SG_ 1046 DrvHdcLampInfo_D_Rq 1;
BA_ "U_V713N_MY2022_Rx" SG_ 1046 DrvHdcLampInfo_D_Rq 1;
BA_ "MetaData" SG_ 1046 BpedMove_No_Cnt 1;
BA_ "GenSigStartValue" SG_ 1046 BpedMove_D_Actl 3;
BA_ "GenSigStartValue" SG_ 1046 RearDiffLck_Tq2_RqMx 4094;
BA_ "MetaData" SG_ 534 WhlRotatRr_No_Cnt 1;
BA_ "MetaData" SG_ 534 WhlRotatRl_No_Cnt 1;
BA_ "MetaData" SG_ 534 WhlRotatFr_No_Cnt 1;
BA_ "MetaData" SG_ 534 WhlRotatFl_No_Cnt 1;
BA_ "GenSigSendType" SG_ 402 CamraFrntBttn_D_Stat3 3;
BA_ "GenSigSendType" SG_ 402 PrkAidSwtch_D_RqMnu 3;
BA_ "GenSigSendType" SG_ 402 ApaSwtch_D_RqMnu 3;
BA_ "GenSigSendType" SG_ 402 ApaSlotAlrtSet_D_RqDrv 3;
BA_ "GenSigSendType" SG_ 402 ApaSlotTrgt_D_RqDrv 3;
BA_ "GenSigSendType" SG_ 402 ApaMdeStat_D_RqDrv 3;
BA_ "GenSigSendType" SG_ 402 ApaFeat_D_RqDrv 3;
BA_ "GenSigSendType" SG_ 402 ApaFeatChange_B_RqDrv 3;
BA_ "GenSigSendType" SG_ 402 CamraViewSplit_B_Rq 3;
BA_ "GenSigSendType" SG_ 402 CamraZoomMan_D_Rq 3;
BA_ "U_V713AV_MY2022_Rx" SG_ 402 CamraOvrlStat_D_Rq 1;
BA_ "U_V713N_MY2022_Rx" SG_ 402 CamraOvrlStat_D_Rq 1;
BA_ "GenSigSendType" SG_ 402 CamraOvrlStat_D_Rq 3;
BA_ "U_V713AV_MY2022_Rx" SG_ 402 CamraOvrlDyn_D_Rq 1;
BA_ "U_V713N_MY2022_Rx" SG_ 402 CamraOvrlDyn_D_Rq 1;
BA_ "GenSigSendType" SG_ 402 CamraOvrlDyn_D_Rq 3;
BA_ "U_V713AV_MY2022_Rx" SG_ 402 CamAutoTowbarZoom 1;
BA_ "U_V713N_MY2022_Rx" SG_ 402 CamAutoTowbarZoom 1;
BA_ "GenSigSendType" SG_ 402 CamAutoTowbarZoom 3;
BA_ "GenSigSendType" SG_ 402 DistanceBarSetting 3;
BA_ "U_V710_MY2023_Rx" SG_ 946 DimmingLvlEvnt_No_Actl 1;
BA_ "U_P708_MY2023_Rx" SG_ 946 DimmingLvlEvnt_No_Actl 1;
BA_ "U_V713AV_MY2022_Rx" SG_ 946 DimmingLvlEvnt_No_Actl 1;
BA_ "U_V713N_MY2022_Rx" SG_ 946 DimmingLvlEvnt_No_Actl 1;
BA_ "WakeupSignal" SG_ 946 DimmingLvlEvnt_No_Actl 1;
BA_ "WakeupSignal" SG_ 946 Backlit_LED_Status 1;
BA_ "U_V710_MY2023_Rx" SG_ 946 TurnLghtRightOn_B_Stat 1;
BA_ "U_P708_MY2023_Rx" SG_ 946 TurnLghtRightOn_B_Stat 1;
BA_ "U_V713AV_MY2022_Rx" SG_ 946 TurnLghtRightOn_B_Stat 1;
BA_ "U_V713N_MY2022_Rx" SG_ 946 TurnLghtRightOn_B_Stat 1;
BA_ "U_V710_MY2023_Rx" SG_ 946 TurnLghtLeftOn_B_Stat 1;
BA_ "U_P708_MY2023_Rx" SG_ 946 TurnLghtLeftOn_B_Stat 1;
BA_ "U_V713AV_MY2022_Rx" SG_ 946 TurnLghtLeftOn_B_Stat 1;
BA_ "U_V713N_MY2022_Rx" SG_ 946 TurnLghtLeftOn_B_Stat 1;
BA_ "U_V710_MY2023_Rx" SG_ 946 FogLghtRearOn_B_Stat 1;
BA_ "U_P708_MY2023_Rx" SG_ 946 FogLghtRearOn_B_Stat 1;
BA_ "U_V713AV_MY2022_Rx" SG_ 946 FogLghtRearOn_B_Stat 1;
BA_ "U_V713N_MY2022_Rx" SG_ 946 FogLghtRearOn_B_Stat 1;
BA_ "U_V710_MY2023_Rx" SG_ 946 TurnLghtRight_D_Rq 1;
BA_ "U_P708_MY2023_Rx" SG_ 946 TurnLghtRight_D_Rq 1;
BA_ "WakeupSignal" SG_ 946 TurnLghtRight_D_Rq 1;
BA_ "U_V710_MY2023_Rx" SG_ 946 IgnKeyType_D_Actl 1;
BA_ "U_P708_MY2023_Rx" SG_ 946 IgnKeyType_D_Actl 1;
BA_ "U_V713AV_MY2022_Rx" SG_ 946 IgnKeyType_D_Actl 1;
BA_ "U_V713N_MY2022_Rx" SG_ 946 IgnKeyType_D_Actl 1;
BA_ "GenSigStartValue" SG_ 946 IgnKeyType_D_Actl 14;
BA_ "U_V710_MY2023_Rx" SG_ 946 Parklamp_Status 1;
BA_ "U_P708_MY2023_Rx" SG_ 946 Parklamp_Status 1;
BA_ "U_V713AV_MY2022_Rx" SG_ 946 Parklamp_Status 1;
BA_ "U_V713N_MY2022_Rx" SG_ 946 Parklamp_Status 1;
BA_ "GenSigStartValue" SG_ 946 Parklamp_Status 1;
BA_ "WakeupSignal" SG_ 946 Parklamp_Status 1;
BA_ "U_V710_MY2023_Rx" SG_ 946 Litval 1;
BA_ "U_P708_MY2023_Rx" SG_ 946 Litval 1;
BA_ "U_V713AV_MY2022_Rx" SG_ 946 Litval 1;
BA_ "U_V713N_MY2022_Rx" SG_ 946 Litval 1;
BA_ "WakeupSignal" SG_ 946 Litval 1;
BA_ "U_V710_MY2023_Rx" SG_ 946 Key_In_Ignition_Stat 1;
BA_ "U_P708_MY2023_Rx" SG_ 946 Key_In_Ignition_Stat 1;
BA_ "U_V713AV_MY2022_Rx" SG_ 946 Key_In_Ignition_Stat 1;
BA_ "U_V713N_MY2022_Rx" SG_ 946 Key_In_Ignition_Stat 1;
BA_ "WakeupSignal" SG_ 946 Key_In_Ignition_Stat 1;
BA_ "U_V710_MY2023_Rx" SG_ 946 Ignition_Status 1;
BA_ "U_P708_MY2023_Rx" SG_ 946 Ignition_Status 1;
BA_ "U_V713AV_MY2022_Rx" SG_ 946 Ignition_Status 1;
BA_ "U_V713N_MY2022_Rx" SG_ 946 Ignition_Status 1;
BA_ "WakeupSignal" SG_ 946 Ignition_Status 1;
BA_ "U_V710_MY2023_Rx" SG_ 946 Dimming_Lvl 1;
BA_ "U_P708_MY2023_Rx" SG_ 946 Dimming_Lvl 1;
BA_ "U_V713AV_MY2022_Rx" SG_ 946 Dimming_Lvl 1;
BA_ "U_V713N_MY2022_Rx" SG_ 946 Dimming_Lvl 1;
BA_ "GenSigStartValue" SG_ 946 Dimming_Lvl 12;
BA_ "WakeupSignal" SG_ 946 Dimming_Lvl 1;
BA_ "U_V710_MY2023_Rx" SG_ 946 Day_Night_Status 1;
BA_ "U_P708_MY2023_Rx" SG_ 946 Day_Night_Status 1;
BA_ "U_V713AV_MY2022_Rx" SG_ 946 Day_Night_Status 1;
BA_ "U_V713N_MY2022_Rx" SG_ 946 Day_Night_Status 1;
BA_ "WakeupSignal" SG_ 946 Day_Night_Status 1;
BA_ "U_V710_MY2023_Rx" SG_ 946 Remote_Start_Status 1;
BA_ "U_P708_MY2023_Rx" SG_ 946 Remote_Start_Status 1;
BA_ "U_V713AV_MY2022_Rx" SG_ 946 Remote_Start_Status 1;
BA_ "U_V713N_MY2022_Rx" SG_ 946 Remote_Start_Status 1;
BA_ "WakeupSignal" SG_ 946 Remote_Start_Status 1;
BA_ "U_V710_MY2023_Rx" SG_ 946 DrStatTgate_B_Actl 1;
BA_ "U_P708_MY2023_Rx" SG_ 946 DrStatTgate_B_Actl 1;
BA_ "U_V713AV_MY2022_Rx" SG_ 946 DrStatTgate_B_Actl 1;
BA_ "U_V713N_MY2022_Rx" SG_ 946 DrStatTgate_B_Actl 1;
BA_ "WakeupSignal" SG_ 946 DrStatTgate_B_Actl 1;
BA_ "U_V710_MY2023_Rx" SG_ 946 DrStatRr_B_Actl 1;
BA_ "U_P708_MY2023_Rx" SG_ 946 DrStatRr_B_Actl 1;
BA_ "U_V713AV_MY2022_Rx" SG_ 946 DrStatRr_B_Actl 1;
BA_ "U_V713N_MY2022_Rx" SG_ 946 DrStatRr_B_Actl 1;
BA_ "WakeupSignal" SG_ 946 DrStatRr_B_Actl 1;
BA_ "U_V710_MY2023_Rx" SG_ 946 DrStatRl_B_Actl 1;
BA_ "U_P708_MY2023_Rx" SG_ 946 DrStatRl_B_Actl 1;
BA_ "U_V713AV_MY2022_Rx" SG_ 946 DrStatRl_B_Actl 1;
BA_ "U_V713N_MY2022_Rx" SG_ 946 DrStatRl_B_Actl 1;
BA_ "WakeupSignal" SG_ 946 DrStatRl_B_Actl 1;
BA_ "U_V710_MY2023_Rx" SG_ 946 DrStatPsngr_B_Actl 1;
BA_ "U_P708_MY2023_Rx" SG_ 946 DrStatPsngr_B_Actl 1;
BA_ "U_V713AV_MY2022_Rx" SG_ 946 DrStatPsngr_B_Actl 1;
BA_ "U_V713N_MY2022_Rx" SG_ 946 DrStatPsngr_B_Actl 1;
BA_ "WakeupSignal" SG_ 946 DrStatPsngr_B_Actl 1;
BA_ "U_V710_MY2023_Rx" SG_ 946 FogLghtFrontOn_B_Stat 1;
BA_ "U_P708_MY2023_Rx" SG_ 946 FogLghtFrontOn_B_Stat 1;
BA_ "U_V713AV_MY2022_Rx" SG_ 946 FogLghtFrontOn_B_Stat 1;
BA_ "U_V713N_MY2022_Rx" SG_ 946 FogLghtFrontOn_B_Stat 1;
BA_ "U_V710_MY2023_Rx" SG_ 946 DrStatInnrTgate_B_Actl 1;
BA_ "U_P708_MY2023_Rx" SG_ 946 DrStatInnrTgate_B_Actl 1;
BA_ "U_V713AV_MY2022_Rx" SG_ 946 DrStatInnrTgate_B_Actl 1;
BA_ "U_V713N_MY2022_Rx" SG_ 946 DrStatInnrTgate_B_Actl 1;
BA_ "WakeupSignal" SG_ 946 DrStatInnrTgate_B_Actl 1;
BA_ "U_V710_MY2023_Rx" SG_ 946 DrStatHood_B_Actl 1;
BA_ "U_P708_MY2023_Rx" SG_ 946 DrStatHood_B_Actl 1;
BA_ "U_V713AV_MY2022_Rx" SG_ 946 DrStatHood_B_Actl 1;
BA_ "U_V713N_MY2022_Rx" SG_ 946 DrStatHood_B_Actl 1;
BA_ "WakeupSignal" SG_ 946 DrStatHood_B_Actl 1;
BA_ "U_V710_MY2023_Rx" SG_ 946 DrStatDrv_B_Actl 1;
BA_ "U_P708_MY2023_Rx" SG_ 946 DrStatDrv_B_Actl 1;
BA_ "U_V713AV_MY2022_Rx" SG_ 946 DrStatDrv_B_Actl 1;
BA_ "U_V713N_MY2022_Rx" SG_ 946 DrStatDrv_B_Actl 1;
BA_ "WakeupSignal" SG_ 946 DrStatDrv_B_Actl 1;
BA_ "U_V713AV_MY2022_Rx" SG_ 946 PrkBrkActv_B_Actl 1;
BA_ "U_V713N_MY2022_Rx" SG_ 946 PrkBrkActv_B_Actl 1;
BA_ "WakeupSignal" SG_ 946 PrkBrkActv_B_Actl 1;
BA_ "U_V710_MY2023_Rx" SG_ 946 LifeCycMde_D_Actl 1;
BA_ "U_P708_MY2023_Rx" SG_ 946 LifeCycMde_D_Actl 1;
BA_ "U_V713AV_MY2022_Rx" SG_ 946 LifeCycMde_D_Actl 1;
BA_ "U_V713N_MY2022_Rx" SG_ 946 LifeCycMde_D_Actl 1;
BA_ "U_V710_MY2023_Rx" SG_ 946 Delay_Accy 1;
BA_ "U_P708_MY2023_Rx" SG_ 946 Delay_Accy 1;
BA_ "U_V713AV_MY2022_Rx" SG_ 946 Delay_Accy 1;
BA_ "U_V713N_MY2022_Rx" SG_ 946 Delay_Accy 1;
BA_ "WakeupSignal" SG_ 946 Delay_Accy 1;
BA_ "U_V710_MY2023_Rx" SG_ 946 TurnLghtLeft_D_Rq 1;
BA_ "U_P708_MY2023_Rx" SG_ 946 TurnLghtLeft_D_Rq 1;
BA_ "WakeupSignal" SG_ 946 TurnLghtLeft_D_Rq 1;
BA_ "GenSigStartValue" SG_ 946 CrashEvnt_D_Stat 3;
BA_ "WakeupSignal" SG_ 946 CrashEvnt_D_Stat 1;
BA_ "U_V710_MY2023_Rx" SG_ 946 BodySrvcRqd_B_Rq 1;
BA_ "U_P708_MY2023_Rx" SG_ 946 BodySrvcRqd_B_Rq 1;
BA_ "U_V713AV_MY2022_Rx" SG_ 946 BodySrvcRqd_B_Rq 1;
BA_ "U_V713N_MY2022_Rx" SG_ 946 BodySrvcRqd_B_Rq 1;
BA_ "U_V710_MY2023_Tx" SG_ 778 PrkAidAcsyRear_D_RqDrv 1;
BA_ "U_P708_MY2023_Tx" SG_ 778 PrkAidAcsyRear_D_RqDrv 1;
BA_ "U_V713AV_MY2022_Tx" SG_ 778 PrkAidAcsyRear_D_RqDrv 1;
BA_ "U_V713N_MY2022_Tx" SG_ 778 PrkAidAcsyRear_D_RqDrv 1;
BA_ "GenSigSendType" SG_ 778 PrkAidAcsyRear_D_RqDrv 3;
BA_ "U_V710_MY2023_Tx" SG_ 778 PrkAidAcsyFront_D_RqDrv 1;
BA_ "U_P708_MY2023_Tx" SG_ 778 PrkAidAcsyFront_D_RqDrv 1;
BA_ "U_V713AV_MY2022_Tx" SG_ 778 PrkAidAcsyFront_D_RqDrv 1;
BA_ "U_V713N_MY2022_Tx" SG_ 778 PrkAidAcsyFront_D_RqDrv 1;
BA_ "GenSigSendType" SG_ 778 PrkAidAcsyFront_D_RqDrv 3;
BA_ "U_V710_MY2023_Tx" SG_ 778 Cta_D_Rq 1;
BA_ "U_P708_MY2023_Tx" SG_ 778 Cta_D_Rq 1;
BA_ "U_V713AV_MY2022_Tx" SG_ 778 Cta_D_Rq 1;
BA_ "U_V713N_MY2022_Tx" SG_ 778 Cta_D_Rq 1;
BA_ "GenSigSendType" SG_ 778 Cta_D_Rq 3;
BA_ "GenSigStartValue" SG_ 778 Cta_D_Rq 1;
BA_ "U_V710_MY2023_Tx" SG_ 778 PrkAidRear_D_RqDrv 1;
BA_ "U_P708_MY2023_Tx" SG_ 778 PrkAidRear_D_RqDrv 1;
BA_ "U_V713AV_MY2022_Tx" SG_ 778 PrkAidRear_D_RqDrv 1;
BA_ "U_V713N_MY2022_Tx" SG_ 778 PrkAidRear_D_RqDrv 1;
BA_ "GenSigSendType" SG_ 778 PrkAidRear_D_RqDrv 3;
BA_ "U_P708_MY2023_Tx" SG_ 778 PrkAidFront_D_RqDrv 1;
BA_ "U_V713AV_MY2022_Tx" SG_ 778 PrkAidFront_D_RqDrv 1;
BA_ "U_V713N_MY2022_Tx" SG_ 778 PrkAidFront_D_RqDrv 1;
BA_ "GenSigSendType" SG_ 778 PrkAidFront_D_RqDrv 3;
BA_ "U_P708_MY2023_Tx" SG_ 778 SteEffort_D_Rq 1;
BA_ "U_V713AV_MY2022_Tx" SG_ 778 SteEffort_D_Rq 1;
BA_ "U_V713N_MY2022_Tx" SG_ 778 SteEffort_D_Rq 1;
BA_ "GenSigSendType" SG_ 778 SteEffort_D_Rq 3;
BA_ "U_V710_MY2023_Tx" SG_ 778 ClrExitAsstEnbl_D_RqDrv 1;
BA_ "U_P708_MY2023_Tx" SG_ 778 ClrExitAsstEnbl_D_RqDrv 1;
BA_ "U_V713AV_MY2022_Tx" SG_ 778 ClrExitAsstEnbl_D_RqDrv 1;
BA_ "GenSigSendType" SG_ 778 ClrExitAsstEnbl_D_RqDrv 3;
BA_ "U_V710_MY2023_Tx" SG_ 778 Sod_D_Rq 1;
BA_ "U_P708_MY2023_Tx" SG_ 778 Sod_D_Rq 1;
BA_ "U_V713AV_MY2022_Tx" SG_ 778 Sod_D_Rq 1;
BA_ "U_V713N_MY2022_Tx" SG_ 778 Sod_D_Rq 1;
BA_ "GenSigSendType" SG_ 778 Sod_D_Rq 3;
BA_ "GenSigStartValue" SG_ 778 Sod_D_Rq 2;
BA_ "U_P708_MY2023_Tx" SG_ 1093 TrlBrkInitOut_D_Stat 1;
BA_ "U_V710_MY2023_Rx" SG_ 1093 TrlBrkInitOut_D_Stat 1;
BA_ "U_P708_MY2023_Rx" SG_ 1093 TrlBrkInitOut_D_Stat 1;
BA_ "U_V713AV_MY2022_Rx" SG_ 1093 TrlBrkInitOut_D_Stat 1;
BA_ "U_V713N_MY2022_Rx" SG_ 1093 TrlBrkInitOut_D_Stat 1;
BA_ "U_P708_MY2023_Tx" SG_ 1093 TrlrBrkOut_No_Dsply 1;
BA_ "U_P708_MY2023_Rx" SG_ 1093 TrlrBrkOut_No_Dsply 1;
BA_ "U_V713AV_MY2022_Rx" SG_ 1093 TrlrBrkOut_No_Dsply 1;
BA_ "U_V713N_MY2022_Rx" SG_ 1093 TrlrBrkOut_No_Dsply 1;
BA_ "U_P708_MY2023_Tx" SG_ 1093 TrlrBrkMde_D_Actl 1;
BA_ "U_V710_MY2023_Rx" SG_ 1093 TrlrBrkMde_D_Actl 1;
BA_ "U_P708_MY2023_Rx" SG_ 1093 TrlrBrkMde_D_Actl 1;
BA_ "U_V713AV_MY2022_Rx" SG_ 1093 TrlrBrkMde_D_Actl 1;
BA_ "U_V713N_MY2022_Rx" SG_ 1093 TrlrBrkMde_D_Actl 1;
BA_ "U_P708_MY2023_Tx" SG_ 1093 TrlrBrkGain_No_Actl 1;
BA_ "U_V710_MY2023_Rx" SG_ 1093 TrlrBrkGain_No_Actl 1;
BA_ "U_P708_MY2023_Rx" SG_ 1093 TrlrBrkGain_No_Actl 1;
BA_ "U_V713AV_MY2022_Rx" SG_ 1093 TrlrBrkGain_No_Actl 1;
BA_ "U_V713N_MY2022_Rx" SG_ 1093 TrlrBrkGain_No_Actl 1;
BA_ "U_P708_MY2023_Tx" SG_ 1093 TrlrBrkDsply_B_Rq 1;
BA_ "U_V710_MY2023_Rx" SG_ 1093 TrlrBrkDsply_B_Rq 1;
BA_ "U_P708_MY2023_Rx" SG_ 1093 TrlrBrkDsply_B_Rq 1;
BA_ "U_V713AV_MY2022_Rx" SG_ 1093 TrlrBrkDsply_B_Rq 1;
BA_ "U_V713N_MY2022_Rx" SG_ 1093 TrlrBrkDsply_B_Rq 1;
BA_ "U_P708_MY2023_Tx" SG_ 1093 TrlrBrkDcnnt_B_Actl 1;
BA_ "U_V710_MY2023_Rx" SG_ 1093 TrlrBrkDcnnt_B_Actl 1;
BA_ "U_P708_MY2023_Rx" SG_ 1093 TrlrBrkDcnnt_B_Actl 1;
BA_ "U_V713AV_MY2022_Rx" SG_ 1093 TrlrBrkDcnnt_B_Actl 1;
BA_ "U_V713N_MY2022_Rx" SG_ 1093 TrlrBrkDcnnt_B_Actl 1;
BA_ "U_P708_MY2023_Tx" SG_ 1093 TrlrBrkActCnnct_B_Actl 1;
BA_ "U_V710_MY2023_Rx" SG_ 1093 TrlrBrkActCnnct_B_Actl 1;
BA_ "U_P708_MY2023_Rx" SG_ 1093 TrlrBrkActCnnct_B_Actl 1;
BA_ "U_V713AV_MY2022_Rx" SG_ 1093 TrlrBrkActCnnct_B_Actl 1;
BA_ "U_V713N_MY2022_Rx" SG_ 1093 TrlrBrkActCnnct_B_Actl 1;
BA_ "U_P708_MY2023_Tx" SG_ 1093 StopLamp_B_RqTrlrBrk 1;
BA_ "U_P708_MY2023_Tx" SG_ 1093 TrlrBrkCtl_B_Falt 1;
BA_ "U_V710_MY2023_Rx" SG_ 1093 TrlrBrkCtl_B_Falt 1;
BA_ "U_P708_MY2023_Rx" SG_ 1093 TrlrBrkCtl_B_Falt 1;
BA_ "U_V713AV_MY2022_Rx" SG_ 1093 TrlrBrkCtl_B_Falt 1;
BA_ "U_V713N_MY2022_Rx" SG_ 1093 TrlrBrkCtl_B_Falt 1;
BA_ "U_P708_MY2023_Tx" SG_ 1093 TrlrBrkActCirct_B_Falt 1;
BA_ "U_V710_MY2023_Rx" SG_ 1093 TrlrBrkActCirct_B_Falt 1;
BA_ "U_P708_MY2023_Rx" SG_ 1093 TrlrBrkActCirct_B_Falt 1;
BA_ "U_V713AV_MY2022_Rx" SG_ 1093 TrlrBrkActCirct_B_Falt 1;
BA_ "U_V713N_MY2022_Rx" SG_ 1093 TrlrBrkActCirct_B_Falt 1;
BA_ "GenSigSendType" SG_ 1879 TesterPhysicalReqTBM 3;
BA_ "U_V710_MY2023_Rx" SG_ 999 FeatNoFcimActl 1;
BA_ "U_P708_MY2023_Rx" SG_ 999 FeatNoFcimActl 1;
BA_ "U_V713AV_MY2022_Rx" SG_ 999 FeatNoFcimActl 1;
BA_ "U_V713N_MY2022_Rx" SG_ 999 FeatNoFcimActl 1;
BA_ "U_V710_MY2023_Rx" SG_ 999 FeatConfigFcimActl 1;
BA_ "U_P708_MY2023_Rx" SG_ 999 FeatConfigFcimActl 1;
BA_ "U_V713AV_MY2022_Rx" SG_ 999 FeatConfigFcimActl 1;
BA_ "U_V713N_MY2022_Rx" SG_ 999 FeatConfigFcimActl 1;
BA_ "U_V710_MY2023_Rx" SG_ 999 PersIndexFcim_D_Actl 1;
BA_ "U_P708_MY2023_Rx" SG_ 999 PersIndexFcim_D_Actl 1;
BA_ "U_V713AV_MY2022_Rx" SG_ 999 PersIndexFcim_D_Actl 1;
BA_ "U_V713N_MY2022_Rx" SG_ 999 PersIndexFcim_D_Actl 1;
BA_ "GenSigStartValue" SG_ 999 PersIndexFcim_D_Actl 4;
BA_ "U_V713AV_MY2022_Rx" SG_ 1002 PersIndexApim_D_Actl 1;
BA_ "U_V713N_MY2022_Rx" SG_ 1002 PersIndexApim_D_Actl 1;
BA_ "GenSigSendType" SG_ 1002 PersIndexApim_D_Actl 3;
BA_ "GenSigStartValue" SG_ 1002 PersIndexApim_D_Actl 4;
BA_ "U_V713AV_MY2022_Rx" SG_ 1002 FeatNoApimActl 1;
BA_ "U_V713N_MY2022_Rx" SG_ 1002 FeatNoApimActl 1;
BA_ "GenSigSendType" SG_ 1002 FeatNoApimActl 3;
BA_ "U_V713AV_MY2022_Rx" SG_ 1002 FeatConfigApimActl 1;
BA_ "U_V713N_MY2022_Rx" SG_ 1002 FeatConfigApimActl 1;
BA_ "GenSigSendType" SG_ 1002 FeatConfigApimActl 3;
BA_ "GenSigSendType" SG_ 1002 CntrStkKeycodeActl 3;
BA_ "GenSigSendType" SG_ 1002 CntrStk_D_RqRecall 3;
BA_ "WakeupSignal" SG_ 1002 CntrStk_D_RqRecall 1;
BA_ "GenSigSendType" SG_ 1002 CntrStk_D_RqAssoc 3;
BA_ "GenSigStartValue" SG_ 1002 CntrStk_D_RqAssoc 3;
BA_ "U_V710_MY2023_Rx" SG_ 948 Tire_Press_Placrd_Rear 1;
BA_ "U_P708_MY2023_Rx" SG_ 948 Tire_Press_Placrd_Rear 1;
BA_ "U_V713AV_MY2022_Rx" SG_ 948 Tire_Press_Placrd_Rear 1;
BA_ "U_V713N_MY2022_Rx" SG_ 948 Tire_Press_Placrd_Rear 1;
BA_ "GenSigStartValue" SG_ 948 Tire_Press_Placrd_Rear 255;
BA_ "U_V710_MY2023_Rx" SG_ 948 Tire_Press_Placrd_Frnt 1;
BA_ "U_P708_MY2023_Rx" SG_ 948 Tire_Press_Placrd_Frnt 1;
BA_ "U_V713AV_MY2022_Rx" SG_ 948 Tire_Press_Placrd_Frnt 1;
BA_ "U_V713N_MY2022_Rx" SG_ 948 Tire_Press_Placrd_Frnt 1;
BA_ "GenSigStartValue" SG_ 948 Tire_Press_Placrd_Frnt 255;
BA_ "U_V710_MY2023_Rx" SG_ 948 TirePReset_D_Stat 1;
BA_ "U_P708_MY2023_Rx" SG_ 948 TirePReset_D_Stat 1;
BA_ "U_V713AV_MY2022_Rx" SG_ 948 TirePReset_D_Stat 1;
BA_ "U_V713N_MY2022_Rx" SG_ 948 TirePReset_D_Stat 1;
BA_ "U_V710_MY2023_Rx" SG_ 948 Tire_Press_ILR_Stat 1;
BA_ "U_P708_MY2023_Rx" SG_ 948 Tire_Press_ILR_Stat 1;
BA_ "U_V713AV_MY2022_Rx" SG_ 948 Tire_Press_ILR_Stat 1;
BA_ "U_V713N_MY2022_Rx" SG_ 948 Tire_Press_ILR_Stat 1;
BA_ "U_V710_MY2023_Rx" SG_ 948 Tire_Press_IRR_Stat 1;
BA_ "U_P708_MY2023_Rx" SG_ 948 Tire_Press_IRR_Stat 1;
BA_ "U_V713AV_MY2022_Rx" SG_ 948 Tire_Press_IRR_Stat 1;
BA_ "U_V713N_MY2022_Rx" SG_ 948 Tire_Press_IRR_Stat 1;
BA_ "U_V710_MY2023_Rx" SG_ 948 Tire_Press_LR_OLR_Stat 1;
BA_ "U_P708_MY2023_Rx" SG_ 948 Tire_Press_LR_OLR_Stat 1;
BA_ "U_V713AV_MY2022_Rx" SG_ 948 Tire_Press_LR_OLR_Stat 1;
BA_ "U_V713N_MY2022_Rx" SG_ 948 Tire_Press_LR_OLR_Stat 1;
BA_ "U_V710_MY2023_Rx" SG_ 948 Tire_Press_RR_ORR_Stat 1;
BA_ "U_P708_MY2023_Rx" SG_ 948 Tire_Press_RR_ORR_Stat 1;
BA_ "U_V713AV_MY2022_Rx" SG_ 948 Tire_Press_RR_ORR_Stat 1;
BA_ "U_V713N_MY2022_Rx" SG_ 948 Tire_Press_RR_ORR_Stat 1;
BA_ "U_V710_MY2023_Rx" SG_ 948 Tire_Press_RF_Stat 1;
BA_ "U_P708_MY2023_Rx" SG_ 948 Tire_Press_RF_Stat 1;
BA_ "U_V713AV_MY2022_Rx" SG_ 948 Tire_Press_RF_Stat 1;
BA_ "U_V713N_MY2022_Rx" SG_ 948 Tire_Press_RF_Stat 1;
BA_ "U_V710_MY2023_Rx" SG_ 948 Tire_Press_LF_Stat 1;
BA_ "U_P708_MY2023_Rx" SG_ 948 Tire_Press_LF_Stat 1;
BA_ "U_V713AV_MY2022_Rx" SG_ 948 Tire_Press_LF_Stat 1;
BA_ "U_V713N_MY2022_Rx" SG_ 948 Tire_Press_LF_Stat 1;
BA_ "U_V710_MY2023_Rx" SG_ 948 Tire_Press_System_Stat 1;
BA_ "U_P708_MY2023_Rx" SG_ 948 Tire_Press_System_Stat 1;
BA_ "U_V713AV_MY2022_Rx" SG_ 948 Tire_Press_System_Stat 1;
BA_ "U_V713N_MY2022_Rx" SG_ 948 Tire_Press_System_Stat 1;
BA_ "U_V710_MY2023_Rx" SG_ 948 Tire_Press_Telltale 1;
BA_ "U_P708_MY2023_Rx" SG_ 948 Tire_Press_Telltale 1;
BA_ "U_V713AV_MY2022_Rx" SG_ 948 Tire_Press_Telltale 1;
BA_ "U_V713N_MY2022_Rx" SG_ 948 Tire_Press_Telltale 1;
BA_ "GenSigSendType" SG_ 986 VehPayloadScrn_D_Rq 3;
BA_ "GenSigSendType" SG_ 986 Trlr_M_Rq 3;
BA_ "GenSigStartValue" SG_ 986 Trlr_M_Rq 2046;
BA_ "GenSigSendType" SG_ 986 VehPayloadTare_D_Rq 3;
BA_ "GenSigSendType" SG_ 986 VehFalr_D_Rq 3;
BA_ "GenSigSendType" SG_ 986 TailLghtLoadMde_D_Rq 3;
BA_ "GenSigSendType" SG_ 986 LightAmbIntsty_No_Rq 3;
BA_ "GenSigSendType" SG_ 986 LightAmbColor_No_Rq 3;
BA_ "U_V710_MY2023_Rx" SG_ 993 MemStoreMsgTxt_D_Rq 1;
BA_ "U_P708_MY2023_Rx" SG_ 993 MemStoreMsgTxt_D_Rq 1;
BA_ "U_V713AV_MY2022_Rx" SG_ 993 MemStoreMsgTxt_D_Rq 1;
BA_ "U_V713N_MY2022_Rx" SG_ 993 MemStoreMsgTxt_D_Rq 1;
BA_ "U_V710_MY2023_Rx" SG_ 993 MemSetButtnMsgTxt_D_Rq 1;
BA_ "U_P708_MY2023_Rx" SG_ 993 MemSetButtnMsgTxt_D_Rq 1;
BA_ "U_V713AV_MY2022_Rx" SG_ 993 MemSetButtnMsgTxt_D_Rq 1;
BA_ "U_V713N_MY2022_Rx" SG_ 993 MemSetButtnMsgTxt_D_Rq 1;
BA_ "WakeupSignal" SG_ 993 MemSwtch_D_RqRecall 1;
BA_ "WakeupSignal" SG_ 993 MemSwtch_D_RqAssoc 1;
BA_ "U_V710_MY2023_Rx" SG_ 993 PersIndexDsm_D_Actl 1;
BA_ "U_P708_MY2023_Rx" SG_ 993 PersIndexDsm_D_Actl 1;
BA_ "U_V713AV_MY2022_Rx" SG_ 993 PersIndexDsm_D_Actl 1;
BA_ "U_V713N_MY2022_Rx" SG_ 993 PersIndexDsm_D_Actl 1;
BA_ "GenSigStartValue" SG_ 993 PersIndexDsm_D_Actl 4;
BA_ "U_V710_MY2023_Rx" SG_ 993 FeatNoDsmActl 1;
BA_ "U_P708_MY2023_Rx" SG_ 993 FeatNoDsmActl 1;
BA_ "U_V713AV_MY2022_Rx" SG_ 993 FeatNoDsmActl 1;
BA_ "U_V713N_MY2022_Rx" SG_ 993 FeatNoDsmActl 1;
BA_ "U_V710_MY2023_Rx" SG_ 993 FeatConfigDsmActl 1;
BA_ "U_P708_MY2023_Rx" SG_ 993 FeatConfigDsmActl 1;
BA_ "U_V713AV_MY2022_Rx" SG_ 993 FeatConfigDsmActl 1;
BA_ "U_V713N_MY2022_Rx" SG_ 993 FeatConfigDsmActl 1;
BA_ "U_V710_MY2023_Rx" SG_ 1814 TesterPhysicalReqGWM_H3 1;
BA_ "U_P708_MY2023_Rx" SG_ 1814 TesterPhysicalReqGWM_H3 1;
BA_ "U_V713AV_MY2022_Rx" SG_ 1814 TesterPhysicalReqGWM_H3 1;
BA_ "U_V713N_MY2022_Rx" SG_ 1814 TesterPhysicalReqGWM_H3 1;
BA_ "ECGUsedRxSignal" SG_ 1814 TesterPhysicalReqGWM_H3 1;
BA_ "GenSigSendType" SG_ 1814 TesterPhysicalReqGWM_H3 3;
BA_ "GenSigStartValue" SG_ 997 PersTurnSglView_D_Stat 3;
BA_ "U_V710_MY2023_Rx" SG_ 997 PersIndexCcm_D_Actl 1;
BA_ "U_P708_MY2023_Rx" SG_ 997 PersIndexCcm_D_Actl 1;
BA_ "U_V713AV_MY2022_Rx" SG_ 997 PersIndexCcm_D_Actl 1;
BA_ "U_V713N_MY2022_Rx" SG_ 997 PersIndexCcm_D_Actl 1;
BA_ "GenSigStartValue" SG_ 997 PersIndexCcm_D_Actl 4;
BA_ "U_V710_MY2023_Rx" SG_ 997 FeatNoCcmActl 1;
BA_ "U_P708_MY2023_Rx" SG_ 997 FeatNoCcmActl 1;
BA_ "U_V713AV_MY2022_Rx" SG_ 997 FeatNoCcmActl 1;
BA_ "U_V713N_MY2022_Rx" SG_ 997 FeatNoCcmActl 1;
BA_ "U_V710_MY2023_Rx" SG_ 997 FeatConfigCcmActl 1;
BA_ "U_P708_MY2023_Rx" SG_ 997 FeatConfigCcmActl 1;
BA_ "U_V713AV_MY2022_Rx" SG_ 997 FeatConfigCcmActl 1;
BA_ "U_V713N_MY2022_Rx" SG_ 997 FeatConfigCcmActl 1;
BA_ "U_P708_MY2023_Tx" SG_ 487 Aioc_SetExtSrcOutpMd_Rq 1;
BA_ "U_V713AV_MY2022_Tx" SG_ 487 Aioc_SetExtSrcOutpMd_Rq 1;
BA_ "U_V713N_MY2022_Tx" SG_ 487 Aioc_SetExtSrcOutpMd_Rq 1;
BA_ "GenSigSendType" SG_ 487 Aioc_SetExtSrcOutpMd_Rq 3;
BA_ "U_V710_MY2023_Tx" SG_ 464 SdarsSampleRate_D_Rq 1;
BA_ "U_P708_MY2023_Tx" SG_ 464 SdarsSampleRate_D_Rq 1;
BA_ "U_V713AV_MY2022_Tx" SG_ 464 SdarsSampleRate_D_Rq 1;
BA_ "U_V713N_MY2022_Tx" SG_ 464 SdarsSampleRate_D_Rq 1;
BA_ "GenSigSendType" SG_ 464 SdarsSampleRate_D_Rq 3;
BA_ "U_V710_MY2023_Tx" SG_ 464 SDARS_DirectChannel_Rq 1;
BA_ "U_P708_MY2023_Tx" SG_ 464 SDARS_DirectChannel_Rq 1;
BA_ "U_V713AV_MY2022_Tx" SG_ 464 SDARS_DirectChannel_Rq 1;
BA_ "U_V713N_MY2022_Tx" SG_ 464 SDARS_DirectChannel_Rq 1;
BA_ "GenSigStartValue" SG_ 464 SDARS_DirectChannel_Rq 1023;
BA_ "GenSigStartValue" SG_ 864 DrvrFcsdMde_Btn_Stt 2;
BA_ "U_V713AV_MY2022_Rx" SG_ 864 RHS_Cond_Seat_Status 1;
BA_ "U_V713N_MY2022_Rx" SG_ 864 RHS_Cond_Seat_Status 1;
BA_ "U_P708_MY2023_Rx" SG_ 864 LHS_Cond_Seat_Status 1;
BA_ "U_V713AV_MY2022_Rx" SG_ 864 LHS_Cond_Seat_Status 1;
BA_ "U_V713N_MY2022_Rx" SG_ 864 LHS_Cond_Seat_Status 1;
BA_ "U_P708_MY2023_Rx" SG_ 864 Htd_Strg_Whl_Status 1;
BA_ "U_V713AV_MY2022_Rx" SG_ 864 Htd_Strg_Whl_Status 1;
BA_ "U_V713N_MY2022_Rx" SG_ 864 Htd_Strg_Whl_Status 1;
BA_ "GenSigStartValue" SG_ 864 Htd_Strg_Whl_Status 2;
BA_ "U_V713AV_MY2022_Rx" SG_ 864 Htd_Strg_Whl_Btn_Stt 1;
BA_ "U_V713N_MY2022_Rx" SG_ 864 Htd_Strg_Whl_Btn_Stt 1;
BA_ "GenSigStartValue" SG_ 864 Htd_Strg_Whl_Btn_Stt 2;
BA_ "U_V713AV_MY2022_Rx" SG_ 864 Defrost_Btn_Stt 1;
BA_ "U_V713N_MY2022_Rx" SG_ 864 Defrost_Btn_Stt 1;
BA_ "GenSigStartValue" SG_ 864 Defrost_Btn_Stt 2;
BA_ "U_P708_MY2023_Rx" SG_ 864 CC_Fr_Btn_User_Adj 1;
BA_ "U_V713AV_MY2022_Rx" SG_ 864 RHS_Htd_Seat_Btn_Stt 1;
BA_ "U_V713N_MY2022_Rx" SG_ 864 RHS_Htd_Seat_Btn_Stt 1;
BA_ "GenSigStartValue" SG_ 864 RHS_Htd_Seat_Btn_Stt 2;
BA_ "U_V713AV_MY2022_Rx" SG_ 864 RHS_Cld_Seat_Btn_Stt 1;
BA_ "U_V713N_MY2022_Rx" SG_ 864 RHS_Cld_Seat_Btn_Stt 1;
BA_ "GenSigStartValue" SG_ 864 RHS_Cld_Seat_Btn_Stt 2;
BA_ "U_V713AV_MY2022_Rx" SG_ 864 Outside_Btn_Stt 1;
BA_ "U_V713N_MY2022_Rx" SG_ 864 Outside_Btn_Stt 1;
BA_ "GenSigStartValue" SG_ 864 Outside_Btn_Stt 2;
BA_ "U_V713AV_MY2022_Rx" SG_ 864 LHS_Htd_Seat_Btn_Stt 1;
BA_ "U_V713N_MY2022_Rx" SG_ 864 LHS_Htd_Seat_Btn_Stt 1;
BA_ "GenSigStartValue" SG_ 864 LHS_Htd_Seat_Btn_Stt 2;
BA_ "U_V713AV_MY2022_Rx" SG_ 864 LHS_Cld_Seat_Btn_Stt 1;
BA_ "U_V713N_MY2022_Rx" SG_ 864 LHS_Cld_Seat_Btn_Stt 1;
BA_ "GenSigStartValue" SG_ 864 LHS_Cld_Seat_Btn_Stt 2;
BA_ "U_P708_MY2023_Rx" SG_ 864 Htd_Frt_Wsh_Btn_Stt 1;
BA_ "U_V713AV_MY2022_Rx" SG_ 864 Htd_Frt_Wsh_Btn_Stt 1;
BA_ "U_V713N_MY2022_Rx" SG_ 864 Htd_Frt_Wsh_Btn_Stt 1;
BA_ "GenSigStartValue" SG_ 864 Htd_Frt_Wsh_Btn_Stt 2;
BA_ "U_V713AV_MY2022_Rx" SG_ 864 Auto_Recirc_Btn_Stt 1;
BA_ "U_V713N_MY2022_Rx" SG_ 864 Auto_Recirc_Btn_Stt 1;
BA_ "GenSigStartValue" SG_ 864 Auto_Recirc_Btn_Stt 2;
BA_ "U_P708_MY2023_Rx" SG_ 864 Recirc_Btn_Stt 1;
BA_ "U_V713AV_MY2022_Rx" SG_ 864 Recirc_Btn_Stt 1;
BA_ "U_V713N_MY2022_Rx" SG_ 864 Recirc_Btn_Stt 1;
BA_ "GenSigStartValue" SG_ 864 Recirc_Btn_Stt 2;
BA_ "U_P708_MY2023_Rx" SG_ 864 Rear_Defrost_Btn_Stt 1;
BA_ "U_V713AV_MY2022_Rx" SG_ 864 Rear_Defrost_Btn_Stt 1;
BA_ "U_V713N_MY2022_Rx" SG_ 864 Rear_Defrost_Btn_Stt 1;
BA_ "GenSigStartValue" SG_ 864 Rear_Defrost_Btn_Stt 2;
BA_ "U_P708_MY2023_Rx" SG_ 864 My_Temp_Btn_Stt 1;
BA_ "U_V713AV_MY2022_Rx" SG_ 864 My_Temp_Btn_Stt 1;
BA_ "U_V713N_MY2022_Rx" SG_ 864 My_Temp_Btn_Stt 1;
BA_ "GenSigStartValue" SG_ 864 My_Temp_Btn_Stt 2;
BA_ "U_P708_MY2023_Rx" SG_ 864 Max_Defrost_Btn_Stt 1;
BA_ "U_V713AV_MY2022_Rx" SG_ 864 Max_Defrost_Btn_Stt 1;
BA_ "U_V713N_MY2022_Rx" SG_ 864 Max_Defrost_Btn_Stt 1;
BA_ "GenSigStartValue" SG_ 864 Max_Defrost_Btn_Stt 2;
BA_ "U_P708_MY2023_Rx" SG_ 864 Max_AC_Btn_Stt 1;
BA_ "U_V713AV_MY2022_Rx" SG_ 864 Max_AC_Btn_Stt 1;
BA_ "U_V713N_MY2022_Rx" SG_ 864 Max_AC_Btn_Stt 1;
BA_ "GenSigStartValue" SG_ 864 Max_AC_Btn_Stt 2;
BA_ "U_P708_MY2023_Rx" SG_ 864 Front_AUTO_Label 1;
BA_ "U_V713AV_MY2022_Rx" SG_ 864 Front_AUTO_Label 1;
BA_ "U_V713N_MY2022_Rx" SG_ 864 Front_AUTO_Label 1;
BA_ "GenSigStartValue" SG_ 864 Front_AUTO_Label 2;
BA_ "U_V713AV_MY2022_Rx" SG_ 864 Windscreen_Btn_Stt 1;
BA_ "U_V713N_MY2022_Rx" SG_ 864 Windscreen_Btn_Stt 1;
BA_ "GenSigStartValue" SG_ 864 Windscreen_Btn_Stt 2;
BA_ "U_P708_MY2023_Rx" SG_ 864 Panel_Btn_Stt 1;
BA_ "U_V713AV_MY2022_Rx" SG_ 864 Panel_Btn_Stt 1;
BA_ "U_V713N_MY2022_Rx" SG_ 864 Panel_Btn_Stt 1;
BA_ "GenSigStartValue" SG_ 864 Panel_Btn_Stt 2;
BA_ "U_P708_MY2023_Rx" SG_ 864 Front_Power_Btn_Stt 1;
BA_ "U_V713AV_MY2022_Rx" SG_ 864 Front_Power_Btn_Stt 1;
BA_ "U_V713N_MY2022_Rx" SG_ 864 Front_Power_Btn_Stt 1;
BA_ "GenSigStartValue" SG_ 864 Front_Power_Btn_Stt 2;
BA_ "U_P708_MY2023_Rx" SG_ 864 Front_AUTO_Btn_Stt 1;
BA_ "U_V713AV_MY2022_Rx" SG_ 864 Front_AUTO_Btn_Stt 1;
BA_ "U_V713N_MY2022_Rx" SG_ 864 Front_AUTO_Btn_Stt 1;
BA_ "GenSigStartValue" SG_ 864 Front_AUTO_Btn_Stt 2;
BA_ "U_P708_MY2023_Rx" SG_ 864 Floor_Btn_Stt 1;
BA_ "U_V713AV_MY2022_Rx" SG_ 864 Floor_Btn_Stt 1;
BA_ "U_V713N_MY2022_Rx" SG_ 864 Floor_Btn_Stt 1;
BA_ "GenSigStartValue" SG_ 864 Floor_Btn_Stt 2;
BA_ "U_P708_MY2023_Rx" SG_ 864 Dual_Button_Stt 1;
BA_ "U_V713AV_MY2022_Rx" SG_ 864 Dual_Button_Stt 1;
BA_ "U_V713N_MY2022_Rx" SG_ 864 Dual_Button_Stt 1;
BA_ "GenSigStartValue" SG_ 864 Dual_Button_Stt 2;
BA_ "U_P708_MY2023_Rx" SG_ 864 AC_Btn_Stt 1;
BA_ "U_V713AV_MY2022_Rx" SG_ 864 AC_Btn_Stt 1;
BA_ "U_V713N_MY2022_Rx" SG_ 864 AC_Btn_Stt 1;
BA_ "GenSigStartValue" SG_ 864 AC_Btn_Stt 2;
BA_ "GenSigSendType" SG_ 994 PersCtaSplitView_D_Rq 3;
BA_ "GenSigSendType" SG_ 994 Pers4OptIn_B_Stats 3;
BA_ "WakeupSignal" SG_ 994 Pers4OptIn_B_Stats 1;
BA_ "GenSigSendType" SG_ 994 Pers3OptIn_B_Stats 3;
BA_ "WakeupSignal" SG_ 994 Pers3OptIn_B_Stats 1;
BA_ "GenSigSendType" SG_ 994 Pers2OptIn_B_Stats 3;
BA_ "WakeupSignal" SG_ 994 Pers2OptIn_B_Stats 1;
BA_ "GenSigSendType" SG_ 994 Pers1OptIn_B_Stats 3;
BA_ "WakeupSignal" SG_ 994 Pers1OptIn_B_Stats 1;
BA_ "U_V710_MY2023_Rx" SG_ 994 CtrStkPersIndex_D_Actl 1;
BA_ "U_P708_MY2023_Rx" SG_ 994 CtrStkPersIndex_D_Actl 1;
BA_ "U_V713AV_MY2022_Rx" SG_ 994 CtrStkPersIndex_D_Actl 1;
BA_ "U_V713N_MY2022_Rx" SG_ 994 CtrStkPersIndex_D_Actl 1;
BA_ "GenSigSendType" SG_ 994 CtrStkPersIndex_D_Actl 3;
BA_ "GenSigStartValue" SG_ 994 CtrStkPersIndex_D_Actl 4;
BA_ "U_V710_MY2023_Rx" SG_ 994 CtrStkFeatNoActl 1;
BA_ "U_P708_MY2023_Rx" SG_ 994 CtrStkFeatNoActl 1;
BA_ "U_V713AV_MY2022_Rx" SG_ 994 CtrStkFeatNoActl 1;
BA_ "U_V713N_MY2022_Rx" SG_ 994 CtrStkFeatNoActl 1;
BA_ "GenSigSendType" SG_ 994 CtrStkFeatNoActl 3;
BA_ "U_V710_MY2023_Rx" SG_ 994 CtrStkFeatConfigActl 1;
BA_ "U_P708_MY2023_Rx" SG_ 994 CtrStkFeatConfigActl 1;
BA_ "U_V713AV_MY2022_Rx" SG_ 994 CtrStkFeatConfigActl 1;
BA_ "U_V713N_MY2022_Rx" SG_ 994 CtrStkFeatConfigActl 1;
BA_ "GenSigSendType" SG_ 994 CtrStkFeatConfigActl 3;
BA_ "GenSigSendType" SG_ 994 PersStore_D_Rq 3;
BA_ "U_V710_MY2023_Rx" SG_ 994 CtrStkDsplyOp_D_Rq 1;
BA_ "U_P708_MY2023_Rx" SG_ 994 CtrStkDsplyOp_D_Rq 1;
BA_ "U_V713AV_MY2022_Rx" SG_ 994 CtrStkDsplyOp_D_Rq 1;
BA_ "U_V713N_MY2022_Rx" SG_ 994 CtrStkDsplyOp_D_Rq 1;
BA_ "GenSigSendType" SG_ 994 CtrStkDsplyOp_D_Rq 3;
BA_ "U_V710_MY2023_Tx" SG_ 1822 TesterPhysicalResGWM_H3 1;
BA_ "U_P708_MY2023_Tx" SG_ 1822 TesterPhysicalResGWM_H3 1;
BA_ "U_V713AV_MY2022_Tx" SG_ 1822 TesterPhysicalResGWM_H3 1;
BA_ "U_V713N_MY2022_Tx" SG_ 1822 TesterPhysicalResGWM_H3 1;
BA_ "ECGUsedTxSignal" SG_ 1822 TesterPhysicalResGWM_H3 1;
BA_ "GenSigSendType" SG_ 1822 TesterPhysicalResGWM_H3 3;
BA_ "U_P708_MY2023_Rx" SG_ 394 AccStopStat_D_Dsply 1;
BA_ "U_V713AV_MY2022_Rx" SG_ 394 AccStopStat_D_Dsply 1;
BA_ "U_V713N_MY2022_Rx" SG_ 394 AccStopStat_D_Dsply 1;
BA_ "U_P708_MY2023_Rx" SG_ 394 AccTrgDist2_D_Dsply 1;
BA_ "U_V713AV_MY2022_Rx" SG_ 394 AccTrgDist2_D_Dsply 1;
BA_ "U_V713N_MY2022_Rx" SG_ 394 AccTrgDist2_D_Dsply 1;
BA_ "U_P708_MY2023_Rx" SG_ 394 AccStopRes_B_Dsply 1;
BA_ "U_V713AV_MY2022_Rx" SG_ 394 AccStopRes_B_Dsply 1;
BA_ "U_V713N_MY2022_Rx" SG_ 394 AccStopRes_B_Dsply 1;
BA_ "U_V710_MY2023_Rx" SG_ 394 TjaWarn_D_Rq 1;
BA_ "U_V713AV_MY2022_Rx" SG_ 394 TjaWarn_D_Rq 1;
BA_ "U_V713N_MY2022_Rx" SG_ 394 TjaWarn_D_Rq 1;
BA_ "U_P708_MY2023_Rx" SG_ 394 TjaWarn_D_Rq 1;
BA_ "U_V710_MY2023_Rx" SG_ 394 Tja_D_Stat 1;
BA_ "U_V713AV_MY2022_Rx" SG_ 394 Tja_D_Stat 1;
BA_ "U_V713N_MY2022_Rx" SG_ 394 Tja_D_Stat 1;
BA_ "U_P708_MY2023_Rx" SG_ 394 Tja_D_Stat 1;
BA_ "U_V710_MY2023_Rx" SG_ 394 IaccLamp_D_Rq 1;
BA_ "U_P708_MY2023_Rx" SG_ 394 IaccLamp_D_Rq 1;
BA_ "U_V713AV_MY2022_Rx" SG_ 394 IaccLamp_D_Rq 1;
BA_ "U_V713N_MY2022_Rx" SG_ 394 IaccLamp_D_Rq 1;
BA_ "U_P708_MY2023_Rx" SG_ 394 AccMsgTxt_D2_Rq 1;
BA_ "U_V713AV_MY2022_Rx" SG_ 394 AccMsgTxt_D2_Rq 1;
BA_ "U_V713N_MY2022_Rx" SG_ 394 AccMsgTxt_D2_Rq 1;
BA_ "U_V710_MY2023_Rx" SG_ 394 TjaMsgTxt_D_Dsply 1;
BA_ "U_V713AV_MY2022_Rx" SG_ 394 TjaMsgTxt_D_Dsply 1;
BA_ "U_V713N_MY2022_Rx" SG_ 394 TjaMsgTxt_D_Dsply 1;
BA_ "U_P708_MY2023_Rx" SG_ 394 TjaMsgTxt_D_Dsply 1;
BA_ "U_V710_MY2023_Rx" SG_ 394 HaDsply_No_Cnt 1;
BA_ "U_P708_MY2023_Rx" SG_ 394 HaDsply_No_Cnt 1;
BA_ "MetaData" SG_ 394 HaDsply_No_Cnt 1;
BA_ "U_V710_MY2023_Rx" SG_ 394 FcwDeny_B_Dsply 1;
BA_ "U_P708_MY2023_Rx" SG_ 394 FcwDeny_B_Dsply 1;
BA_ "U_V713AV_MY2022_Rx" SG_ 394 FcwDeny_B_Dsply 1;
BA_ "U_V713N_MY2022_Rx" SG_ 394 FcwDeny_B_Dsply 1;
BA_ "U_P708_MY2023_Rx" SG_ 394 FcwMemStat_B_Actl 1;
BA_ "U_V713AV_MY2022_Rx" SG_ 394 FcwMemStat_B_Actl 1;
BA_ "U_V713N_MY2022_Rx" SG_ 394 FcwMemStat_B_Actl 1;
BA_ "U_P708_MY2023_Rx" SG_ 394 AccTGap_B_Dsply 1;
BA_ "U_V713AV_MY2022_Rx" SG_ 394 AccTGap_B_Dsply 1;
BA_ "U_V713N_MY2022_Rx" SG_ 394 AccTGap_B_Dsply 1;
BA_ "U_P708_MY2023_Rx" SG_ 394 CadsAlignIncplt_B_Actl 1;
BA_ "U_V713AV_MY2022_Rx" SG_ 394 CadsAlignIncplt_B_Actl 1;
BA_ "U_V713N_MY2022_Rx" SG_ 394 CadsAlignIncplt_B_Actl 1;
BA_ "U_P708_MY2023_Rx" SG_ 394 AccFllwMde_B_Dsply 1;
BA_ "U_V713AV_MY2022_Rx" SG_ 394 AccFllwMde_B_Dsply 1;
BA_ "U_V713N_MY2022_Rx" SG_ 394 AccFllwMde_B_Dsply 1;
BA_ "U_V710_MY2023_Rx" SG_ 394 CadsRadrBlck_B_Actl 1;
BA_ "U_P708_MY2023_Rx" SG_ 394 CadsRadrBlck_B_Actl 1;
BA_ "U_V713AV_MY2022_Rx" SG_ 394 CadsRadrBlck_B_Actl 1;
BA_ "U_V713N_MY2022_Rx" SG_ 394 CadsRadrBlck_B_Actl 1;
BA_ "U_V710_MY2023_Rx" SG_ 394 CmbbPostEvnt_B_Dsply 1;
BA_ "U_P708_MY2023_Rx" SG_ 394 CmbbPostEvnt_B_Dsply 1;
BA_ "U_V713AV_MY2022_Rx" SG_ 394 CmbbPostEvnt_B_Dsply 1;
BA_ "U_V713N_MY2022_Rx" SG_ 394 CmbbPostEvnt_B_Dsply 1;
BA_ "U_P708_MY2023_Rx" SG_ 394 AccStopMde_B_Dsply 1;
BA_ "U_V713AV_MY2022_Rx" SG_ 394 AccStopMde_B_Dsply 1;
BA_ "U_V713N_MY2022_Rx" SG_ 394 AccStopMde_B_Dsply 1;
BA_ "U_P708_MY2023_Rx" SG_ 394 FcwMemSens_D_Actl 1;
BA_ "U_V713AV_MY2022_Rx" SG_ 394 FcwMemSens_D_Actl 1;
BA_ "U_V713N_MY2022_Rx" SG_ 394 FcwMemSens_D_Actl 1;
BA_ "U_V710_MY2023_Rx" SG_ 394 FcwMsgTxt_D_Rq 1;
BA_ "U_P708_MY2023_Rx" SG_ 394 FcwMsgTxt_D_Rq 1;
BA_ "U_V713AV_MY2022_Rx" SG_ 394 FcwMsgTxt_D_Rq 1;
BA_ "U_V713N_MY2022_Rx" SG_ 394 FcwMsgTxt_D_Rq 1;
BA_ "U_P708_MY2023_Rx" SG_ 394 AccTGap_D_Dsply 1;
BA_ "U_V713AV_MY2022_Rx" SG_ 394 AccTGap_D_Dsply 1;
BA_ "U_V713N_MY2022_Rx" SG_ 394 AccTGap_D_Dsply 1;
BA_ "GenSigStartValue" SG_ 394 AccTGap_D_Dsply 3;
BA_ "U_V710_MY2023_Rx" SG_ 394 AccMemEnbl_B_RqDrv 1;
BA_ "U_P708_MY2023_Rx" SG_ 394 AccMemEnbl_B_RqDrv 1;
BA_ "U_V713AV_MY2022_Rx" SG_ 394 AccMemEnbl_B_RqDrv 1;
BA_ "U_V713N_MY2022_Rx" SG_ 394 AccMemEnbl_B_RqDrv 1;
BA_ "GenSigStartValue" SG_ 394 AccMemEnbl_B_RqDrv 1;
BA_ "U_V710_MY2023_Rx" SG_ 394 HaDsply_No_Cs 1;
BA_ "U_P708_MY2023_Rx" SG_ 394 HaDsply_No_Cs 1;
BA_ "MetaData" SG_ 394 HaDsply_No_Cs 1;
BA_ "U_P708_MY2023_Rx" SG_ 394 AccWarn_D_Dsply 1;
BA_ "U_V713AV_MY2022_Rx" SG_ 394 AccWarn_D_Dsply 1;
BA_ "U_V713N_MY2022_Rx" SG_ 394 AccWarn_D_Dsply 1;
BA_ "U_V710_MY2023_Rx" SG_ 394 FcwVisblWarn_B_Rq 1;
BA_ "U_P708_MY2023_Rx" SG_ 394 FcwVisblWarn_B_Rq 1;
BA_ "U_V713AV_MY2022_Rx" SG_ 394 FcwVisblWarn_B_Rq 1;
BA_ "U_V713N_MY2022_Rx" SG_ 394 FcwVisblWarn_B_Rq 1;
BA_ "U_V710_MY2023_Rx" SG_ 394 FcwAudioWarn_B_Rq 1;
BA_ "U_P708_MY2023_Rx" SG_ 394 FcwAudioWarn_B_Rq 1;
BA_ "U_V713AV_MY2022_Rx" SG_ 394 FcwAudioWarn_B_Rq 1;
BA_ "U_V713N_MY2022_Rx" SG_ 394 FcwAudioWarn_B_Rq 1;
BA_ "U_V710_MY2023_Rx" SG_ 1068 TrlrAidMsgTxt_D_Rq 1;
BA_ "U_V713AV_MY2022_Rx" SG_ 1068 TrlrAidMsgTxt_D_Rq 1;
BA_ "U_V713N_MY2022_Rx" SG_ 1068 TrlrAidMsgTxt_D_Rq 1;
BA_ "GenSigSendType" SG_ 1068 TrlrAidMsgTxt_D_Rq 3;
BA_ "U_V710_MY2023_Tx" SG_ 1019 PersIndexIpc_D_Actl 1;
BA_ "U_P708_MY2023_Tx" SG_ 1019 PersIndexIpc_D_Actl 1;
BA_ "U_V713AV_MY2022_Tx" SG_ 1019 PersIndexIpc_D_Actl 1;
BA_ "U_V713N_MY2022_Tx" SG_ 1019 PersIndexIpc_D_Actl 1;
BA_ "GenSigSendType" SG_ 1019 PersIndexIpc_D_Actl 3;
BA_ "GenSigStartValue" SG_ 1019 PersIndexIpc_D_Actl 4;
BA_ "U_V710_MY2023_Tx" SG_ 1019 FeatNoIpcActl 1;
BA_ "U_P708_MY2023_Tx" SG_ 1019 FeatNoIpcActl 1;
BA_ "U_V713AV_MY2022_Tx" SG_ 1019 FeatNoIpcActl 1;
BA_ "U_V713N_MY2022_Tx" SG_ 1019 FeatNoIpcActl 1;
BA_ "GenSigSendType" SG_ 1019 FeatNoIpcActl 3;
BA_ "U_V710_MY2023_Tx" SG_ 1019 FeatConfigIpcActl 1;
BA_ "U_P708_MY2023_Tx" SG_ 1019 FeatConfigIpcActl 1;
BA_ "U_V713AV_MY2022_Tx" SG_ 1019 FeatConfigIpcActl 1;
BA_ "U_V713N_MY2022_Tx" SG_ 1019 FeatConfigIpcActl 1;
BA_ "GenSigSendType" SG_ 1019 FeatConfigIpcActl 3;
BA_ "U_V710_MY2023_Rx" SG_ 909 IgnPsswrdDsply_B_Rq 1;
BA_ "U_V713AV_MY2022_Rx" SG_ 909 IgnPsswrdDsply_B_Rq 1;
BA_ "U_V713N_MY2022_Rx" SG_ 909 IgnPsswrdDsply_B_Rq 1;
BA_ "WakeupSignal" SG_ 909 IgnPsswrdDsply_B_Rq 1;
BA_ "WakeupSignal" SG_ 909 ElPwPoint_D_Rq 1;
BA_ "U_V710_MY2023_Rx" SG_ 909 PoliceIdlMde_D_Stat 1;
BA_ "U_V713AV_MY2022_Rx" SG_ 909 PoliceIdlMde_D_Stat 1;
BA_ "U_V713N_MY2022_Rx" SG_ 909 PoliceIdlMde_D_Stat 1;
BA_ "U_P708_MY2023_Rx" SG_ 909 DrLatchMsgTxt_D_Rq 1;
BA_ "U_V713AV_MY2022_Rx" SG_ 909 DrLatchMsgTxt_D_Rq 1;
BA_ "U_V713N_MY2022_Rx" SG_ 909 DrLatchMsgTxt_D_Rq 1;
BA_ "GenSigStartValue" SG_ 909 WiprFront_D_Stat2 15;
BA_ "WakeupSignal" SG_ 909 HazrdLght_B_Stat 1;
BA_ "U_P708_MY2023_Rx" SG_ 909 TurnLghtSwtch_D_Stat2 1;
BA_ "U_V713AV_MY2022_Rx" SG_ 909 TurnLghtSwtch_D_Stat2 1;
BA_ "U_V713N_MY2022_Rx" SG_ 909 TurnLghtSwtch_D_Stat2 1;
BA_ "GenSigStartValue" SG_ 909 HeadLghtHiPrmsn_D_Stat 3;
BA_ "U_V710_MY2023_Rx" SG_ 909 SteWhlLckMsgTxt_D_Rq 1;
BA_ "U_V713AV_MY2022_Rx" SG_ 909 SteWhlLckMsgTxt_D_Rq 1;
BA_ "U_V713N_MY2022_Rx" SG_ 909 SteWhlLckMsgTxt_D_Rq 1;
BA_ "U_V710_MY2023_Rx" SG_ 909 immoMsgTxt_D_Rq 1;
BA_ "U_V713AV_MY2022_Rx" SG_ 909 immoMsgTxt_D_Rq 1;
BA_ "U_V713N_MY2022_Rx" SG_ 909 immoMsgTxt_D_Rq 1;
BA_ "WakeupSignal" SG_ 909 immoMsgTxt_D_Rq 1;
BA_ "U_V710_MY2023_Rx" SG_ 909 PrsnlDevcChrgEnbl_B_Rq 1;
BA_ "WakeupSignal" SG_ 909 PrsnlDevcChrgEnbl_B_Rq 1;
BA_ "U_P708_MY2023_Rx" SG_ 909 TracKeyMde_D_Stat 1;
BA_ "U_V713AV_MY2022_Rx" SG_ 909 TracKeyMde_D_Stat 1;
BA_ "U_V713N_MY2022_Rx" SG_ 909 TracKeyMde_D_Stat 1;
BA_ "U_V710_MY2023_Rx" SG_ 909 Keycode_Status 1;
BA_ "U_V713AV_MY2022_Rx" SG_ 909 Keycode_Status 1;
BA_ "U_V713N_MY2022_Rx" SG_ 909 Keycode_Status 1;
BA_ "U_V710_MY2023_Rx" SG_ 909 PEBackupSlot_Stats 1;
BA_ "U_V713AV_MY2022_Rx" SG_ 909 PEBackupSlot_Stats 1;
BA_ "U_V713N_MY2022_Rx" SG_ 909 PEBackupSlot_Stats 1;
BA_ "U_V710_MY2023_Rx" SG_ 909 KeyMykeyTot_No_Cnt 1;
BA_ "U_V713AV_MY2022_Rx" SG_ 909 KeyMykeyTot_No_Cnt 1;
BA_ "U_V713N_MY2022_Rx" SG_ 909 KeyMykeyTot_No_Cnt 1;
BA_ "MetaData" SG_ 909 KeyMykeyTot_No_Cnt 1;
BA_ "U_V710_MY2023_Rx" SG_ 909 KeyAdmnTot_No_Cnt 1;
BA_ "U_V713AV_MY2022_Rx" SG_ 909 KeyAdmnTot_No_Cnt 1;
BA_ "U_V713N_MY2022_Rx" SG_ 909 KeyAdmnTot_No_Cnt 1;
BA_ "MetaData" SG_ 909 KeyAdmnTot_No_Cnt 1;
BA_ "U_V710_MY2023_Rx" SG_ 1824 TesterPhysicalReqIPC 1;
BA_ "U_P708_MY2023_Rx" SG_ 1824 TesterPhysicalReqIPC 1;
BA_ "U_V713AV_MY2022_Rx" SG_ 1824 TesterPhysicalReqIPC 1;
BA_ "U_V713N_MY2022_Rx" SG_ 1824 TesterPhysicalReqIPC 1;
BA_ "GenSigSendType" SG_ 1824 TesterPhysicalReqIPC 3;
VAL_ 516 EngAoutNActl_D_QF 3 "OK" 2 "Not_Within_Specifications" 1 "No_Data_Exists" 0 "Faulty" ;
VAL_ 516 ApedPos_PcRate_ActlArb 255 "Fault" 254 "Unknown" ;
VAL_ 516 ApedPosPcActl_D_Qf 3 "OK" 2 "Not_Within_Specifications" 1 "No_Data_Exists" 0 "Faulty" ;
VAL_ 516 EngAout3_N_Actl 65535 "Invalid" ;
VAL_ 514 VehVTrlrAid_B_Avail 1 "Yes" 0 "No" ;
VAL_ 514 StrtrMtrCtlMsgTxt_D_Rq 7 "Start_In_Gear_Allowed" 6 "Pending_Start_Cancelled" 5 "Start_Pending_Please_Wait" 4 "Cranking_Limit_Exceeded" 3 "Press_Brk_and_Shift_to_P_N" 2 "Press_Clutch_and_Brake" 1 "Press_Clutch_To_Start" 0 "No_Display" ;
VAL_ 514 GearRvrse_D_Actl 7 "Fault" 6 "NotUsed_3" 5 "NotUsed_2" 4 "NotUsed_1" 3 "Active_confirmed" 2 "Active_not_confirmed" 1 "Inactive_confirmed" 0 "Inactive_not_confirmed" ;
VAL_ 514 VehVActlEng_D_Qf 3 "OK" 2 "Not_Within_Specifications" 1 "No_Data_Exists" 0 "Faulty" ;
VAL_ 514 StrtrMtrDlyStrt_B_Stat 1 "Yes" 0 "No" ;
VAL_ 514 StrtrMtrCtlMsgTxt_D2_Rq 3 "NoRequestPcmStartingMsgCtl" 2 "ShiftToNeutralToStart" 1 "ShiftToParkToStart" 0 "NoRequestBcmStartingMsgCtl" ;
VAL_ 381 EngOilSrvcMsgTxt_D_Rq 7 "NotUsed_1" 6 "OilMinderNotConfigured" 5 "ResetFailed" 4 "ResetComplete" 3 "ResetInProgress" 2 "ChangeOilNow" 1 "ChangeOilSoon" 0 "NoText" ;
VAL_ 381 RunDryPrevent_B_Stat 1 "True" 0 "False" ;
VAL_ 381 WaterInFuel 1 "On" 0 "Off" ;
VAL_ 381 GlowIndication 1 "On" 0 "Off" ;
VAL_ 380 FuelMaintMde_D_Rq 3 "Feature_Not_Present" 2 "Fuel_Maint_Req_Now" 1 "Fuel_Maint_Req_Soon" 0 "NoRequest" ;
VAL_ 380 PwStep_D_DrvInhbt 3 "NotUsed" 2 "DriveInhibitMalfunction" 1 "DriveInhibited" 0 "DriveNotInhibited" ;
VAL_ 380 GrdAsstAllw_D_DsplyPt 3 "NotUsed" 2 "On" 1 "Off" 0 "NoModeSelected" ;
VAL_ 380 EngOilLvlWarn_D_Rq1 7 "Undefined_3" 6 "Undefined_2" 5 "Engine_Oil_Monitor_Fault" 3 "Engine_Oil_High" 2 "Engine_Oil_Critical_Low" 1 "Engine_Oil_Low" 0 "No_Message" 4 "Engine_Oil_Critical_High" ;
VAL_ 380 EngExhBrkOnLamp_B_Rq 1 "On" 0 "Off" ;
VAL_ 380 EngExhBrkAutoLamp_B_Rq 1 "On" 0 "Off" ;
VAL_ 380 EngExhBrkMde_D_Actl 6 "ExhBrkDisable_NoError" 5 "ExhBrkActive_AUTO" 4 "ExhBrkActive_ON" 3 "ExhBrkRequest_AUTO" 2 "ExhBrkRequest_ON" 1 "ExhBrkNoRequest_OFF" 0 "ExhBrkUnavailable_Error" ;
VAL_ 380 WhlRearDual_D_Stat 3 "NotUsed" 2 "Dual" 1 "Single" 0 "NoDataExists" ;
VAL_ 377 TrnManShif_D_IndDrv 7 "Undefined_3" 6 "Undefined_2" 5 "Shift_to_Neutral" 4 "Downshift_Recommendation" 3 "Upshift_Warning" 2 "Upshift_Performance" 1 "Upshift_Fuel_Economy" 0 "No_Indication" ;
VAL_ 377 HvacAirFullOut_B_Rq 1 "Yes" 0 "No" ;
VAL_ 377 EngFuelCutFull_B_Inhbt 1 "Inhibit_DFSO" 0 "Normal" ;
VAL_ 377 EngDecelFuelCut_B_Allw 1 "Yes" 0 "No" ;
VAL_ 377 TrnManShifGear_D_IndDrv 7 "Indicate_Reverse_Gear" 6 "Indicate_Gear6" 5 "Indicate_Gear5" 4 "Indicate_Gear4" 3 "Indicate_Gear3" 2 "Indicate_Gear2" 1 "Indicate_Gear1" 0 "No_Indication" ;
VAL_ 377 FuelFillInlet_B_Dsply 1 "Yes" 0 "No" ;
VAL_ 377 EngSrvcRqd_B_Rq 1 "Engine_Service_Required" 0 "No_engine_service_required" ;
VAL_ 377 OdoCount 255 "Invalid" ;
VAL_ 377 TrnKickDown_B_RqDrv 1 "Yes" 0 "No" ;
VAL_ 377 FuelFilterLamp_B_Dsply 1 "On" 0 "Off" ;
VAL_ 377 AirCondRec_B_Rq 1 "Yes" 0 "No" ;
VAL_ 377 AirCondClutch_B_Stats 1 "Yes" 0 "No" ;
VAL_ 377 EngAoutTqActl_D_Qf 3 "OK" 2 "Not_Within_Specifications" 1 "No_Data_Exists" 0 "Faulty" ;
VAL_ 376 GasPrtc_D_RqDsply 7 "NotUsed_5" 6 "NotUsed_4" 5 "NotUsed_3" 4 "NotUsed_2" 3 "NotUsed_1" 2 "GpfOverLimit" 1 "GpfAtLimit" 0 "NormalOperation" ;
VAL_ 376 LnchCtlSys_D_Stat 7 "NotUsed3" 6 "NotUsed2" 5 "NotUsed1" 4 "On_LC_Unavailable_TC_On" 3 "On_LC_Unavailable" 2 "On_LC_Available" 1 "On_LC_Active" 0 "LC_OFF" ;
VAL_ 376 DynoMde_B_Cmd 1 "DynomometerMode" 0 "NormalOperation" ;
VAL_ 376 AslIconDsply_D_Rq 3 "On_Passive_Overridden" 2 "On_Active" 1 "On_Passive" 0 "Off" ;
VAL_ 376 AslChime_B_Rq 1 "Yes" 0 "No" ;
VAL_ 376 PtcHtr_D_Cmd 3 "TurnOn" 2 "AutoMode" 1 "TurnOff" 0 "NoDecision_Initializing" ;
VAL_ 376 HvacHtrCore2_Te_Actl 1023 "Faulty" ;
VAL_ 376 EcssLamp_D_RqDsply 3 "Not_Used" 2 "Flash" 1 "On" 0 "Off" ;
VAL_ 376 AirAmbTe_D_Qf 3 "OK" 2 "Not_Within_Specifications" 1 "No_Data_Exists" 0 "Faulty" ;
VAL_ 376 AirAmb_P_Actl 63 "Fault" 62 "NoDataExists" ;
VAL_ 373 DieslPrtc2_D_RqDsply 15 "NotUsed4" 14 "NotUsed3" 13 "NotUsed2" 12 "NotUsed1" 11 "OCR_ExhFilterClean_Stopped" 10 "OCR_ExhFilterCleaned" 9 "RgnOff_AtLimit" 8 "RgnOff_Overloaded" 7 "RgnOff_Loaded" 6 "Exhaust_Filter_Full" 5 "DPF_Overlimit" 4 "DPF_AtLimit" 3 "ExhFilter_Drive_Completed" 2 "Cleaning_Exhaust_Filter" 1 "DPF_Overloaded" 0 "DPF_Normal_Operation" ;
VAL_ 373 DieslPrtc_D_RqDsply 7 "Unused_2" 6 "Unused_1" 5 "DPF_SOOT_Level3_Blocked" 4 "DPFSootLvl2_SevereOverload" 3 "DPFRegen_ExhFilterComplete" 2 "DPFRegen_CleanExhFilter" 1 "DPF_Soot_Level1_Overloaded" 0 "DPF_OK_Normal_Operation" ;
VAL_ 373 DieslPrtcRgen_D_Actl 3 "Undefined" 2 "Regen_Level_2" 1 "Regen_Level_1" 0 "No_regen" ;
VAL_ 373 DieslPrtcRgen_D_Rq 7 "Unused_2" 6 "Unused_1" 5 "Full_Regen_2" 4 "Full_Regen_1" 3 "HeatUp_3" 2 "HeatUp_2" 1 "HeatUp_1" 0 "Normal_Mode_NoRegen" ;
VAL_ 373 EngFuelCutFull_B_Allw 1 "Yes" 0 "No" ;
VAL_ 373 EngTurboMde_D_Actl 3 "Fault" 2 "One_Turbo_Active" 1 "Two_Turbos_Active" 0 "Initializing" ;
VAL_ 373 EngTeColdPrtct_D_Stats 3 "Engine_Warm_RdcPwr" 2 "OK_to_Drive" 1 "Engine_Warm_PlsWait" 0 "Normal_Operation" ;
VAL_ 373 EngExhOvrTe_B_RqDsply 1 "Active" 0 "Inactive" ;
VAL_ 373 EngPtoMde_D_Rq 7 "Undefined" 6 "Split_Shaft_Stationary" 5 "Not_Used_2" 4 "PTO_Mobile" 3 "Not_Used_1" 2 "PTO_Stationary" 1 "BCP" 0 "Off" ;
VAL_ 355 AccFllwMdeActv_B_Actl 1 "Active" 0 "Inactive" ;
VAL_ 355 AutoRgenTxt_B_RqDsply 1 "AutExhFilterCleanOFF" 0 "AutExhFilterCleanON" ;
VAL_ 355 EngPtoMde_D_Actl 7 "Undefined" 6 "Split_Shaft_Stationary" 5 "Not_Used_2" 4 "PTO_Mobile" 3 "Not_Used_1" 2 "PTO_Stationary" 1 "BCP" 0 "Off" ;
VAL_ 355 ManRgenVeh_V_MinAllw 127 "Fault" ;
VAL_ 355 ManRgenTxt_D_RqDsply 7 "NotUsed3" 6 "NotUsed2" 5 "NotUsed1" 4 "Cleaning_Aborted_Stopped" 3 "Cleaning_Completed" 2 "Cleaning_In_Progress" 1 "Cleaning_Allowed" 0 "Cleaning_Not_Allowed" ;
VAL_ 355 ManRgenSoot_Pc_RqDsply 127 "Fault" ;
VAL_ 355 ManRgenInhbt_T_RqDsply 65535 "Fault" ;
VAL_ 355 ManRgenInhbt_Pc_Soot 127 "Fault" ;
VAL_ 355 DieslMsgTxt_D_Rq 3 "NotUsed2" 2 "NotUsed1" 1 "ReducedEnginePower" 0 "NoMessage" ;
VAL_ 355 ManRgenInhbt_L_RqDsply 65535 "Fault" ;
VAL_ 342 EngTeColdPrtct_B_Rq 1 "On" 0 "Off" ;
VAL_ 342 HtrLoop_B_Stat 1 "Fault" 0 "No_Fault" ;
VAL_ 342 TqmTerrMdeChng_D_Rdy 7 "Fault" 6 "Undefined_2" 5 "Undefined_1" 4 "ModeUnavailDrInputRqd" 3 "SpOpModes_NotSupported" 2 "ModeUnavailDynamicCond" 1 "Module_In_Initialization" 0 "Mode_Change_Available" ;
VAL_ 342 TqmTerrMde_D_Actl 7 "Fail_Safe_Default" 6 "Dynamic_Mode" 5 "Rock_Crawl_Mode" 4 "Mud_Ruts_Mode" 3 "Sand_Mode" 2 "Undefined" 1 "Low_Mu_Mode" 0 "Special_Operating_Mode_Off" ;
VAL_ 342 EngOvrhtMitgActv_D_Ind 3 "Undefined" 2 "Mode2" 1 "Mode1" 0 "Normal_Mode" ;
VAL_ 342 EngClntTe_D_Qf 3 "OK" 2 "Not_Within_Specifications" 1 "No_Data_Exists" 0 "Faulty" ;
VAL_ 342 EngAcsyArcPmp_Tq_Actl 255 "Fault" 254 "Unknown" ;
VAL_ 342 EngOilLvlDsply_D_Rq 15 "EngOil_LevelSys_CheckFault" 14 "Reserved_2" 13 "Reserved_1" 12 "Conditions_Unsuitable" 11 "Dipstick_Below_Minimum" 10 "Dipstick_Above_Maximum" 9 "Dipstick_Minimum" 8 "Dipstick_12_5_MinMaxRange" 7 "Dipstick_25_MinMaxRange" 6 "Dipstick_37_5_MinMaxRange" 5 "Dipstick_50_MinMaxRange" 4 "Dipstick_62_5_MinMaxRange" 3 "Dipstick_75_MinMaxRange" 2 "Dipstick_87_5_MinMaxRange" 1 "Dipstick_Maximum_Displayed" 0 "No_Message" ;
VAL_ 342 EngOil_Te_Actl 255 "Fault" 254 "Unknown" ;
VAL_ 1102 SelDrvMdePos12_D_Stat 31 "Faulty" 30 "SelDrvMde31" 29 "SelDrvMde30" 28 "SelDrvMde29" 27 "SelDrvMde28" 26 "SelDrvMde27" 25 "SelDrvMde26" 24 "SelDrvMde25" 23 "SelDrvMde24" 22 "SelDrvMde23" 21 "SelDrvMde22" 20 "SelDrvMde21" 19 "SelDrvMde20" 18 "SelDrvMde19" 17 "SelDrvMde18" 16 "SelDrvMde17" 15 "SelDrvMde16" 14 "SelDrvMde15" 13 "SelDrvMde14" 12 "SelDrvMde13" 11 "SelDrvMde12" 10 "SelDrvMde11" 9 "SelDrvMde10" 8 "SelDrvMde09" 7 "SelDrvMde08" 6 "SelDrvMde07" 5 "SelDrvMde06" 4 "SelDrvMde05" 3 "SelDrvMde04" 2 "SelDrvMde03" 1 "SelDrvMde02" 0 "SelDrvMde01" ;
VAL_ 1102 SelDrvMdePos11_D_Stat 31 "Faulty" 30 "SelDrvMde31" 29 "SelDrvMde30" 28 "SelDrvMde29" 27 "SelDrvMde28" 26 "SelDrvMde27" 25 "SelDrvMde26" 24 "SelDrvMde25" 23 "SelDrvMde24" 22 "SelDrvMde23" 21 "SelDrvMde22" 20 "SelDrvMde21" 19 "SelDrvMde20" 18 "SelDrvMde19" 17 "SelDrvMde18" 16 "SelDrvMde17" 15 "SelDrvMde16" 14 "SelDrvMde15" 13 "SelDrvMde14" 12 "SelDrvMde13" 11 "SelDrvMde12" 10 "SelDrvMde11" 9 "SelDrvMde10" 8 "SelDrvMde09" 7 "SelDrvMde08" 6 "SelDrvMde07" 5 "SelDrvMde06" 4 "SelDrvMde05" 3 "SelDrvMde04" 2 "SelDrvMde03" 1 "SelDrvMde02" 0 "SelDrvMde01" ;
VAL_ 1102 SelDrvMdePos10_D_Stat 31 "Faulty" 30 "SelDrvMde31" 29 "SelDrvMde30" 28 "SelDrvMde29" 27 "SelDrvMde28" 26 "SelDrvMde27" 25 "SelDrvMde26" 24 "SelDrvMde25" 23 "SelDrvMde24" 22 "SelDrvMde23" 21 "SelDrvMde22" 20 "SelDrvMde21" 19 "SelDrvMde20" 18 "SelDrvMde19" 17 "SelDrvMde18" 16 "SelDrvMde17" 15 "SelDrvMde16" 14 "SelDrvMde15" 13 "SelDrvMde14" 12 "SelDrvMde13" 11 "SelDrvMde12" 10 "SelDrvMde11" 9 "SelDrvMde10" 8 "SelDrvMde09" 7 "SelDrvMde08" 6 "SelDrvMde07" 5 "SelDrvMde06" 4 "SelDrvMde05" 3 "SelDrvMde04" 2 "SelDrvMde03" 1 "SelDrvMde02" 0 "SelDrvMde01" ;
VAL_ 1102 SelDrvMdePos09_D_Stat 31 "Faulty" 30 "SelDrvMde31" 29 "SelDrvMde30" 28 "SelDrvMde29" 27 "SelDrvMde28" 26 "SelDrvMde27" 25 "SelDrvMde26" 24 "SelDrvMde25" 23 "SelDrvMde24" 22 "SelDrvMde23" 21 "SelDrvMde22" 20 "SelDrvMde21" 19 "SelDrvMde20" 18 "SelDrvMde19" 17 "SelDrvMde18" 16 "SelDrvMde17" 15 "SelDrvMde16" 14 "SelDrvMde15" 13 "SelDrvMde14" 12 "SelDrvMde13" 11 "SelDrvMde12" 10 "SelDrvMde11" 9 "SelDrvMde10" 8 "SelDrvMde09" 7 "SelDrvMde08" 6 "SelDrvMde07" 5 "SelDrvMde06" 4 "SelDrvMde05" 3 "SelDrvMde04" 2 "SelDrvMde03" 1 "SelDrvMde02" 0 "SelDrvMde01" ;
VAL_ 1102 SelDrvMdePos08_D_Stat 31 "Faulty" 30 "SelDrvMde31" 29 "SelDrvMde30" 28 "SelDrvMde29" 27 "SelDrvMde28" 26 "SelDrvMde27" 25 "SelDrvMde26" 24 "SelDrvMde25" 23 "SelDrvMde24" 22 "SelDrvMde23" 21 "SelDrvMde22" 20 "SelDrvMde21" 19 "SelDrvMde20" 18 "SelDrvMde19" 17 "SelDrvMde18" 16 "SelDrvMde17" 15 "SelDrvMde16" 14 "SelDrvMde15" 13 "SelDrvMde14" 12 "SelDrvMde13" 11 "SelDrvMde12" 10 "SelDrvMde11" 9 "SelDrvMde10" 8 "SelDrvMde09" 7 "SelDrvMde08" 6 "SelDrvMde07" 5 "SelDrvMde06" 4 "SelDrvMde05" 3 "SelDrvMde04" 2 "SelDrvMde03" 1 "SelDrvMde02" 0 "SelDrvMde01" ;
VAL_ 1102 SelDrvMdePos07_D_Stat 31 "Faulty" 30 "SelDrvMde31" 29 "SelDrvMde30" 28 "SelDrvMde29" 27 "SelDrvMde28" 26 "SelDrvMde27" 25 "SelDrvMde26" 24 "SelDrvMde25" 23 "SelDrvMde24" 22 "SelDrvMde23" 21 "SelDrvMde22" 20 "SelDrvMde21" 19 "SelDrvMde20" 18 "SelDrvMde19" 17 "SelDrvMde18" 16 "SelDrvMde17" 15 "SelDrvMde16" 14 "SelDrvMde15" 13 "SelDrvMde14" 12 "SelDrvMde13" 11 "SelDrvMde12" 10 "SelDrvMde11" 9 "SelDrvMde10" 8 "SelDrvMde09" 7 "SelDrvMde08" 6 "SelDrvMde07" 5 "SelDrvMde06" 4 "SelDrvMde05" 3 "SelDrvMde04" 2 "SelDrvMde03" 1 "SelDrvMde02" 0 "SelDrvMde01" ;
VAL_ 1102 SelDrvMdePos06_D_Stat 31 "Faulty" 30 "SelDrvMde31" 29 "SelDrvMde30" 28 "SelDrvMde29" 27 "SelDrvMde28" 26 "SelDrvMde27" 25 "SelDrvMde26" 24 "SelDrvMde25" 23 "SelDrvMde24" 22 "SelDrvMde23" 21 "SelDrvMde22" 20 "SelDrvMde21" 19 "SelDrvMde20" 18 "SelDrvMde19" 17 "SelDrvMde18" 16 "SelDrvMde17" 15 "SelDrvMde16" 14 "SelDrvMde15" 13 "SelDrvMde14" 12 "SelDrvMde13" 11 "SelDrvMde12" 10 "SelDrvMde11" 9 "SelDrvMde10" 8 "SelDrvMde09" 7 "SelDrvMde08" 6 "SelDrvMde07" 5 "SelDrvMde06" 4 "SelDrvMde05" 3 "SelDrvMde04" 2 "SelDrvMde03" 1 "SelDrvMde02" 0 "SelDrvMde01" ;
VAL_ 1102 SelDrvMdePos05_D_Stat 31 "Faulty" 30 "SelDrvMde31" 29 "SelDrvMde30" 28 "SelDrvMde29" 27 "SelDrvMde28" 26 "SelDrvMde27" 25 "SelDrvMde26" 24 "SelDrvMde25" 23 "SelDrvMde24" 22 "SelDrvMde23" 21 "SelDrvMde22" 20 "SelDrvMde21" 19 "SelDrvMde20" 18 "SelDrvMde19" 17 "SelDrvMde18" 16 "SelDrvMde17" 15 "SelDrvMde16" 14 "SelDrvMde15" 13 "SelDrvMde14" 12 "SelDrvMde13" 11 "SelDrvMde12" 10 "SelDrvMde11" 9 "SelDrvMde10" 8 "SelDrvMde09" 7 "SelDrvMde08" 6 "SelDrvMde07" 5 "SelDrvMde06" 4 "SelDrvMde05" 3 "SelDrvMde04" 2 "SelDrvMde03" 1 "SelDrvMde02" 0 "SelDrvMde01" ;
VAL_ 1102 SelDrvMdePos04_D_Stat 31 "Faulty" 30 "SelDrvMde31" 29 "SelDrvMde30" 28 "SelDrvMde29" 27 "SelDrvMde28" 26 "SelDrvMde27" 25 "SelDrvMde26" 24 "SelDrvMde25" 23 "SelDrvMde24" 22 "SelDrvMde23" 21 "SelDrvMde22" 20 "SelDrvMde21" 19 "SelDrvMde20" 18 "SelDrvMde19" 17 "SelDrvMde18" 16 "SelDrvMde17" 15 "SelDrvMde16" 14 "SelDrvMde15" 13 "SelDrvMde14" 12 "SelDrvMde13" 11 "SelDrvMde12" 10 "SelDrvMde11" 9 "SelDrvMde10" 8 "SelDrvMde09" 7 "SelDrvMde08" 6 "SelDrvMde07" 5 "SelDrvMde06" 4 "SelDrvMde05" 3 "SelDrvMde04" 2 "SelDrvMde03" 1 "SelDrvMde02" 0 "SelDrvMde01" ;
VAL_ 1102 SelDrvMdePos03_D_Stat 31 "Faulty" 30 "SelDrvMde31" 29 "SelDrvMde30" 28 "SelDrvMde29" 27 "SelDrvMde28" 26 "SelDrvMde27" 25 "SelDrvMde26" 24 "SelDrvMde25" 23 "SelDrvMde24" 22 "SelDrvMde23" 21 "SelDrvMde22" 20 "SelDrvMde21" 19 "SelDrvMde20" 18 "SelDrvMde19" 17 "SelDrvMde18" 16 "SelDrvMde17" 15 "SelDrvMde16" 14 "SelDrvMde15" 13 "SelDrvMde14" 12 "SelDrvMde13" 11 "SelDrvMde12" 10 "SelDrvMde11" 9 "SelDrvMde10" 8 "SelDrvMde09" 7 "SelDrvMde08" 6 "SelDrvMde07" 5 "SelDrvMde06" 4 "SelDrvMde05" 3 "SelDrvMde04" 2 "SelDrvMde03" 1 "SelDrvMde02" 0 "SelDrvMde01" ;
VAL_ 1102 SelDrvMdePos02_D_Stat 31 "Faulty" 30 "SelDrvMde31" 29 "SelDrvMde30" 28 "SelDrvMde29" 27 "SelDrvMde28" 26 "SelDrvMde27" 25 "SelDrvMde26" 24 "SelDrvMde25" 23 "SelDrvMde24" 22 "SelDrvMde23" 21 "SelDrvMde22" 20 "SelDrvMde21" 19 "SelDrvMde20" 18 "SelDrvMde19" 17 "SelDrvMde18" 16 "SelDrvMde17" 15 "SelDrvMde16" 14 "SelDrvMde15" 13 "SelDrvMde14" 12 "SelDrvMde13" 11 "SelDrvMde12" 10 "SelDrvMde11" 9 "SelDrvMde10" 8 "SelDrvMde09" 7 "SelDrvMde08" 6 "SelDrvMde07" 5 "SelDrvMde06" 4 "SelDrvMde05" 3 "SelDrvMde04" 2 "SelDrvMde03" 1 "SelDrvMde02" 0 "SelDrvMde01" ;
VAL_ 1102 SelDrvMdePos01_D_Stat 31 "Faulty" 30 "SelDrvMde31" 29 "SelDrvMde30" 28 "SelDrvMde29" 27 "SelDrvMde28" 26 "SelDrvMde27" 25 "SelDrvMde26" 24 "SelDrvMde25" 23 "SelDrvMde24" 22 "SelDrvMde23" 21 "SelDrvMde22" 20 "SelDrvMde21" 19 "SelDrvMde20" 18 "SelDrvMde19" 17 "SelDrvMde18" 16 "SelDrvMde17" 15 "SelDrvMde16" 14 "SelDrvMde15" 13 "SelDrvMde14" 12 "SelDrvMde13" 11 "SelDrvMde12" 10 "SelDrvMde11" 9 "SelDrvMde10" 8 "SelDrvMde09" 7 "SelDrvMde08" 6 "SelDrvMde07" 5 "SelDrvMde06" 4 "SelDrvMde05" 3 "SelDrvMde04" 2 "SelDrvMde03" 1 "SelDrvMde02" 0 "SelDrvMde01" ;
VAL_ 551 PrkBrkPerfMnuOn_D_Stat 3 "Faulty" 2 "NotUsed" 1 "On" 0 "Off" ;
VAL_ 551 PrkBrkPerfButtn_D_Stat 3 "Faulty" 2 "NotUsed" 1 "Pressed" 0 "Not_Pressed" ;
VAL_ 551 EcoIdl_D_Rq 3 "NotUsed" 2 "Enabled" 1 "Disabled" 0 "Null" ;
VAL_ 551 Rba_D_Rq 3 "NotUsed" 2 "On" 1 "Off" 0 "Null" ;
VAL_ 551 OneTEditActv_B_RqMnu 1 "Yes" 0 "No" ;
VAL_ 551 ChrgToPcEdit_Pc_RqMnu 127 "Faulty" 126 "NoDataExists" ;
VAL_ 551 PrcondEdit_D_RqMnu 7 "NotUsed_3" 6 "NotUsed_2" 5 "NotUsed_1" 4 "High" 3 "Medium" 2 "Low" 1 "Off" 0 "Null" ;
VAL_ 551 BattTracLoThres_D_Rq 7 "NotUsed" 6 "Thres80km_50mi" 5 "Thres50km_31mi" 4 "Thres30km_18mi" 3 "Thres50mi_80km" 2 "Thres30mi_48km" 1 "Thres20mi_32km" 0 "Null" ;
VAL_ 551 EmPrflNo_D_Rq 7 "NotUsed_3" 6 "NotUsed_2" 5 "NotUsed_1" 4 "Pers4" 3 "Pers3" 2 "Pers2" 1 "Pers1" 0 "Null" ;
VAL_ 551 EmPrflButtnAssoc_D_Rq 3 "NotUsed" 2 "ExitButtonAssociation" 1 "EnterButtonAssociation" 0 "Null" ;
VAL_ 551 EmPrflKeyAssoc_D_Rq 7 "NotUsed_3" 6 "DisassociatePhone" 5 "EnterPhoneAssociation" 4 "OverwriteKey" 3 "DisassociateKey" 2 "ExitKeyAssociation" 1 "EnterKeyAssociation" 0 "Null" ;
VAL_ 551 Em_D_Stat 3 "NotSupported" 2 "ProfilesOff" 1 "ProfilesOn" 0 "Null" ;
VAL_ 551 PmCabnLvl_D_Stat 7 "NotUsed_1" 6 "Level_6_Worst" 5 "Level_5" 4 "Level_4" 3 "Level_3" 2 "Level_2" 1 "Level_1_Best" 0 "NotKnown" ;
VAL_ 551 PmCabn_D_Stat 3 "FilteringComplete" 2 "FilteringOn" 1 "FilteringOff" 0 "NotKnown" ;
VAL_ 551 Cntr_Plg_Mode_Cmd 1 "Enable" 0 "Disable" ;
VAL_ 551 Btt_L_Actl2 127 "Faulty" 126 "NoDataExists" ;
VAL_ 551 ChrgCrdLckEnbl_B_Stat 1 "Enable" 0 "Disable" ;
VAL_ 551 PwRnngBoardT_D_Rq 3 "NotUsed" 2 "Timer2" 1 "Timer1" 0 "Inactive" ;
VAL_ 551 PwRnngBoardMde_D_Rq 0 "Inactive" 1 "Off" 2 "Out" 3 "Auto" ;
VAL_ 551 PwRnngBoardSwtch_D_Rq 3 "NotUsed" 2 "DeployUnlocked" 1 "AlwaysActive" 0 "Inactive" ;
VAL_ 551 ChrgOvrdExitScrn_D_Rq 3 "NotUsed_1" 2 "Request_override" 1 "Do_not_request_override" 0 "Inactive" ;
VAL_ 551 TjaLaneBiasEnbl_D_RqMnu 3 "NotUsed" 2 "Enabled" 1 "Disabled" 0 "Null" ;
VAL_ 673 ICI_Coding_BtnID_D 15 "Idle" 5 "Stuck" 4 "LongEvent" 3 "ShortElapsed" 2 "ShortEvent" 1 "Active" 0 "Inactive" ;
VAL_ 673 ICI_Coding_BtnID_C 15 "Idle" 5 "Stuck" 4 "LongEvent" 3 "ShortElapsed" 2 "ShortEvent" 1 "Active" 0 "Inactive" ;
VAL_ 673 ICI_Coding_BtnID_B 15 "Idle" 5 "Stuck" 4 "LongEvent" 3 "ShortElapsed" 2 "ShortEvent" 1 "Active" 0 "Inactive" ;
VAL_ 673 ICI_Coding_BtnID_A 15 "Idle" 5 "Stuck" 4 "LongEvent" 3 "ShortElapsed" 2 "ShortEvent" 1 "Active" 0 "Inactive" ;
VAL_ 963 Illuminated_Entry_Stat 3 "Invalid" 2 "Unknown" 1 "On" 0 "Off" ;
VAL_ 963 Dr_Courtesy_Light_Stat 3 "Invalid" 2 "Unknown" 1 "On" 0 "Off" ;
VAL_ 963 Courtesy_Delay_Status 3 "Invalid" 2 "Unknown" 1 "On" 0 "Off" ;
VAL_ 963 ImpactEvntFdbck_D_Stat 3 "NotUsed" 2 "EventComplete" 1 "EventInProgress" 0 "Normal" ;
VAL_ 963 WrlssAcsyChrgInhbt_B_Rq 1 "Yes" 0 "No" ;
VAL_ 963 PudLampPsngr_D_Rq 3 "Ramp_Down" 2 "Ramp_Up" 1 "On" 0 "Off" ;
VAL_ 963 HeadLampLoOut_B_Stat 1 "Out" 0 "Null" ;
VAL_ 963 HeadLghtHiFdbck_D_Stat 3 "NotUsed" 2 "Cancel" 1 "Hold" 0 "Allow_Change" ;
VAL_ 963 PrkLightChime_B_Rq 1 "On" 0 "Off" ;
VAL_ 963 TrnNotInPrkChime_B_Rq 1 "On" 0 "Off" ;
VAL_ 963 KeyInIgnWarn_B_Cmd 1 "On" 0 "Off" ;
VAL_ 963 HomeSafeLtChime_B_Rq 1 "On" 0 "Off" ;
VAL_ 963 StopLghtOn_B_Stat 1 "On" 0 "Off" ;
VAL_ 963 RvrseLghtOn_B_Stat 1 "On" 0 "Off" ;
VAL_ 963 PrkLght_D_Stat 3 "Park_Both" 2 "Park_Right" 1 "Park_Left" 0 "Off" ;
VAL_ 963 HeadLghtSwtch_D_Stat 3 "Autolamp" 2 "Headlamp" 1 "Parklamp" 0 "Off" ;
VAL_ 963 HeadLampLoFrOn_B_Stat 1 "Low" 0 "Not_Low" ;
VAL_ 963 HeadLampLoFlOn_B_Stat 1 "Low" 0 "Not_Low" ;
VAL_ 963 HeadLampLoActv_B_Stat 1 "On" 0 "Off" ;
VAL_ 963 Headlamp_On_Wrning_Cmd 1 "On" 0 "Off" ;
VAL_ 963 HeadLghtHiOn_B_Stat 1 "On" 0 "Off" ;
VAL_ 963 Park_Brake_Chime_Rqst 1 "On" 0 "Off" ;
VAL_ 963 BrkWarnInd_B_Rq 1 "On" 0 "Off" ;
VAL_ 963 Brk_Fluid_Lvl_Low 3 "Invalid" 2 "Unknown" 1 "Low" 0 "OK" ;
VAL_ 963 ReducedGuard_D_Stat 3 "NotUsed" 2 "Alarm_On" 1 "Alarm_Off_Previously_On" 0 "Alarm_Off" ;
VAL_ 963 PudLampDrv_D_Rq 3 "Ramp_Down" 2 "Ramp_Up" 1 "On" 0 "Off" ;
VAL_ 963 Courtesy_BSave_Stat 3 "Invalid" 2 "Unknown" 1 "No_Effect" 0 "Off" ;
VAL_ 963 DayRnngLampOn_B_Stat 1 "On" 0 "Off" ;
VAL_ 963 PerimeterAlarmChimeRq 1 "On" 0 "Off" ;
VAL_ 963 Perimeter_Alarm_Status 3 "Activated" 2 "Armed" 1 "Prearmed" 0 "Disarmed" ;
VAL_ 963 WndwGlbl_D_Cmd 7 "NotUsed3" 6 "NotUsed2" 5 "NotUsed1" 4 "GLEARN" 3 "GCLOSE" 2 "GOPEN" 1 "GSTOP" 0 "Null" ;
VAL_ 963 DrTgateLck_D_Stat 3 "NotUsed" 2 "Unlock" 1 "Lock" 0 "Null" ;
VAL_ 963 PudLamp_D_Rq 3 "RAMP_DOWN" 2 "RAMP_UP" 1 "ON" 0 "OFF" ;
VAL_ 949 Tire_Press_RR_ORR_Data 65535 "Not_Supported" 65534 "Invalid" 65533 "Unknown" ;
VAL_ 949 Tire_Press_LR_OLR_Data 65535 "Not_Supported" 65534 "Invalid" 65533 "Unknown" ;
VAL_ 949 Tire_Press_LF_Data 65535 "Not_Supported" 65534 "Invalid" 65533 "Unknown" ;
VAL_ 949 Tire_Press_RF_Data 65535 "Not_Supported" 65534 "Invalid" 65533 "Unknown" ;
VAL_ 1076 AutoRgen_D_Rq 3 "NotUsed" 2 "AutExhFilterCleanOFF" 1 "AutExhFilterCleanON" 0 "No_Mode_Selected" ;
VAL_ 1076 W2S_LAMP_OK 1 "Yes" 0 "No" ;
VAL_ 1076 OdoTripRx_B_Actl 1 "Yes" 0 "No" ;
VAL_ 1076 DrvSlipCtlMde_B_RqMyKey 1 "On" 0 "Off" ;
VAL_ 1076 FuelLvlWarn_D_Actl 3 "NotUsed" 2 "VeryLow" 1 "Low" 0 "OK" ;
VAL_ 1076 DieslFuelBio_B_ActlDrv 1 "Biodiesel_User" 0 "Non_Biodiesel_User" ;
VAL_ 1076 FuelSecndActv_B_Actl 1 "Yes" 0 "No" ;
VAL_ 1076 HILL_DESC_SW 1 "On" 0 "Off" ;
VAL_ 1076 FUEL_SENSOR_NUM 1 "Dual_Sensors" 0 "Single_Sensor" ;
VAL_ 1076 TirePReset_B_Rq 1 "Reset" 0 "Null" ;
VAL_ 974 PwBedPnlEnblScnd_B_Rq 1 "Enable" 0 "Disable" ;
VAL_ 974 DcacSysScnd_B_Falt 1 "Yes" 0 "No" ;
VAL_ 974 DcacOnScnd_B_Rq 1 "Enable" 0 "Disable" ;
VAL_ 974 DcacGfciTestScnd_B_Rq 1 "Pressed" 0 "Not_Pressed" ;
VAL_ 974 DcacGfciTest_B_Rq 1 "Pressed" 0 "Not_Pressed" ;
VAL_ 974 EngExhMdeHrStrt_D_Stat 31 "NotUsed_7" 30 "NotUsed_6" 29 "NotUsed_5" 28 "NotUsed_4" 27 "NotUsed_3" 26 "NotUsed_2" 25 "NotUsed_1" 24 "Hour23_11pm" 23 "Hour22_10pm" 22 "Hour21_9pm" 21 "Hour20_8pm" 20 "Hour19_7pm" 19 "Hour18_6pm" 18 "Hour17_5pm" 17 "Hour16_4pm" 16 "Hour15_3pm" 15 "Hour14_2pm" 14 "Hour13_1pm" 13 "Hour12_12pm" 12 "Hour11_11am" 11 "Hour10_10am" 10 "Hour9_9am" 9 "Hour8_8am" 8 "Hour7_7am" 7 "Hour6_6am" 6 "Hour5_5am" 5 "Hour4_4am" 4 "Hour3_3am" 3 "Hour2_2am" 2 "Hour1_1am" 1 "Hour0_12am" 0 "Null" ;
VAL_ 974 EngExhMdeHrEnd_D_Stat 31 "NotUsed_7" 30 "NotUsed_6" 29 "NotUsed_5" 28 "NotUsed_4" 27 "NotUsed_3" 26 "NotUsed_2" 25 "NotUsed_1" 24 "Hour23_11pm" 23 "Hour22_10pm" 22 "Hour21_9pm" 21 "Hour20_8pm" 20 "Hour19_7pm" 19 "Hour18_6pm" 18 "Hour17_5pm" 17 "Hour16_4pm" 16 "Hour15_3pm" 15 "Hour14_2pm" 14 "Hour13_1pm" 13 "Hour12_12pm" 12 "Hour11_11am" 11 "Hour10_10am" 10 "Hour9_9am" 9 "Hour8_8am" 8 "Hour7_7am" 7 "Hour6_6am" 6 "Hour5_5am" 5 "Hour4_4am" 4 "Hour3_3am" 3 "Hour2_2am" 2 "Hour1_1am" 1 "Hour0_12am" 0 "Null" ;
VAL_ 974 EngExhMdeHrEnbl_D_Stat 3 "NotUsed" 2 "Enabled" 1 "Disabled" 0 "Null" ;
VAL_ 974 DcacOut_Pw_DsplyMx 1023 "Faulty" ;
VAL_ 974 DcacOut1_Pw_Dsply 63 "Faulty" ;
VAL_ 974 DcacOut2_Pw_Dsply 63 "Faulty" ;
VAL_ 974 DcacHw_D_Confg 15 "NotUsed_11" 14 "NotUsed_10" 13 "NotUsed_9" 12 "NotUsed_8" 11 "NotUsed_7" 10 "NotUsed_6" 9 "NotUsed_5" 8 "NotUsed_4" 7 "NotUsed_3" 6 "NotUsed_2" 5 "Dual_2400WAnd7200W" 4 "Power_2300W" 3 "Power_7200W" 2 "Power_2400W" 1 "Power_2000W" 0 "NoDcacHardware" ;
VAL_ 974 DcacFaltMsgTxt_D_Rq 15 "HvacOn" 14 "OvercurrentLP" 13 "EngineRun" 12 "Service" 11 "NotAvailable" 10 "PlugWarn" 9 "PlugWarnDrive" 8 "BreakerC" 7 "BreakerB" 6 "BreakerA" 5 "FuelLow" 4 "AcOnOutput" 3 "Temperature" 2 "Gfci" 1 "Overcurrent" 0 "Ok" ;
VAL_ 974 DcacLoFuelMsgTxt_D_Rq 31 "Minute_31" 30 "Minute_30" 29 "Minute_29" 28 "Minute_28" 27 "Minute_27" 26 "Minute_26" 25 "Minute_25" 24 "Minute_24" 23 "Minute_23" 22 "Minute_22" 21 "Minute_21" 20 "Minute_20" 19 "Minute_19" 18 "Minute_18" 17 "Minute_17" 16 "Minute_16" 15 "Minute_15" 14 "Minute_14" 13 "Minute_13" 12 "Minute_12" 11 "Minute_11" 10 "Minute_10" 9 "Minute_9" 8 "Minute_8" 7 "Minute_7" 6 "Minute_6" 5 "Minute_5" 4 "Minute_4" 3 "Minute_3" 2 "Minute_2" 1 "Minute_1" 0 "Ok" ;
VAL_ 974 DcacEngOnMsgTxt_D_Rq 3 "NotUsed" 2 "DisplayQuestion" 1 "DisplayWarning" 0 "Ok" ;
VAL_ 974 DcacElPw_D_Stat 3 "NotUsed" 2 "High" 1 "Low" 0 "Off" ;
VAL_ 974 PwBedPnlEnbl_B_Rq 1 "Enable" 0 "Disable" ;
VAL_ 974 DcacOn_B_Rq 1 "Enable" 0 "Disable" ;
VAL_ 974 DcacSys_B_Falt 1 "Yes" 0 "No" ;
VAL_ 974 DcacLedCtl_D_Rq 3 "Fast_Flash" 2 "Slow_Flash" 1 "On" 0 "Off" ;
VAL_ 810 OneTEditActv_B_RqCld 1 "Yes" 0 "No" ;
VAL_ 810 ExtLghtDsply_B_StatArb 1 "On" 0 "Off" ;
VAL_ 552 ActvNseMute_D_Stat 3 "NotUsed_1" 2 "Muted" 1 "NotMuted" 0 "Inactive" ;
VAL_ 552 DSP_VoiceFBVolume_Up 1 "Update" 0 "NoUpdate" ;
VAL_ 552 DSP_TAVolume_Up 1 "Update" 0 "NoUpdate" ;
VAL_ 552 DSP_Shaker_St 1 "Active" 0 "Inactive" ;
VAL_ 552 DSP_Reg_St 0 "Invalid" 1 "Off" 2 "On" ;
VAL_ 552 DSP_PhoneVolume_Up 1 "Update" 0 "NoUpdate" ;
VAL_ 552 DSP_NavCmdVolume_Up 1 "Update" 0 "NoUpdate" ;
VAL_ 552 DSP_DSPProgram_St 7 "Reserved2" 6 "Reserved1" 5 "Voice" 4 "Rock" 0 "Invalid" 1 "Normal" 2 "Pop" 3 "Classical" ;
VAL_ 552 DSP_DSP_St 0 "Invalid" 1 "All" 2 "Driver" 3 "Passenger" 4 "Pop" 5 "Classical" 6 "Rock" ;
VAL_ 552 Audio_Demo_Status 1 "Active" 0 "Inactive" ;
VAL_ 967 NfcMyKeyCreate_D_Stat 3 "KeyAlreadyMyKey" 2 "TapTimeOut" 1 "TapNfcCard" 0 "Null" ;
VAL_ 967 CamZoomActiveState 3 "Not_Used" 2 "Inactive" 1 "Active" 0 "Invalid" ;
VAL_ 967 CamraViewSplit_D_Actl 3 "NotUsed" 2 "Inactive" 1 "Active" 0 "Invalid" ;
VAL_ 967 CamraOvrlTow_D_Actl 3 "Not_Used" 2 "Inactive" 1 "Active" 0 "Invalid" ;
VAL_ 967 CamraZoomMan_D_Actl 7 "Unknown" 6 "Invalid" 5 "Zoom_Level_V" 4 "Zoom_Level_IV" 3 "Zoom_Level_III" 2 "Zoom_Level_II" 1 "Zoom_Level_I" 0 "Off" ;
VAL_ 967 CamraOvrlStat_D_Actl 3 "Not_Used" 2 "Inactive" 1 "Active" 0 "Invalid" ;
VAL_ 967 CamraOvrlDyn_D_Actl 3 "Not_Used" 2 "Inactive" 1 "Active" 0 "Invalid" ;
VAL_ 967 CamPDCGuidStat 3 "Not_Used" 2 "Inactive" 1 "Active" 0 "Invalid" ;
VAL_ 1105 ClrExitAsstActv_B_Rq 1 "Active" 0 "Inactive" ;
VAL_ 1105 ClrExitAsstMsgTxt2_D_Rq 15 "NotUsed_7" 14 "NotUsed_6" 13 "NotUsed_5" 12 "NotUsed_4" 11 "NotUsed_3" 10 "NotUsed_2" 9 "NotUsed_1" 8 "FrontLeftRearRight" 7 "RearLeftFrontRight" 6 "FrontLeftFrontRight" 5 "RearLeftRearRight" 4 "FrontRight" 3 "FrontLeft" 2 "RearRight" 1 "RearLeft" 0 "NoMessage" ;
VAL_ 1105 TrlrRvrseEnbl_D2_Stat 7 "NotUsed" 6 "TbaActiveExpertActive" 5 "TbaActiveExpertAvail" 4 "TbaOffTrgActive" 3 "TbaOffTrgSetup" 2 "TbaSetup" 1 "TbaActive" 0 "Inactive" ;
VAL_ 1105 TrlrAidSwtchLamp_B_Rq 1 "On" 0 "Off" ;
VAL_ 1105 TrlrAidEnbl_D_RqAdas 7 "NotUsed_4" 6 "NotUsed_3" 5 "NotUsed_2" 4 "NotUsed_1" 3 "Deactivate" 2 "NotAvailable" 1 "ActiveTba" 0 "Inactive" ;
VAL_ 1105 TrlrHitchMsgTxt_D_Rq 31 "Message31" 30 "Message30" 29 "Message29" 28 "Message28" 27 "Message27" 26 "Message26" 25 "Message25" 24 "Message24" 23 "Message23" 22 "Message22" 21 "Message21" 20 "Message20" 19 "Message19" 18 "Message18" 17 "Message17" 16 "Message16" 15 "Message15" 14 "Message14" 13 "Message13" 12 "Message12" 11 "Message11" 10 "Message10" 9 "Message9" 8 "Message8" 7 "Message7" 6 "Message6" 5 "Message5" 4 "Message4" 3 "Message3" 2 "Message2" 1 "Message1" 0 "NoMessage" 63 "Message63" 47 "Message47" ;
VAL_ 1105 TrlrHitchIcon_D_Rq 15 "Icon15" 14 "Icon14" 13 "Icon13" 12 "Icon12" 11 "Icon11" 10 "Icon10" 9 "Icon9" 8 "Icon8" 7 "Icon7" 6 "Icon6" 5 "Icon5" 4 "Icon4" 3 "Icon3" 2 "Icon2" 1 "Icon1" 0 "NoIcon" ;
VAL_ 1105 CamraFrntOffRd_B_Stat 1 "Active" 0 "Inactive" ;
VAL_ 1105 TrlrHitchChime_D_Rq 7 "NotUsed_1" 6 "NotUsed_1" 5 "WarningChime" 4 "NonCriticalAlertChime" 3 "StopNowChime" 2 "ManeuveringReadyChime" 1 "TrailerFoundChime" 0 "NoChime" ;
VAL_ 1105 TrlrRvrseMsgTxt_D2_Rq 31 "Message31" 30 "Message30" 29 "Message29" 28 "Message28" 27 "Message27" 26 "Message26" 25 "Message25" 24 "Message24" 23 "Message23" 22 "Message22" 21 "Message21" 20 "Message20" 19 "Message19" 18 "Message18" 17 "Message17" 16 "Message16" 15 "Message15" 14 "Message14" 13 "Message13" 12 "Message12" 11 "Message11" 10 "Message10" 9 "Message9" 8 "Message8" 7 "Message7" 6 "Message6" 5 "Message5" 4 "Message4" 3 "Message3" 2 "Message2" 1 "Message1" 0 "NoMessage" 63 "Message63" 47 "Message47" ;
VAL_ 1105 RbaMsg_D_Rq 3 "Faulty" 2 "Unavailable" 1 "Off" 0 "Null" ;
VAL_ 1105 BrkDecel_B_RqRba 1 "Enable" 0 "Disable" ;
VAL_ 1105 BrkEnbl_B_RqRba 1 "Enable" 0 "Disable" ;
VAL_ 1105 Rba_D_Stat 3 "NotUsed" 2 "Disabled" 1 "On" 0 "Off" ;
VAL_ 1105 RbaAlrt_D_Dsply 3 "Both" 2 "Text" 1 "Graphic" 0 "Off" ;
VAL_ 1105 RbaMnu_D_Rq 3 "NotUsed" 2 "Active" 1 "Inactive" 0 "None" ;
VAL_ 1105 CamraFrntStat_D_Stat 3 "No_Data_Present" 2 "NotUsed" 1 "On" 0 "Off" ;
VAL_ 1105 TrlrHitchLamp_D_Rq2 1 "On" 0 "Off" ;
VAL_ 867 LHS_Temp_Disp_Digit3 2 "_5" 1 "_0" 0 "OFF" ;
VAL_ 867 Front_Blower_Ind 15 "Display_Blank" 14 "14_Indicators_On" 13 "13_Indicators_On" 12 "12_Indicators_On" 11 "11_Indicators_On" 10 "10_Indicators_On" 9 "9_Indicators_On" 8 "8_Indicators_On" 7 "7_Indicators_On" 6 "6_Indicators_On" 5 "5_Indicators_On" 4 "4_Indicators_On" 3 "3_Indicators_On" 2 "2_Indicators_On" 1 "1_Indicator_On" 0 "Indicators_Off" ;
VAL_ 867 EATC_LHS_Unit 2 "Fahrenheit" 1 "Celsius" 0 "Off" ;
VAL_ 866 SnowPlowOn_B_Rq 1 "On" 0 "Off" ;
VAL_ 866 Frt_Blower_Speed2 15 "NotUsed_6" 14 "NotUsed_5" 13 "NotUsed_4" 12 "NotUsed_3" 11 "NotUsed_2" 10 "Zero_Blower" 9 "Max_Blower" 8 "Min_Blower" 7 "Blower_Speed_7" 6 "Blower_Speed_6" 5 "Blower_Speed_5" 4 "Blower_Speed_4" 3 "Blower_Speed_3" 2 "Blower_Speed_2" 1 "Blower_Speed_1" 0 "No_Request" ;
VAL_ 866 Psngr_Set_Temp 31 "HI" 30 "_29_5" 29 "_29_0" 28 "_28_5" 27 "_28_0" 26 "_27_5" 25 "_27_0" 24 "_26_5" 23 "_26_0" 22 "_25_5" 21 "_25_0" 20 "_24_5" 19 "_24_0" 18 "_23_5" 17 "_23_0" 16 "_22_5" 15 "_22_0" 14 "_21_5" 13 "_21_0" 12 "_20_5" 11 "_20_0" 10 "_19_5" 9 "_19_0" 8 "_18_5" 7 "_18_0" 6 "_17_5" 5 "_17_0" 4 "_16_5" 3 "_16_0" 2 "_15_5" 1 "LO" 0 "No_Request" ;
VAL_ 866 ClimtRearView_D_Stat 3 "ThirdRow" 2 "SecondRow" 1 "Both" 0 "NotDisplayed" ;
VAL_ 866 Voice_Blower_Limit 1 "Request" 0 "NoRequest" ;
VAL_ 866 Rr_Btn_Status_2nd 31 "NotUsed_7" 30 "NotUsed_6" 29 "NotUsed_5" 28 "NotUsed_4" 27 "NotUsed_3" 26 "NotUsed_2" 25 "NotUsed_1" 24 "Third_Sync_Pressed" 23 "Third_Rr_Pwr_Pressed" 22 "Third_Auto_Pressed" 21 "Third_Pnl_Flr_Pressed" 20 "Third_Floor_Pressed" 19 "Third_Panel_Pressed" 18 "Third_Blwr_Dec_Pressed" 17 "Third_Blwr_Inc_Pressed" 16 "Rear_Lock_Pressed" 15 "RHS_Cld_Seat_Pressed" 14 "LHS_Cld_Seat_Pressed" 13 "RHS_Htd_Seat_Pressed" 12 "LHS_Htd_Seat_Pressed" 11 "Rear_Power_Pressed" 10 "AUTO_Pressed" 9 "Blwr_Dec_Pressed" 8 "Blwr_Inc_Pressed" 7 "RHS_Temp_Dec_Pressed" 6 "RHS_Temp_Inc_Pressed" 5 "LHS_Temp_Dec_Pressed" 4 "LHS_Temp_Inc_Pressed" 3 "Floor_Pressed" 2 "Panel_Floor_Pressed" 1 "Panel_Pressed" 0 "None_Pressed" ;
VAL_ 866 Rr_Btn_Status_1st 31 "NotUsed_7" 30 "NotUsed_6" 29 "NotUsed_5" 28 "NotUsed_4" 27 "NotUsed_3" 26 "NotUsed_2" 25 "NotUsed_1" 24 "Third_Sync_Pressed" 23 "Third_Rr_Pwr_Pressed" 22 "Third_Auto_Pressed" 21 "Third_Pnl_Flr_Pressed" 20 "Third_Floor_Pressed" 19 "Third_Panel_Pressed" 18 "Third_Blwr_Dec_Pressed" 17 "Third_Blwr_Inc_Pressed" 16 "Rear_Lock_Pressed" 15 "RHS_Cld_Seat_Pressed" 14 "LHS_Cld_Seat_Pressed" 13 "RHS_Htd_Seat_Pressed" 12 "LHS_Htd_Seat_Pressed" 11 "Rear_Power_Pressed" 10 "AUTO_Pressed" 9 "Blwr_Dec_Pressed" 8 "Blwr_Inc_Pressed" 7 "RHS_Temp_Dec_Pressed" 6 "RHS_Temp_Inc_Pressed" 5 "LHS_Temp_Dec_Pressed" 4 "LHS_Temp_Inc_Pressed" 3 "Floor_Pressed" 2 "Panel_Floor_Pressed" 1 "Panel_Pressed" 0 "None_Pressed" ;
VAL_ 866 Frt_Btn_Status_2nd 36 "MdeMnu_Pressed" 35 "AAR_Pressed" 34 "Heat_Pressed" 33 "RearMnu_Pressed" 32 "FrontMnu_Pressed" 63 "NotUsed_10" 62 "NotUsed_9" 61 "NotUsed_8" 60 "NotUsed_7" 59 "NotUsed_6" 58 "AUTO_Dec_Pressed" 57 "AUTO_Inc_Pressed" 56 "AUTO_Hi_Pressed" 55 "AUTO_Med_Pressed" 54 "AUTO_Lo_Pressed" 53 "RHS_Cld_Seat3_Pressed" 52 "RHS_Cld_Seat2_Pressed" 51 "RHS_Cld_Seat1_Pressed" 50 "LHS_Cld_Seat3_Pressed" 49 "LHS_Cld_Seat2_Pressed" 48 "LHS_Cld_Seat1_Pressed" 47 "RHS_Auto_Seat_Pressed" 46 "RHS_Htd_Seat3_Pressed" 45 "RHS_Htd_Seat2_Pressed" 44 "RHS_Htd_Seat1_Pressed" 43 "RHS_Seat_Off_Pressed" 42 "LHS_Auto_Seat_Pressed" 41 "LHS_Htd_Seat3_Pressed" 40 "LHS_Htd_Seat2_Pressed" 39 "LHS_Htd_Seat1_Pressed" 38 "LHS_Seat_Off_Pressed" 37 "DrvrFcsdMde_Pressed" 31 "Defrost_Pressed" 30 "Htg_Strg_Whl_Pressed" 29 "RHS_Cld_Seat_Pressed" 28 "LHS_Cld_Seat_Pressed" 27 "RHS_Htd_Seat_Pressed" 26 "LHS_Htd_Seat_Pressed" 25 "Max_Defrost_Pressed" 24 "My_Temp_Pressed" 23 "Front_Power_Pressed" 22 "Rear_Defrost_Pressed" 21 "Pnl_Flr_Ws_Pressed" 20 "Pnl_Ws_Pressed" 19 "Windscreen_Pressed" 18 "Htd_Frt_Wsh_Pressed" 17 "Auto_Recirc_Pressed" 16 "Outside_Pressed" 15 "Recirc_Pressed" 14 "Max_AC_Pressed" 13 "AUTO_Pressed" 12 "Blwr_Dec_Pressed" 11 "Blwr_Inc_Pressed" 10 "RHS_Temp_Dec_Pressed" 9 "RHS_Temp_Inc_Pressed" 8 "LHS_Temp_Dec_Pressed" 7 "LHS_Temp_Inc_Pressed" 6 "Dual_Pressed" 5 "AC_Pressed" 4 "Floor_Ws_Pressed" 3 "Floor_Pressed" 2 "Panel_Floor_Pressed" 1 "Panel_Pressed" 0 "None_Pressed" ;
VAL_ 866 Frt_Btn_Status_1st 36 "MdeMnu_Pressed" 35 "AAR_Pressed" 34 "Heat_Pressed" 33 "RearMnu_Pressed" 32 "FrontMnu_Pressed" 63 "NotUsed_10" 62 "NotUsed_9" 61 "NotUsed_8" 60 "NotUsed_7" 59 "NotUsed_6" 58 "AUTO_Dec_Pressed" 57 "AUTO_Inc_Pressed" 56 "AUTO_Hi_Pressed" 55 "AUTO_Med_Pressed" 54 "AUTO_Lo_Pressed" 53 "RHS_Cld_Seat3_Pressed" 52 "RHS_Cld_Seat2_Pressed" 51 "RHS_Cld_Seat1_Pressed" 50 "LHS_Cld_Seat3_Pressed" 49 "LHS_Cld_Seat2_Pressed" 48 "LHS_Cld_Seat1_Pressed" 47 "RHS_Auto_Seat_Pressed" 46 "RHS_Htd_Seat3_Pressed" 45 "RHS_Htd_Seat2_Pressed" 44 "RHS_Htd_Seat1_Pressed" 43 "RHS_Seat_Off_Pressed" 42 "LHS_Auto_Seat_Pressed" 41 "LHS_Htd_Seat3_Pressed" 40 "LHS_Htd_Seat2_Pressed" 39 "LHS_Htd_Seat1_Pressed" 38 "LHS_Seat_Off_Pressed" 37 "DrvrFcsdMde_Pressed" 31 "Defrost_Pressed" 30 "Htg_Strg_Whl_Pressed" 29 "RHS_Cld_Seat_Pressed" 28 "LHS_Cld_Seat_Pressed" 27 "RHS_Htd_Seat_Pressed" 26 "LHS_Htd_Seat_Pressed" 25 "Max_Defrost_Pressed" 24 "My_Temp_Pressed" 23 "Front_Power_Pressed" 22 "Rear_Defrost_Pressed" 21 "Pnl_Flr_Ws_Pressed" 20 "Pnl_Ws_Pressed" 19 "Windscreen_Pressed" 18 "Htd_Frt_Wsh_Pressed" 17 "Auto_Recirc_Pressed" 16 "Outside_Pressed" 15 "Recirc_Pressed" 14 "Max_AC_Pressed" 13 "AUTO_Pressed" 12 "Blwr_Dec_Pressed" 11 "Blwr_Inc_Pressed" 10 "RHS_Temp_Dec_Pressed" 9 "RHS_Temp_Inc_Pressed" 8 "LHS_Temp_Dec_Pressed" 7 "LHS_Temp_Inc_Pressed" 6 "Dual_Pressed" 5 "AC_Pressed" 4 "Floor_Ws_Pressed" 3 "Floor_Pressed" 2 "Panel_Floor_Pressed" 1 "Panel_Pressed" 0 "None_Pressed" ;
VAL_ 866 Frt_Blower_Speed 3 "NotUsed" 2 "Max_Blower" 1 "Min_Blower" 0 "No_Request" ;
VAL_ 866 Drv_Set_Temp 31 "HI" 30 "29_5" 29 "29_0" 28 "28_5" 27 "28_0" 26 "27_5" 25 "27_0" 24 "26_5" 23 "26_0" 22 "25_5" 21 "25_0" 20 "24_5" 19 "24_0" 18 "23_5" 17 "23_0" 16 "22_5" 15 "22_0" 14 "21_5" 13 "21_0" 12 "20_5" 11 "20_0" 10 "19_5" 9 "19_0" 8 "18_5" 7 "18_0" 6 "17_5" 5 "17_0" 4 "16_5" 3 "16_0" 2 "15_5" 1 "LO" 0 "No_Request" ;
VAL_ 861 Rr_Temp_Detents 15 "Unused5" 14 "Unused4" 13 "Unused3" 12 "Unused2" 11 "Unused1" 10 "Display_Blank" 9 "_4_Heat_Bars" 8 "_3_Heat_Bars" 7 "_2_Heat_Bars" 6 "_1_Heat_Bar" 5 "Neutral_Bar_Only" 4 "_1_Cool_Bar" 3 "_2_Cool_Bars" 2 "_3_Cool_Bars" 1 "_4_Cool_Bars" 0 "No_Bars" ;
VAL_ 861 Rr_Power_Btn_Stt 3 "Unused" 2 "Disabled" 1 "Active" 0 "Enabled_Inactive" ;
VAL_ 861 Rr_RH_Cond_Seat_Stat 7 "Unused" 6 "Level_3_Heating" 5 "Level_2_Heating" 4 "Level_1_Heating" 3 "Level_3_Cooling" 2 "Level_2_Cooling" 1 "Level_1_Cooling" 0 "Off" ;
VAL_ 861 Rr_Pnl_Flr_Btn_Stt 3 "Unused" 2 "Disabled" 1 "Active" 0 "Enabled_Inactive" ;
VAL_ 861 Rr_LH_Cond_Seat_Stat 7 "Unused" 6 "Level_3_Heating" 5 "Level_2_Heating" 4 "Level_1_Heating" 3 "Level_3_Cooling" 2 "Level_2_Cooling" 1 "Level_1_Cooling" 0 "Off" ;
VAL_ 861 CC_Rr_Stat_User_Adj 15 "Unused9" 14 "Unused8" 13 "Unused7" 12 "Unused6" 11 "Unused5" 10 "Unused4" 9 "Unused3" 8 "Unused2" 7 "Unused1" 6 "Rr_Auto_Selection" 5 "Rr_Control_Selection" 4 "Rr_Power_Selection" 3 "Rr_Blwr_Spd_Selection" 2 "RRHS_SetPt_Selection" 1 "RLHS_SetPt_Selection" 0 "None" ;
VAL_ 861 Rr_Set_Temp_Units 2 "Fahrenheit" 1 "Celsius" 0 "Off" ;
VAL_ 861 Rr_RHS_Set_Temp_Dig3 2 "_5" 1 "_0" 0 "Off" ;
VAL_ 861 Rr_RHS_Set_Temp_Dig2 15 "Blank2" 14 "Blank1" 13 "I" 12 "H" 11 "O" 10 "L" 9 "_9" 8 "_8" 7 "_7" 6 "_6" 5 "_5" 4 "_4" 3 "_3" 2 "_2" 1 "_1" 0 "_0" ;
VAL_ 861 Rr_RHS_Set_Temp_Dig1 15 "Blank2" 14 "Blank1" 13 "I" 12 "H" 11 "O" 10 "L" 9 "_9" 8 "_8" 7 "_7" 6 "_6" 5 "_5" 4 "_4" 3 "_3" 2 "_2" 1 "_1" 0 "_0" ;
VAL_ 861 Rr_RH_Htd_Seat_Btn_Stt 3 "Unused" 2 "Disabled" 1 "Active" 0 "Enabled_Inactive" ;
VAL_ 861 Rr_RH_Cld_Seat_Btn_Stt 3 "Unused" 2 "Disabled" 1 "Active" 0 "Enabled_Inactive" ;
VAL_ 861 Rr_Panel_Btn_Stt 3 "Unused" 2 "Disabled" 1 "Active" 0 "Enabled_Inactive" ;
VAL_ 861 Rr_On_Indicator 1 "On" 0 "Off" ;
VAL_ 861 Rr_LHS_Set_Temp_Dig3 2 "_5" 1 "_0" 0 "Off" ;
VAL_ 861 Rr_LHS_Set_Temp_Dig2 15 "Blank2" 14 "Blank1" 13 "I" 12 "H" 11 "O" 10 "L" 9 "_9" 8 "_8" 7 "_7" 6 "_6" 5 "_5" 4 "_4" 3 "_3" 2 "_2" 1 "_1" 0 "_0" ;
VAL_ 861 Rr_LHS_Set_Temp_Dig1 15 "Blank2" 14 "Blank1" 13 "I" 12 "H" 11 "O" 10 "L" 9 "_9" 8 "_8" 7 "_7" 6 "_6" 5 "_5" 4 "_4" 3 "_3" 2 "_2" 1 "_1" 0 "_0" ;
VAL_ 861 Rr_LH_Htd_Seat_Btn_Stt 3 "Unused" 2 "Disabled" 1 "Active" 0 "Enabled_Inactive" ;
VAL_ 861 Rr_LH_Cld_Seat_Btn_Stt 3 "Unused" 2 "Disabled" 1 "Active" 0 "Enabled_Inactive" ;
VAL_ 861 Rr_Floor_Btn_Stt 3 "Unused" 2 "Disabled" 1 "Active" 0 "Enabled_Inactive" ;
VAL_ 861 Rr_Control_Btn_Stt 3 "Unused" 2 "Disabled" 1 "Active" 0 "Enabled_Inactive" ;
VAL_ 861 Rr_Blower_Indicate 15 "Display_Blank" 14 "14_Indicators_On" 13 "13_Indicators_On" 12 "12_Indicators_On" 11 "11_Indicators_On" 10 "10_Indicators_On" 9 "9_Indicators_On" 8 "8_Indicators_On" 7 "7_Indicators_On" 6 "6_Indicators_On" 5 "5_Indicators_On" 4 "4_Indicators_On" 3 "3_Indicators_On" 2 "2_Indicators_On" 1 "1_Indicator_On" 0 "Indicators_Off" ;
VAL_ 861 Rr_AUTO_Btn_Stt 3 "Unused" 2 "Disabled" 1 "Active" 0 "Enabled_Inactive" ;
VAL_ 865 Dsp_RotAddrBtnEv_St 15 "NotUsed_1" 14 "Pos_7Steps" 13 "Pos_6Steps" 12 "Pos_5Steps" 11 "Pos_4Steps" 10 "Pos_3Steps" 9 "Pos_2Steps" 8 "Pos_1Step" 7 "NotPressed" 6 "Neg_1Steps" 5 "Neg_2Steps" 4 "Neg_3Steps" 3 "Neg_4Steps" 2 "Neg_5Steps" 1 "Neg_6Steps" 0 "Neg_7Steps" ;
VAL_ 865 SelDrvMdeButtn_B_Stat 1 "Pressed" 0 "Not_Pressed" ;
VAL_ 865 SteEffortButtn_B_Stat 1 "Pressed" 0 "Not_Pressed" ;
VAL_ 865 SelDrvMdeSwtch_D_Stat2 3 "Faulty" 2 "SwitchState2" 1 "SwitchState1" 0 "NotPressed" ;
VAL_ 865 EngExhMdeQuiet_B_RqDrv 1 "Pressed" 0 "Not_Pressed" ;
VAL_ 865 LnchCtlSys_B_RqDrv 1 "Pressed" 0 "Not_Pressed" ;
VAL_ 865 CC_Fr_Stat_User_Adj 7 "Unused4" 6 "RHS_AUTO_St_Selection" 5 "LHS_AUTO_St_Selection" 4 "DrvrFcsdMde_Selection" 3 "Fr_Blwr_Spd_Selection" 2 "FRHS_SetPt_Selection" 1 "FLHS_SetPt_Selection" 0 "None" ;
VAL_ 865 RHS_Auto_Seat_Btn_Stt 3 "Unused" 2 "Disabled" 1 "Active" 0 "Enabled_Inactive" ;
VAL_ 865 Front_Blower_Indicate 15 "Display_Blank" 14 "14_Indicators_On" 13 "13_Indicators_On" 12 "12_Indicators_On" 11 "11_Indicators_On" 10 "10_Indicators_On" 9 "9_Indicators_On" 8 "8_Indicators_On" 7 "7_Indicators_On" 6 "6_Indicators_On" 5 "5_Indicators_On" 4 "4_Indicators_On" 3 "3_Indicators_On" 2 "2_Indicators_On" 1 "1_Indicator_On" 0 "Indicators_Off" ;
VAL_ 865 CC_Diagnostics_Active 1 "Yes" 0 "No" ;
VAL_ 865 RHS_Temp_Display_Digit3 2 "_5" 1 "_0" 0 "OFF" ;
VAL_ 865 LHS_Temp_Display_Digit3 2 "_5" 1 "_0" 0 "OFF" ;
VAL_ 865 EATC_RHS_Units 2 "Fahrenheit" 1 "Celsius" 0 "Off" ;
VAL_ 865 EATC_LHS_Units 2 "Fahrenheit" 1 "Celsius" 0 "Off" ;
VAL_ 865 LHS_Auto_Seat_Btn_Stt 3 "Unused" 2 "Disabled" 1 "Active" 0 "Enabled_Inactive" ;
VAL_ 1046 PrkBrkDynmc_D_Allw 3 "NotUsed" 2 "EPB_ECD_NotPossible" 1 "EPB_ECD_Possible" 0 "Used_at_Start_Up" ;
VAL_ 1046 BrkPrkBrkDynmc_B_Actl 1 "Active" 0 "Inactive" ;
VAL_ 1046 TRLR_SWAY_EVNT_IN_PROG 1 "Yes" 0 "No" ;
VAL_ 1046 TRLR_SWAY_CONFIG_STAT 1 "On" 0 "Off" ;
VAL_ 1046 HsaMde_D_Mem 3 "Undefined" 2 "Manual" 1 "Automatic" 0 "Off" ;
VAL_ 1046 BrkBstrVac_B_Rq 1 "Yes" 0 "No" ;
VAL_ 1046 DrvSlipCtlMde_D_Ind 3 "App_Specific_Off_Mode_3" 2 "App_Specific_Off_Mode_2" 1 "App_Specific_Off_Mode_1" 0 "Default_Mode" ;
VAL_ 1046 DrvSlipCtlLamp_D_Rq 3 "Fast_Flash" 2 "Slow_Flash" 1 "On" 0 "Off" ;
VAL_ 1046 TCMode 1 "Active" 0 "Inactive" ;
VAL_ 1046 HILL_DESC_MC 7 "Fault_Detected" 6 "Cooling_Down" 5 "Abort_Apply_Brakes" 4 "Active" 3 "Disabled" 2 "Enabled" 1 "Off_Road" 0 "Normal" ;
VAL_ 1046 DrvAntiLckLamp_D_Rq 3 "Fast_Flash" 2 "Slow_Flash" 1 "On" 0 "Off" ;
VAL_ 1046 ChimeBrk_B_Rq 1 "Yes" 0 "No" ;
VAL_ 1046 BrkLamp_B_Rq 1 "Yes" 0 "No" ;
VAL_ 1046 Abs_B_Falt 1 "Yes" 0 "No" ;
VAL_ 1046 StabCtlBrk_B_Avail 1 "Yes" 0 "No" ;
VAL_ 1046 DrvHdcWarnInfo_D_Rq 3 "Undefined" 2 "Lamp_On_Continuously" 1 "Lamp_Flashing" 0 "Lamp_Off_Continuously" ;
VAL_ 1046 DrvHdcMsg_D_Rq 7 "Undefined" 6 "Speed_too_High" 5 "Temporarily_Unavailable" 4 "System_Fault" 3 "Select_Gear" 2 "Off" 1 "On" 0 "No_Message" ;
VAL_ 1046 DrvHdcLampInfo_D_Rq 3 "Fast_Flash" 2 "Slow_Flash" 1 "On" 0 "Off" ;
VAL_ 1046 RearDiffElckrOpen_B_Rq 1 "Yes" 0 "No" ;
VAL_ 1046 BpedMove_D_Actl 3 "Unknown" 2 "DriverApplyingBrakePedal" 1 "NoAutonomousBrkPdlMovement" 0 "AutonomousBrkPedalMove" ;
VAL_ 1046 RearDiffLck_Tq2_RqMx 4095 "Faulty" ;
VAL_ 1046 HdcMde_D_Actl 7 "Fault" 6 "Temporarily_Unavailable" 5 "NotEnabled_WrongGearSel" 4 "NotEnabled_SpdLimitExceed" 3 "Active_Braking" 2 "Not_Active_Braking" 1 "Off" 0 "Undefined" ;
VAL_ 534 WhlDirRr_D_Actl 3 "Faulty" 2 "NoDataExists" 1 "Backward" 0 "Forward" ;
VAL_ 534 WhlDirRl_D_Actl 3 "Faulty" 2 "NoDataExists" 1 "Backward" 0 "Forward" ;
VAL_ 534 WhlDirFr_D_Actl 3 "Faulty" 2 "NoDataExists" 1 "Backward" 0 "Forward" ;
VAL_ 534 WhlDirFl_D_Actl 3 "Faulty" 2 "NoDataExists" 1 "Backward" 0 "Forward" ;
VAL_ 402 CamraFrntBttn_D_Stat3 1 "Pressed" 0 "Not_Pressed" ;
VAL_ 402 PrkAidSwtch_D_RqMnu 1 "Pressed" 0 "Not_Pressed" ;
VAL_ 402 ApaSwtch_D_RqMnu 3 "NotUsed2" 2 "NotUsed1" 1 "Pressed" 0 "Not_Pressed" ;
VAL_ 402 ApaSlotAlrtSet_D_RqDrv 3 "TemporarySuppression" 2 "Disable" 1 "Enable" 0 "None" ;
VAL_ 402 ApaSlotTrgt_D_RqDrv 15 "NotUsed_7" 14 "NotUsed_6" 13 "NotUsed_5" 12 "NotUsed_4" 11 "NotUsed_3" 10 "NotUsed_2" 9 "NotUsed_1" 8 "Front" 7 "Rear" 6 "Right3" 5 "Right2" 4 "Right1" 3 "Left3" 2 "Left2" 1 "Left1" 0 "None" ;
VAL_ 402 ApaMdeStat_D_RqDrv 7 "Faulty" 6 "Off" 5 "NotUsed2" 4 "NotUsed1" 3 "POA" 2 "PPA" 1 "SAPP" 0 "Inactive" ;
VAL_ 402 ApaFeat_D_RqDrv 7 "Faulty" 6 "Off" 5 "RePA" 4 "ParkIn" 3 "POA" 2 "PPA" 1 "SAPP" 0 "Inactive" ;
VAL_ 402 ApaFeatChange_B_RqDrv 1 "True" 0 "False" ;
VAL_ 402 CamraViewSplit_B_Rq 1 "On" 0 "Off" ;
VAL_ 402 CamraZoomMan_D_Rq 7 "Unknown" 6 "Invalid" 5 "Zoom_Level_V" 4 "Zoom_Level_IV" 3 "Zoom_Level_III" 2 "Zoom_Level_II" 1 "Zoom_Level_I" 0 "Off" ;
VAL_ 402 CamraOvrlStat_D_Rq 1 "On" 0 "Off" ;
VAL_ 402 CamraOvrlDyn_D_Rq 1 "On" 0 "Off" ;
VAL_ 402 CamAutoTowbarZoom 1 "On" 0 "Off" ;
VAL_ 402 DistanceBarSetting 1 "On" 0 "Off" ;
VAL_ 946 ValetMode_D_Mem 1 "On" 0 "Off" ;
VAL_ 946 DrStatDrvErrCnt_B_Stat 1 "Yes" 0 "No" ;
VAL_ 946 Backlit_LED_Status 15 "Unused3" 14 "Unused2" 13 "Unused1" 12 "Night_12" 11 "Night_11" 10 "Night_10" 9 "Night_9" 8 "Night_8" 7 "Night_7" 6 "Night_6" 5 "Night_5" 4 "Night_4" 3 "Night_3" 2 "Night_2" 1 "Night_1" 0 "Off" ;
VAL_ 946 TurnLghtRightOn_B_Stat 1 "On" 0 "Off" ;
VAL_ 946 TurnLghtLeftOn_B_Stat 1 "On" 0 "Off" ;
VAL_ 946 FogLghtRearOn_B_Stat 1 "On" 0 "Off" ;
VAL_ 946 TurnLghtRight_D_Rq 3 "Seq" 2 "On" 1 "Off" 0 "Null" ;
VAL_ 946 IgnKeyType_D_Actl 15 "Invalid" 14 "Unknown" 3 "Key_Not_Prgrm_Read_Failure" 2 "Key_In_Ign_My_Key" 1 "Key_In_Ign_Standard_Key" 0 "Key_Read_In_Progress" ;
VAL_ 946 Parklamp_Status 3 "Invalid" 2 "Unknown" 1 "On" 0 "Off" ;
VAL_ 946 Litval 255 "Invalid" 254 "Unknown" 5 "Day" 4 "Twilight_4" 3 "Twilight_3" 2 "Twilight_2" 1 "Twilight_1" 0 "Night" ;
VAL_ 946 Key_In_Ignition_Stat 1 "In" 0 "Out" ;
VAL_ 946 Ignition_Status 0 "Unknown" 1 "Off" 15 "Invalid" 8 "Start" 4 "Run" 2 "Accessory" ;
VAL_ 946 Dimming_Lvl 255 "Invalid" 254 "Unknown" 18 "Day_6" 17 "Day_5" 16 "Day_4" 15 "Day_3" 14 "Day_2" 13 "Day_1" 12 "Night_12" 11 "Night_11" 10 "Night_10" 9 "Night_9" 8 "Night_8" 7 "Night_7" 6 "Night_6" 5 "Night_5" 4 "Night_4" 3 "Night_3" 2 "Night_2" 1 "Night_1" 0 "Off" ;
VAL_ 946 Day_Night_Status 3 "NotUsed" 2 "Night" 1 "Day" 0 "Null" ;
VAL_ 946 Remote_Start_Status 3 "Invalid" 2 "Unknown" 1 "Remote" 0 "Null" ;
VAL_ 946 DrStatTgate_B_Actl 1 "Ajar" 0 "Closed" ;
VAL_ 946 DrStatRr_B_Actl 1 "Ajar" 0 "Closed" ;
VAL_ 946 DrStatRl_B_Actl 1 "Ajar" 0 "Closed" ;
VAL_ 946 DrStatPsngr_B_Actl 1 "Ajar" 0 "Closed" ;
VAL_ 946 FogLghtFrontOn_B_Stat 1 "On" 0 "Off" ;
VAL_ 946 DrStatInnrTgate_B_Actl 1 "Ajar" 0 "Closed" ;
VAL_ 946 DrStatHood_B_Actl 1 "Ajar" 0 "Closed" ;
VAL_ 946 DrStatDrv_B_Actl 1 "Ajar" 0 "Closed" ;
VAL_ 946 PrkBrkActv_B_Actl 1 "Active" 0 "Inactive" ;
VAL_ 946 LifeCycMde_D_Actl 3 "Transport" 2 "NotUsed" 1 "Factory" 0 "Normal" ;
VAL_ 946 Delay_Accy 1 "On" 0 "Off" ;
VAL_ 946 TurnLghtLeft_D_Rq 3 "Seq" 2 "On" 1 "Off" 0 "Null" ;
VAL_ 946 CrashEvnt_D_Stat 3 "Invalid" 2 "Fuel_Cutoff_Event" 1 "Deploy_Event" 0 "No_Event" ;
VAL_ 946 FuelPmpInhbt_B_Stat 1 "Inhibit" 0 "No_Inibit" ;
VAL_ 946 BodySrvcRqd_B_Rq 1 "Yes" 0 "No" ;
VAL_ 778 PrkAidAcsyRear_D_RqDrv 3 "NotUsed" 2 "On" 1 "Off" 0 "Null" ;
VAL_ 778 PrkAidAcsyFront_D_RqDrv 3 "NotUsed" 2 "On" 1 "Off" 0 "Null" ;
VAL_ 778 Cta_D_Rq 3 "Unused" 2 "NoDataExists" 1 "On" 0 "Off" ;
VAL_ 778 PrkAidRear_D_RqDrv 2 "Status" 3 "NotUsed" 1 "Enabled" 0 "Disabled" ;
VAL_ 778 PrkAidFront_D_RqDrv 2 "Status" 3 "NotUsed" 1 "Enabled" 0 "Disabled" ;
VAL_ 778 SteEffort_D_Rq 7 "NotUsed_3" 6 "NotUsed_2" 5 "NotUsed_1" 4 "SpecialMode_2" 3 "SpecialMode_1" 2 "Comfort" 1 "Sport" 0 "Normal" ;
VAL_ 778 ClrExitAsstEnbl_D_RqDrv 3 "NotUsed" 0 "Inactive" 2 "Enable" 1 "Disable" ;
VAL_ 778 Sod_D_Rq 2 "BLIS_On_Second_Warning_ON" 1 "BLIS_On_Second_Warning_OFF" 0 "Off" ;
VAL_ 1093 TrlBrkInitOut_D_Stat 3 "Heavy" 2 "Medium" 1 "Light" 0 "Null" ;
VAL_ 1093 TrlrBrkMde_D_Actl 1 "Electric_Over_Hydraulic" 0 "Electric" ;
VAL_ 1093 TrlrBrkDsply_B_Rq 1 "Yes" 0 "No" ;
VAL_ 1093 TrlrBrkDcnnt_B_Actl 1 "Yes" 0 "No" ;
VAL_ 1093 TrlrBrkActCnnct_B_Actl 1 "Yes" 0 "No" ;
VAL_ 1093 StopLamp_B_RqTrlrBrk 1 "Yes" 0 "No" ;
VAL_ 1093 TrlrBrkCtl_B_Falt 1 "Yes" 0 "No" ;
VAL_ 1093 TrlrBrkActCirct_B_Falt 1 "Yes" 0 "No" ;
VAL_ 999 PersIndexFcim_D_Actl 7 "Unused_3" 6 "Unused_2" 5 "Unused_1" 4 "Vehicle" 3 "PERS_4" 2 "PERS_3" 1 "PERS_2" 0 "PERS_1" ;
VAL_ 1002 PersIndexApim_D_Actl 7 "Unused_3" 6 "Unused_2" 5 "Unused_1" 4 "Vehicle" 3 "PERS_4" 2 "PERS_3" 1 "PERS_2" 0 "PERS_1" ;
VAL_ 1002 CntrStk_D_RqRecall 7 "Unused_2" 6 "Unused_1" 5 "Vehicle" 4 "PERS_4" 3 "PERS_3" 2 "PERS_2" 1 "PERS_1" 0 "Null" ;
VAL_ 1002 CntrStk_D_RqAssoc 7 "Unused_2" 6 "Cancel" 5 "Set_Keycode" 4 "RKE" 3 "Null" 2 "Key" 1 "Erase_KeyCode" 0 "Check_KeyCode" ;
VAL_ 948 TlghtTestPrecnd_D2_Stat 7 "TrailerNotConnected" 6 "NotStationary" 5 "InteractionPresent" 4 "PreconditionsPassed" 3 "BattSocLessThan75Percent" 2 "TailLightsOn" 1 "IgnitionNotOn" 0 "Null" ;
VAL_ 948 TlghtTestLght_D2_Stat 7 "TestingRearFogLights" 6 "AllOff" 5 "TestingReverseLights" 4 "TestingBrakeLights" 3 "TestingLeftTurnSignal" 2 "TestingRightTurnSignal" 1 "ParkingLightsIlluminated" 0 "Null" ;
VAL_ 948 TirePReset_D_Stat 3 "Not_Used" 2 "Nack" 1 "Ack" 0 "Null" ;
VAL_ 948 Tire_Press_ILR_Stat 4 "Alert" 15 "Not_Supported" 3 "Fault" 2 "Low" 1 "Normal" 0 "Unknown" ;
VAL_ 948 Tire_Press_IRR_Stat 4 "Alert" 15 "Not_Supported" 3 "Fault" 2 "Low" 1 "Normal" 0 "Unknown" ;
VAL_ 948 Tire_Press_LR_OLR_Stat 4 "Alert" 15 "Not_Supported" 3 "Fault" 2 "Low" 1 "Normal" 0 "Unknown" ;
VAL_ 948 Tire_Press_RR_ORR_Stat 4 "Alert" 15 "Not_Supported" 3 "Fault" 2 "Low" 1 "Normal" 0 "Unknown" ;
VAL_ 948 Tire_Press_RF_Stat 4 "Alert" 15 "Not_Supported" 3 "Fault" 2 "Low" 1 "Normal" 0 "Unknown" ;
VAL_ 948 Tire_Press_LF_Stat 4 "Alert" 15 "Not_Supported" 3 "Fault" 2 "Low" 1 "Normal" 0 "Unknown" ;
VAL_ 948 Tire_Press_System_Stat 13 "Training_Complete" 12 "Train_InsideLeftRear_tire" 11 "Train_OutsideLeftRear_tire" 10 "Train_LeftRear_tire" 9 "Train_InsideRtRear_tire" 8 "Train_OutsideRtRear_tire" 7 "Train_RightRear_tire" 14 "Tires_not_trained" 6 "Train_RightFront_tire" 5 "Train_LeftFront_tire" 4 "Systm_Activ_Composite_Stat" 3 "Low_Composite_Stat" 2 "Sensr_Fault_Composite_Stat" 1 "Systm_Fault_Composite_Stat" 0 "Unknown_Composite_Stat" ;
VAL_ 948 Tire_Press_Telltale 3 "Not_Used" 2 "Flash" 1 "On" 0 "Off" ;
VAL_ 986 VehPayloadScrn_D_Rq 7 "CheckLoadScreenActive" 6 "WeightCarryScreenActive" 5 "GooseneckScreenActive" 4 "FifthWheelScreenActive" 3 "WeightDistScreenActive" 2 "AddMassEstScreenActive" 1 "PayloadEstScreenActive" 0 "ScaleScreenNotActive" ;
VAL_ 986 Trlr_M_Rq 2047 "Faulty" 2046 "NoDataExists" ;
VAL_ 986 VehPayloadTare_D_Rq 1 "Request" 0 "NoRequest" ;
VAL_ 986 VehFalr_D_Rq 7 "NotUsed_3" 6 "NotUsed_2" 5 "NotUsed_1" 4 "NotComplete" 3 "Complete" 2 "RequestSecondMeasurement" 1 "RequestFirstMeasurement" 0 "NoRequest" ;
VAL_ 986 TailLghtLoadMde_D_Rq 7 "NotUsed_3" 6 "NotUsed_2" 5 "NotUsed_1" 4 "DeactivateAll" 3 "ActivateFalrMode" 2 "ActivateHitchLoadMode" 1 "ActivatePayloadMode" 0 "NoCommand" ;
VAL_ 986 LightAmbIntsty_No_Rq 0 "Off" ;
VAL_ 993 StmsScrnDrvOn_B_Rq 1 "On" 0 "Off" ;
VAL_ 993 EmButtn_D_Stat 7 "ButtonAssociationFailed" 6 "ButtonAssociationExited" 5 "ButtonAssociationEntered" 4 "Button4Pressed" 3 "Button3Pressed" 2 "Button2Pressed" 1 "Button1Pressed" 0 "Null" ;
VAL_ 993 MemStoreMsgTxt_D_Rq 10 "NotUsed_2" 9 "NotUsed_1" 8 "Mem4Saved_ShowLinkMsg" 7 "Mem3Saved_ShowLinkMsg" 6 "Mem2Saved_ShowLinkMsg" 5 "Mem1Saved_ShowLinkMsg" 4 "Mem4Saved_DoNotShowLinkMsg" 3 "Mem3Saved_DoNotShowLinkMsg" 2 "Mem2Saved_DoNotShowLinkMsg" 1 "Mem1Saved_DoNotShowLinkMsg" 0 "Null" ;
VAL_ 993 MemSetButtnMsgTxt_D_Rq 3 "NotUsed" 2 "Press1or2or3" 1 "Press1or2" 0 "Null" ;
VAL_ 993 MemSwtch_D_RqRecall 7 "Unused_3" 6 "Unused_2" 5 "Unused_1" 4 "PERS_4" 3 "PERS_3" 2 "PERS_2" 1 "PERS_1" 0 "Null" ;
VAL_ 993 MemSwtch_D_RqAssoc 7 "Unused_3" 6 "Unused_2" 5 "Unused_1" 4 "PERS_4" 3 "PERS_3" 2 "PERS_2" 1 "PERS_1" 0 "Null" ;
VAL_ 993 PersIndexDsm_D_Actl 7 "Unused_3" 6 "Unused_2" 5 "Unused_1" 4 "Vehicle" 3 "PERS_4" 2 "PERS_3" 1 "PERS_2" 0 "PERS_1" ;
VAL_ 993 PersStore_D_Actl 3 "Unused" 2 "Null" 1 "InProgress" 0 "Complete" ;
VAL_ 997 PersTurnSglView_D_Stat 3 "NotConfigured" 2 "Enabled" 1 "Disabled" 0 "Null" ;
VAL_ 997 PersIndexCcm_D_Actl 7 "Unused_3" 6 "Unused_2" 5 "Unused_1" 4 "Vehicle" 3 "PERS_4" 2 "PERS_3" 1 "PERS_2" 0 "PERS_1" ;
VAL_ 487 Aioc_SetExtSrcOutpMd_Rq 5 "AllocateUSBToOutput" 4 "AllocateBtAudioToOutput" 3 "AllocateBtNavigationToOut" 2 "AllocateBtPhoneToOutput" 1 "AllocateVrAudioToOutput" 0 "Inactive" 8 "DeallocateOutput" 7 "AllocateAUX3" 6 "AllocateiPodToOutput" ;
VAL_ 464 SdarsSampleRate_D_Rq 3 "NotUsed" 2 "SampleRate_48000Hz" 1 "SampleRate_44100Hz" 0 "Null" ;
VAL_ 864 MdeMnu_Buttn_Stat 1 "Pressed" 0 "Not_Pressed" ;
VAL_ 864 Front_AUTO_Blwr_Lvl 3 "High" 2 "Medium" 1 "Low" 0 "Off" ;
VAL_ 864 RearMnu_Buttn_Stat 1 "Pressed" 0 "Not_Pressed" ;
VAL_ 864 FrontMnu_Buttn_Stat 1 "Pressed" 0 "Not_Pressed" ;
VAL_ 864 DrvrFcsdMde_Btn_Stt 3 "Unused" 2 "Disabled" 1 "Active" 0 "Enabled_Inactive" ;
VAL_ 864 RHS_Cond_Seat_Status 7 "Unused" 6 "Level_3_Heating" 5 "Level_2_Heating" 4 "Level_1_Heating" 3 "Level_3_Cooling" 2 "Level_2_Cooling" 1 "Level_1_Cooling" 0 "Off" ;
VAL_ 864 LHS_Cond_Seat_Status 7 "Unused" 6 "Level_3_Heating" 5 "Level_2_Heating" 4 "Level_1_Heating" 3 "Level_3_Cooling" 2 "Level_2_Cooling" 1 "Level_1_Cooling" 0 "Off" ;
VAL_ 864 Htd_Strg_Whl_Status 3 "Level_3_Heating" 2 "Level_2_Heating" 1 "Level_1_Heating" 0 "Off" ;
VAL_ 864 Htd_Strg_Whl_Btn_Stt 3 "Unused" 2 "Disabled" 1 "Active" 0 "Enabled_Inactive" ;
VAL_ 864 Defrost_Btn_Stt 3 "Unused" 2 "Disabled" 1 "Active" 0 "Enabled_Inactive" ;
VAL_ 864 CC_Fr_Btn_User_Adj 31 "Unused15" 30 "Unused14" 29 "Unused13" 28 "Unused12" 27 "Unused11" 26 "Unused10" 25 "Unused9" 24 "Unused8" 23 "Unused7" 22 "Unused6" 21 "RHS_Cld_St_Selection" 20 "LHS_Cld_St_Selection" 19 "UFC_Interrupted" 18 "UFC_Complete" 17 "UFC_Active" 16 "Htd_WS_Selection" 15 "RHS_Htd_St_Selection" 14 "LHS_Htd_St_Selection" 13 "HSW_Selection" 12 "Dual_Selection" 11 "Rear_Defrost_Selection" 10 "Max_Defrost_Selection" 9 "Defrost_Selection" 8 "Fr_Air_Dist_Selection" 7 "Max_AC_Selection" 6 "Fr_Power_Selection" 5 "Recirc_Selection" 4 "AC_Selection" 3 "Fr_Auto_Selection" 2 "Use_MyTemp_Selection" 1 "Save_MyTemp_Selection" 0 "None" ;
VAL_ 864 RHS_Htd_Seat_Btn_Stt 3 "Unused" 2 "Disabled" 1 "Active" 0 "Enabled_Inactive" ;
VAL_ 864 RHS_Cld_Seat_Btn_Stt 3 "Unused" 2 "Disabled" 1 "Active" 0 "Enabled_Inactive" ;
VAL_ 864 Outside_Btn_Stt 3 "Unused" 2 "Disabled" 1 "Active" 0 "Enabled_Inactive" ;
VAL_ 864 LHS_Htd_Seat_Btn_Stt 3 "Unused" 2 "Disabled" 1 "Active" 0 "Enabled_Inactive" ;
VAL_ 864 LHS_Cld_Seat_Btn_Stt 3 "Unused" 2 "Disabled" 1 "Active" 0 "Enabled_Inactive" ;
VAL_ 864 Htd_Frt_Wsh_Btn_Stt 3 "Unused" 2 "Disabled" 1 "Active" 0 "Enabled_Inactive" ;
VAL_ 864 Auto_Recirc_Btn_Stt 3 "Unused" 2 "Disabled" 1 "Active" 0 "Enabled_Inactive" ;
VAL_ 864 Recirc_Btn_Stt 3 "Unused" 2 "Disabled" 1 "Active" 0 "Enabled_Inactive" ;
VAL_ 864 Rear_Defrost_Btn_Stt 3 "Unused" 2 "Disabled" 1 "Active" 0 "Enabled_Inactive" ;
VAL_ 864 My_Temp_Btn_Stt 3 "Unused" 2 "Disabled" 1 "Active" 0 "Enabled_Inactive" ;
VAL_ 864 Max_Defrost_Btn_Stt 3 "Unused" 2 "Disabled" 1 "Active" 0 "Enabled_Inactive" ;
VAL_ 864 Max_AC_Btn_Stt 3 "Unused" 2 "Disabled" 1 "Active" 0 "Enabled_Inactive" ;
VAL_ 864 Front_AUTO_Label 3 "Full" 2 "Mode" 1 "Blower" 0 "Off" ;
VAL_ 864 Windscreen_Btn_Stt 3 "Unused" 2 "Disabled" 1 "Active" 0 "Enabled_Inactive" ;
VAL_ 864 Panel_Btn_Stt 3 "Unused" 2 "Disabled" 1 "Active" 0 "Enabled_Inactive" ;
VAL_ 864 Front_Power_Btn_Stt 3 "Unused" 2 "Disabled" 1 "Active" 0 "Enabled_Inactive" ;
VAL_ 864 Front_AUTO_Btn_Stt 3 "Unused" 2 "Disabled" 1 "Active" 0 "Enabled_Inactive" ;
VAL_ 864 Floor_Btn_Stt 3 "Unused" 2 "Disabled" 1 "Active" 0 "Enabled_Inactive" ;
VAL_ 864 Dual_Button_Stt 3 "Unused" 2 "Disabled" 1 "Active" 0 "Enabled_Inactive" ;
VAL_ 864 AC_Btn_Stt 3 "Unused" 2 "Disabled" 1 "Active" 0 "Enabled_Inactive" ;
VAL_ 994 PersCtaSplitView_D_Rq 3 "EnabledFull" 2 "Enabled_180SwitchOnly" 1 "Disabled" 0 "Null" ;
VAL_ 994 Pers4OptIn_B_Stats 1 "OPTED_IN" 0 "NOT_OPTED_IN" ;
VAL_ 994 Pers3OptIn_B_Stats 1 "OPTED_IN" 0 "NOT_OPTED_IN" ;
VAL_ 994 Pers2OptIn_B_Stats 1 "OPTED_IN" 0 "NOT_OPTED_IN" ;
VAL_ 994 Pers1OptIn_B_Stats 1 "OPTED_IN" 0 "NOT_OPTED_IN" ;
VAL_ 994 CtrStkPersIndex_D_Actl 7 "Unused_3" 6 "Unused_2" 5 "Unused_1" 4 "Vehicle" 3 "PERS_4" 2 "PERS_3" 1 "PERS_2" 0 "PERS_1" ;
VAL_ 994 PersStore_D_Rq 7 "Unused_2" 6 "Unused_1" 5 "Vehicle" 4 "PERS_4" 3 "PERS_3" 2 "PERS_2" 1 "PERS_1" 0 "Null" ;
VAL_ 994 CtrStkDsplyOp_D_Rq 7 "Unused_2" 6 "Unused_1" 5 "Copy" 4 "Restore" 3 "Upload" 2 "Set" 1 "Query" 0 "Null" ;
VAL_ 394 AccStopStat_D_Dsply 3 "PressResume" 2 "Stopped" 1 "ResumeReady" 0 "NoDisplay" ;
VAL_ 394 AccTrgDist2_D_Dsply 15 "DIST_ACTIVE_13_Farthest" 14 "DIST_ACTIVE_12" 13 "DIST_ACTIVE_11" 12 "DIST_ACTIVE_10" 11 "DIST_ACTIVE_9" 10 "DIST_ACTIVE_8" 9 "DIST_ACTIVE_7" 8 "DIST_ACTIVE_6" 7 "DIST_ACTIVE_5" 6 "DIST_ACTIVE_4" 5 "DIST_ACTIVE_3" 4 "DIST_ACTIVE_2" 3 "DIST_ACTIVE_1_Closest" 2 "DIST_ACTIVE_No_Target" 1 "DIST_STANDBY" 0 "DIST_OFF" ;
VAL_ 394 AccStopRes_B_Dsply 1 "Yes" 0 "No" ;
VAL_ 394 TjaWarn_D_Rq 7 "HardTakeOverEyesOff" 6 "SoftTakeOverEyesOff" 5 "HaLaneDeptWarningLeft" 4 "HaLaneDeptWarningRight" 3 "HardTakeOverLevel2" 2 "HardTakeOverLevel1" 1 "TrafficJamAssistCancel" 0 "NoWarning" ;
VAL_ 394 Tja_D_Stat 7 "ExtendedActive" 6 "ActiveWarningRight" 5 "ActiveWarningLeft" 4 "ActiveInterventionRight" 3 "ActiveInterventionLeft" 2 "Active" 1 "Standby" 0 "Off" ;
VAL_ 394 IaccLamp_D_Rq 3 "NotUsed_2" 2 "NotUsed_1" 1 "DisplayIaccIcon" 0 "DoNotDisplayIaccIcon" ;
VAL_ 394 AccMsgTxt_D2_Rq 15 "Brakes_Warm" 14 "NCC_Enabled_Warning" 13 "IACC_TJA_Selected" 12 "ACC_TJA_Selected" 11 "IACC_Selected" 10 "Press_Brake_To_Hold" 9 "Only_Following_In_Low_Spd" 8 "TJA_Unavailable" 7 "Shift_Down" 6 "IACC_Unavailable" 5 "ACC_Selected" 4 "ACC_Overridden" 3 "Brake_Capacity_Warning" 2 "ACC_Cancelled" 1 "ACC_Unavailable" 0 "No_Text" ;
VAL_ 394 TjaMsgTxt_D_Dsply 7 "Disclaimer" 6 "SmartOffering" 5 "HaSelected" 4 "HaUnavailable" 3 "TurnOnAdaptCruiseControl" 2 "TrafficJamAssistSelected" 1 "TrafficJamAssistUnavailabl" 0 "NoMessage" ;
VAL_ 394 FcwDeny_B_Dsply 1 "Yes" 0 "No" ;
VAL_ 394 FcwMemStat_B_Actl 1 "On" 0 "Off" ;
VAL_ 394 AccTGap_B_Dsply 1 "Yes" 0 "No" ;
VAL_ 394 CadsAlignIncplt_B_Actl 1 "Yes" 0 "No" ;
VAL_ 394 AccFllwMde_B_Dsply 1 "Yes" 0 "No" ;
VAL_ 394 CadsRadrBlck_B_Actl 1 "Yes" 0 "No" ;
VAL_ 394 CmbbPostEvnt_B_Dsply 1 "Yes" 0 "No" ;
VAL_ 394 AccStopMde_B_Dsply 1 "Yes" 0 "No" ;
VAL_ 394 FcwMemSens_D_Actl 3 "FCW_Sensitivity_3" 2 "FCW_Sensitivity_2" 1 "FCW_Sensitivity_1" 0 "Not_Used" ;
VAL_ 394 FcwMsgTxt_D_Rq 7 "Undefined_3" 6 "Undefined_2" 5 "Low_Visibility" 4 "Unavailable_DueTo_LowSpeed" 3 "Available" 2 "Unavailable" 1 "Off" 0 "No_Text" ;
VAL_ 394 AccTGap_D_Dsply 7 "Undefined_2" 6 "Undefined_1" 5 "Time_Gap_5" 4 "Time_Gap_4" 3 "Time_Gap_3" 2 "Time_Gap_2" 1 "Time_Gap_1" 0 "Not_Used" ;
VAL_ 394 AccMemEnbl_B_RqDrv 1 "Adaptive_Cruise" 0 "Normal_Cruise" ;
VAL_ 394 AccWarn_D_Dsply 3 "BrakeReleaseWarn_In_StopMd" 2 "Brake_Capacity_Warning" 1 "Cancel_Warning" 0 "No_Warning" ;
VAL_ 394 FcwVisblWarn_B_Rq 1 "On" 0 "Off" ;
VAL_ 394 FcwAudioWarn_B_Rq 1 "On" 0 "Off" ;
VAL_ 1068 TrlrAidMsgTxt_D_Rq 31 "Message31" 30 "Message30" 29 "Message29" 28 "Message28" 27 "Message27" 26 "Message26" 25 "Message25" 24 "Message24" 23 "Message23" 22 "Message22" 21 "Message21" 20 "Message20" 19 "Message19" 18 "Message18" 17 "Message17" 16 "Message16" 15 "Message15" 14 "Message14" 13 "Message13" 12 "Message12" 11 "Message11" 10 "Message10" 9 "Message9" 8 "Message8" 7 "Message7" 6 "Message6" 5 "Message5" 4 "Message4" 3 "Message3" 2 "Message2" 1 "Message1" 0 "NoMessage" ;
VAL_ 1019 PersIndexIpc_D_Actl 7 "Unused_3" 6 "Unused_2" 5 "Unused_1" 4 "Vehicle" 3 "PERS_4" 2 "PERS_3" 1 "PERS_2" 0 "PERS_1" ;
VAL_ 909 IgnPsswrdDsply_B_Rq 1 "Active" 0 "Inactive" ;
VAL_ 909 ElPwPoint_D_Rq 3 "On" 2 "Off2" 1 "Off1" 0 "Null" ;
VAL_ 909 PoliceIdlMde_D_Stat 15 "NotUsed_7" 14 "NotUsed_6" 13 "NotUsed_5" 12 "NotUsed_4" 11 "NotUsed_3" 10 "UtilityIdleActive" 9 "PepsActive" 8 "Decommissioned" 7 "ActiveFault" 6 "ArmFault" 5 "PrearmedFault" 4 "OffFault" 3 "Active" 2 "Arm" 1 "Prearmed" 0 "Off" ;
VAL_ 909 DrLatchMsgTxt_D_Rq 7 "Message7" 6 "Message6" 5 "Message5" 4 "Message4" 3 "Message3" 2 "Message2" 1 "Message1" 0 "NoMessage" ;
VAL_ 909 WiprFront_D_Stat2 15 "NO_DATA_EXISTS" 14 "STALLED" 13 "NotUsed" 12 "AUTO_ADJUST" 11 "COURTESYWIPE" 10 "AUTO_HIGH" 9 "AUTO_LOW" 8 "WASH" 7 "MIST_FLICK" 6 "MAN_HIGH" 5 "MAN_LOW" 4 "MAN_INT_ON" 3 "MAN_INT_OFF" 2 "OFF_MOVING" 1 "AUTO_OFF" 0 "OFF" ;
VAL_ 909 HazrdLght_B_Stat 1 "On" 0 "Off" ;
VAL_ 909 TurnLghtSwtch_D_Stat2 3 "NotUsed" 2 "Right" 1 "Left" 0 "Off" ;
VAL_ 909 HeadLghtHiPrmsn_D_Stat 3 "CancelAndSuppress" 2 "Cancel" 1 "Hold" 0 "AllowChange" ;
VAL_ 909 SecurityMsgTxt_D_Rq 3 "Message3" 2 "Message2" 1 "Message1" 0 "NoMessage" ;
VAL_ 909 SteWhlLckMsgTxt_D_Rq 3 "Message_3" 2 "Message_2" 1 "Message_1" 0 "No_Message" ;
VAL_ 909 immoMsgTxt_D_Rq 15 "Immo_Msg_15" 14 "Immo_Msg_14" 13 "Immo_Msg_13" 12 "Immo_Msg_12" 11 "Immo_Msg_11" 10 "Immo_Msg_10" 9 "Immo_Msg_9" 8 "Immo_Msg_8" 7 "Immo_Msg_7" 6 "Immo_Msg_6" 5 "Immo_Msg_5" 4 "Immo_Msg_4" 3 "Immo_Msg_3" 2 "Immo_Msg_2" 1 "Immo_Msg_1" 0 "Immo_Msg_0_Null" ;
VAL_ 909 PrsnlDevcChrgEnbl_B_Rq 1 "Active" 0 "Inactive" ;
VAL_ 909 PrmtrAlrmEvnt_D_Stat 15 "Diag_Tamper" 14 "Trailer" 13 "Shock_Sensor" 12 "Post_Crash" 11 "Panic" 10 "Intrusion" 9 "Inclination" 8 "Ign_Tamper" 7 "LG_Door" 6 "Decklid" 5 "Hood" 4 "PR_Door" 3 "PF_Door" 2 "DR_Door" 1 "DF_Door" 0 "Null" ;
VAL_ 909 TracKeyMde_D_Stat 3 "NotUsed" 2 "NotActive" 1 "Active" 0 "ModeNotDetermined" ;
VAL_ 909 PEBackupSlot_Stats 3 "No_Valid_FOB_In_Slot" 2 "MyKey_FOB_In_Slot" 1 "Standard_FOB_In_Slot" 0 "Null" ;
VAL_ 909 KeyMykeyTot_No_Cnt 13 "Thirteen" 12 "Twelve" 11 "Eleven" 10 "Ten" 9 "Nine" 8 "Eight" 7 "Seven" 6 "Six" 5 "Five" 4 "Four" 3 "Three" 2 "Two" 1 "One" 0 "Zero" 15 "Invalid" 14 "Unlimited" ;
VAL_ 909 KeyAdmnTot_No_Cnt 13 "Thirteen" 12 "Twelve" 11 "Eleven" 10 "Ten" 9 "Nine" 8 "Eight" 7 "Seven" 6 "Six" 5 "Five" 4 "Four" 3 "Three" 2 "Two" 1 "One" 0 "Zero" 15 "Invalid" 14 "Unlimited" ;
